VERSION ""

NS_ :

BS_:

BU_: VMCU TECU TACHO RECU_Virt IC3 HPCU EMS EBS DACU CIOM BBM ACM

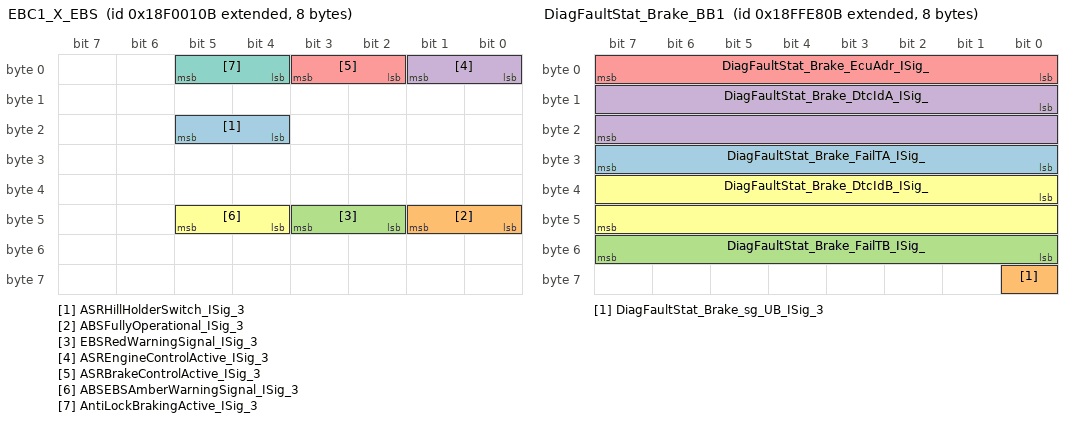
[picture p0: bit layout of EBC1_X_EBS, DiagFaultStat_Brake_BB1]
BO_ 2565865739 EBC1_X_EBS: 8 EBS
 SG_ ASRHillHolderSwitch_ISig_3 : 20|2@1+ (1,0) [0|0] ""  EMS,CIOM,IC3,BBM
 SG_ ABSFullyOperational_ISig_3 : 40|2@1+ (1,0) [0|0] ""  EMS,DACU,BBM,VMCU,TECU,IC3
 SG_ EBSRedWarningSignal_ISig_3 : 42|2@1+ (1,0) [0|0] ""  IC3,BBM
 SG_ ASREngineControlActive_ISig_3 : 0|2@1+ (1,0) [0|0] ""  BBM,EMS,VMCU,TECU
 SG_ ASRBrakeControlActive_ISig_3 : 2|2@1+ (1,0) [0|0] ""  VMCU,EMS,TECU,BBM
 SG_ ABSEBSAmberWarningSignal_ISig_3 : 44|2@1+ (1,0) [0|0] ""  BBM,IC3
 SG_ AntiLockBrakingActive_ISig_3 : 4|2@1+ (1,0) [0|0] ""  DACU,IC3,EMS,BBM,VMCU,CIOM,TECU

BO_ 2671964910 DiagUUDTRespMsg1_F2_EE_BB1: 8 TACHO
 SG_ DiagUUDTRespSig_F2_EE_ISig_3 : 0|64@1+ (1,0) [0|0] ""  VMCU

BO_ 2671964712 DiagUUDTRespMsg1_F2_28_BB1: 8 EBS
 SG_ DiagUUDTRespSig_F2_28_ISig_3 : 0|64@1+ (1,0) [0|0] ""  VMCU

BO_ 2671964689 DiagUUDTRespMsg1_F2_11_BB1: 8 ACM
 SG_ DiagUUDTRespSig_F2_11_ISig_3 : 0|64@1+ (1,0) [0|0] ""  VMCU

BO_ 2671834350 DiagRespMsgIntTGW2_F4_EE_BB1: 8 TACHO
 SG_ InternalTesterDiagSig_F4_EE_ISig : 0|64@1+ (1,0) [0|0] ""  IC3

BO_ 2671834152 DiagRespMsgIntTGW2_F4_28_BB1: 8 EBS
 SG_ InternalTesterDiagSig_F4_28_ISig : 0|64@1+ (1,0) [0|0] ""  IC3

BO_ 2671834129 DiagRespMsgIntTGW2_F4_11_BB1: 8 ACM
 SG_ InternalTesterDiagSig_F4_11_ISig : 0|64@1+ (1,0) [0|0] ""  IC3

BO_ 2671834094 DiagRespMsgIntHMIIOM_F3_EE_BB1: 8 TACHO
 SG_ InternalTesterDiagSig_F3_EE : 0|64@1+ (1,0) [0|0] ""  IC3

BO_ 2671833896 DiagRespMsgIntHMIIOM_F3_28_BB1: 8 EBS
 SG_ InternalTesterDiagSig_F3_28 : 0|64@1+ (1,0) [0|0] ""  IC3

BO_ 2671833873 DiagRespMsgIntHMIIOM_F3_11_BB1: 8 ACM
 SG_ InternalTesterDiagSig_F3_11 : 0|64@1+ (1,0) [0|0] ""  IC3

BO_ 2671832820 DiagReqMsgIntTGW2_EE_F4_BB1: 8 IC3
 SG_ InternalTesterDiagSig_EE_F4_ISig : 0|64@1+ (1,0) [0|0] ""  TACHO

BO_ 2671782132 DiagReqMsgIntTGW2_28_F4_BB1: 8 IC3
 SG_ InternalTesterDiagSig_28_F4_ISig : 0|64@1+ (1,0) [0|0] ""  EBS

BO_ 2671776244 DiagReqMsgIntTGW2_11_F4_BB1: 8 IC3
 SG_ InternalTesterDiagSig_11_F4_ISig : 0|64@1+ (1,0) [0|0] ""  ACM

BO_ 2671832819 DiagReqMsgIntHMIIOM_EE_F3_BB1: 8 IC3
 SG_ InternalTesterDiagSig_EE_F3 : 0|64@1+ (1,0) [0|0] ""  TACHO

BO_ 2671782131 DiagReqMsgIntHMIIOM_28_F3_BB1: 8 IC3
 SG_ InternalTesterDiagSig_28_F3 : 0|64@1+ (1,0) [0|0] ""  EBS

BO_ 2671776243 DiagReqMsgIntHMIIOM_11_F3_BB1: 8 IC3
 SG_ InternalTesterDiagSig_11_F3 : 0|64@1+ (1,0) [0|0] ""  ACM

BO_ 2566907915 DiagFaultStat_Brake_BB1: 8 EBS
 SG_ DiagFaultStat_Brake_FailTA_ISig_ : 24|8@1+ (1,0) [0|255] ""  IC3
 SG_ DiagFaultStat_Brake_sg_UB_ISig_3 : 56|1@1+ (1,0) [0|0] ""  IC3
 SG_ DiagFaultStat_Brake_FailTB_ISig_ : 48|8@1+ (1,0) [0|255] ""  IC3
 SG_ DiagFaultStat_Brake_DtcIdA_ISig_ : 8|16@1+ (1,0) [0|65535] ""  IC3
 SG_ DiagFaultStat_Brake_EcuAdr_ISig_ : 0|8@1+ (1,0) [0|255] ""  IC3
 SG_ DiagFaultStat_Brake_DtcIdB_ISig_ : 32|16@1+ (1,0) [0|65535] ""  IC3

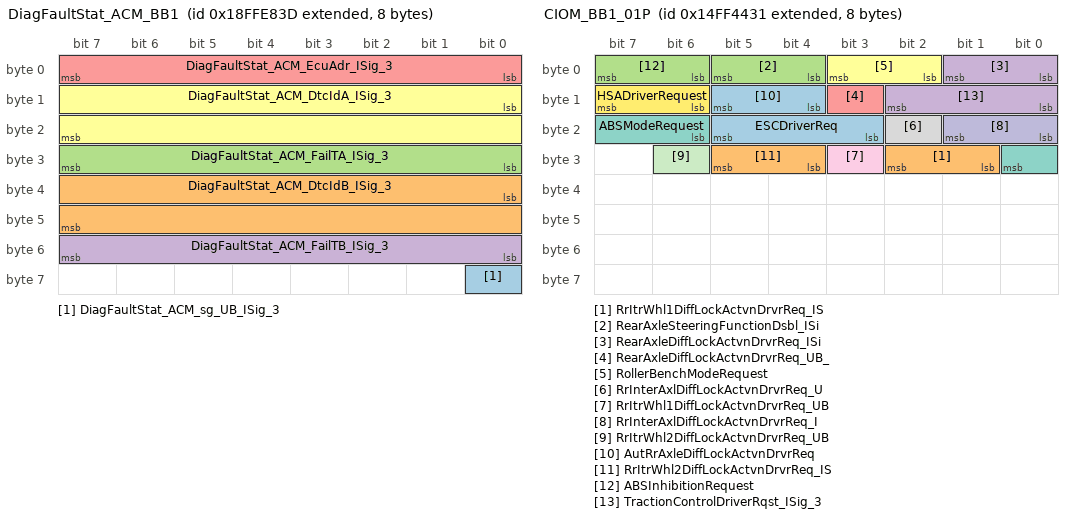
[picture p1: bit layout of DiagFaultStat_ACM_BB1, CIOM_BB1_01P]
BO_ 2566907965 DiagFaultStat_ACM_BB1: 8 ACM
 SG_ DiagFaultStat_ACM_sg_UB_ISig_3 : 56|1@1+ (1,0) [0|0] ""  IC3
 SG_ DiagFaultStat_ACM_DtcIdB_ISig_3 : 32|16@1+ (1,0) [0|65535] ""  IC3
 SG_ DiagFaultStat_ACM_FailTA_ISig_3 : 24|8@1+ (1,0) [0|255] ""  IC3
 SG_ DiagFaultStat_ACM_FailTB_ISig_3 : 48|8@1+ (1,0) [0|255] ""  IC3
 SG_ DiagFaultStat_ACM_EcuAdr_ISig_3 : 0|8@1+ (1,0) [0|255] ""  IC3
 SG_ DiagFaultStat_ACM_DtcIdA_ISig_3 : 8|16@1+ (1,0) [0|65535] ""  IC3

BO_ 2634020590 Debug6_TACHO: 8 TACHO
 SG_ Debug_6_TACHO : 0|64@1+ (1,0) [0|0] "" Vector__XXX

BO_ 2634020363 Debug6_EBS_ABS: 8 EBS
 SG_ Debug_6_EBS_ABS : 0|64@1+ (1,0) [0|0] "" Vector__XXX

BO_ 2634020413 Debug6_ACM: 8 ACM
 SG_ Debug_6_ACM : 0|64@1+ (1,0) [0|0] "" Vector__XXX

BO_ 2634020334 Debug5_TACHO: 8 TACHO
 SG_ Debug_5_TACHO : 0|64@1+ (1,0) [0|0] "" Vector__XXX

BO_ 2634020107 Debug5_EBS_ABS: 8 EBS
 SG_ Debug_5_EBS_ABS : 0|64@1+ (1,0) [0|0] "" Vector__XXX

BO_ 2634020157 Debug5_ACM: 8 ACM
 SG_ Debug_5_ACM : 0|64@1+ (1,0) [0|0] "" Vector__XXX

BO_ 2634020078 Debug4_TACHO: 8 TACHO
 SG_ Debug_4_TACHO : 0|64@1+ (1,0) [0|0] "" Vector__XXX

BO_ 2634019851 Debug4_EBS_ABS: 8 EBS
 SG_ Debug_4_EBS_ABS : 0|64@1+ (1,0) [0|0] "" Vector__XXX

BO_ 2634019901 Debug4_ACM: 8 ACM
 SG_ Debug_4_ACM : 0|64@1+ (1,0) [0|0] "" Vector__XXX

BO_ 2634019822 Debug3_TACHO: 8 TACHO
 SG_ Debug_3_TACHO : 0|64@1+ (1,0) [0|0] "" Vector__XXX

BO_ 2634019595 Debug3_EBS_ABS: 8 EBS
 SG_ Debug_3_EBS_ABS : 0|64@1+ (1,0) [0|0] "" Vector__XXX

BO_ 2634019645 Debug3_ACM: 8 ACM
 SG_ Debug_3_ACM : 0|64@1+ (1,0) [0|0] "" Vector__XXX

BO_ 2634019566 Debug2_TACHO: 8 TACHO
 SG_ Debug_2_TACHO : 0|64@1+ (1,0) [0|0] "" Vector__XXX

BO_ 2634019339 Debug2_EBS_ABS: 8 EBS
 SG_ Debug_2_EBS_ABS : 0|64@1+ (1,0) [0|0] "" Vector__XXX

BO_ 2634019389 Debug2_ACM: 8 ACM
 SG_ Debug_2_ACM : 0|64@1+ (1,0) [0|0] "" Vector__XXX

BO_ 2634019310 Debug1_TACHO: 8 Vector__XXX
 SG_ Debug_1_TACHO : 0|64@1+ (1,0) [0|0] ""  TACHO

BO_ 2634019083 Debug1_EBS_ABS: 8 Vector__XXX
 SG_ Debug_1_EBS_ABS : 0|64@1+ (1,0) [0|0] ""  EBS

BO_ 2634019133 Debug1_ACM: 8 Vector__XXX
 SG_ Debug_1_ACM : 0|64@1+ (1,0) [0|0] ""  ACM

BO_ 2566749184 DPFC1_X_EMS: 8 EMS
 SG_ DPFC1_ActiveRegeneratStatus_ISig : 10|2@1+ (1,0) [0|0] ""  TECU,IC3,VMCU,BBM
 SG_ DPFC1_LampCommand_ISig_3 : 0|3@1+ (1,0) [0|0] ""  TECU,IC3,VMCU,BBM
 SG_ DPFC1_InhibTempSystemLock_ISig_3 : 40|2@1+ (1,0) [0|0] ""  TECU,IC3,BBM,VMCU
 SG_ DPFC1_InhibOutOfNeutral_ISig_3 : 28|2@1+ (1,0) [0|0] ""  IC3,TECU,BBM,VMCU
 SG_ DPFC1_InhibEnginNotWarmUp_ISig_3 : 44|2@1+ (1,0) [0|0] ""  VMCU,IC3,BBM,TECU
 SG_ DPFC1_InhibDueInhibSwitch_ISig_3 : 18|2@1+ (1,0) [0|0] ""  TECU,VMCU,IC3,BBM
 SG_ DPFC1_InhibClutchDisengage_ISig_ : 20|2@1+ (1,0) [0|0] ""  TECU,VMCU,BBM,IC3
 SG_ DPFC1_InhibVehSpdAboveAllwdSpd_I : 30|2@1+ (1,0) [0|0] ""  TECU,IC3,BBM,VMCU
 SG_ DPFC1_ForcedStatus_ISig_3 : 53|3@1+ (1,0) [0|0] ""  IC3,BBM,TECU,VMCU
 SG_ DPFC1_InhibPTOActive_ISig_3 : 24|2@1+ (1,0) [0|0] ""  BBM,TECU,IC3,VMCU
 SG_ DPFC1_InhibVehSpdBelowAllwdSpd_I : 46|2@1+ (1,0) [0|0] ""  VMCU,IC3,TECU,BBM
 SG_ DPFC1_InhibSystemFaultAct_ISig_3 : 36|2@1+ (1,0) [0|0] ""  BBM,TECU,IC3,VMCU
 SG_ DPFC1_PassiveRegenStatus_ISig_3 : 8|2@1+ (1,0) [0|0] ""  BBM,IC3,TECU,VMCU
 SG_ DPFC1_InhibPermSystemLock_ISig_3 : 42|2@1+ (1,0) [0|0] ""  BBM,IC3,VMCU,TECU
 SG_ DPFC1_AutoARInitConfig_ISig_3 : 48|2@1+ (1,0) [0|0] ""  BBM,TECU,VMCU,IC3
 SG_ DPFC1_InhibDueLowExhGasTemp_ISig : 34|2@1+ (1,0) [0|0] ""  TECU,BBM,VMCU,IC3
 SG_ DPFC1_ExhaustSystHighTempLampCmd : 50|3@1+ (1,0) [0|0] ""  BBM,IC3,TECU,VMCU
 SG_ DPFC1_InhibitStatus_ISig_3 : 16|2@1+ (1,0) [0|0] ""  TECU,BBM,IC3,VMCU
 SG_ DPFC1_DPFStatus_ISig_3 : 12|3@1+ (1,0) [0|0] ""  TECU,IC3,VMCU,BBM
 SG_ DPFC1_InhibParkBrakeNotSet_ISig_ : 32|2@1+ (1,0) [0|0] ""  BBM,TECU,IC3,VMCU
 SG_ DPFC1_InhibDueServiceBrake_ISig_ : 22|2@1+ (1,0) [0|0] ""  BBM,VMCU,TECU,IC3
 SG_ DPFC1_InhibDueSystemTimeout_ISig : 38|2@1+ (1,0) [0|0] ""  TECU,BBM,IC3,VMCU
 SG_ DPFC1_InhibAccPedalOffIdle_ISig_ : 26|2@1+ (1,0) [0|0] ""  VMCU,IC3,TECU,BBM

BO_ 2566834691 DM1_X_TECU: 202 TECU
 SG_ DiagnosticsFaultStat_DM1_TECU : 0|1616@1+ (1,0) [0|0] ""  IC3

BO_ 2566834926 DM1_X_TACHO: 202 TACHO
 SG_ DiagnosticsFaultStat_DM1_TACHO : 0|1616@1+ (1,0) [0|0] ""  IC3

BO_ 2566834688 DM1_X_EMS: 202 EMS
 SG_ DiagnosticsFaultStat_DM1_EMS : 0|1616@1+ (1,0) [0|0] ""  IC3

BO_ 2566834749 DM1_X_ACM: 202 ACM
 SG_ DiagnosticsFaultStat_DM1_ACM : 0|1616@1+ (1,0) [0|0] ""  IC3

BO_ 2566810606 DI_X_TACHO: 40 TACHO
 SG_ DriversIdentifications : 0|320@1+ (1,0) [0|0] ""  CIOM

BO_ 2566723046 DC2_X_BBM_BB1: 8 BBM
 SG_ DriverDoorOpen_stat_ISig_3 : 2|2@1+ (1,0) [0|0] ""  DACU
 SG_ PassengerDoorOpen_stat_ISig_3 : 8|2@1+ (1,0) [0|0] ""  DACU

BO_ 2499790765 DACU_BB1_01P: 8 DACU
 SG_ ACC_SGO_Status_ISig_3 : 0|4@1+ (1,0) [0|0] ""  VMCU,EBS,IC3,TECU
 SG_ ACCHSARequest : 4|3@1+ (1,0) [0|0] ""  EBS

BO_ 2566811659 CVW_X_EBS: 8 EBS
 SG_ PoweredVehicleWeight_ISig_3 : 0|16@1+ (10,0) [0|655350] "kg"  DACU,VMCU
 SG_ GrossCombinationVehicleWeight_IS : 16|16@1+ (10,0) [0|655350] "kg"  IC3,EMS,VMCU,CIOM,TECU,DACU

BO_ 2563833623 CL_X_HMIIOM: 8 IC3
 SG_ BacklightLevelHighRes_ISig_3 : 0|8@1+ (0.4,0) [0|102] "Percent"  VMCU,TACHO,BBM

BO_ 2566843139 CI_X_TCU: 8 Vector__XXX

BO_ 2499757105 CIOM_BB1_01P: 8 CIOM
 SG_ ESCDriverReq : 19|3@1+ (1,0) [0|0] ""  EBS,IC3
 SG_ RrItrWhl1DiffLockActvnDrvrReq_IS : 25|2@1+ (1,0) [0|0] ""  EBS,VMCU
 SG_ RearAxleSteeringFunctionDsbl_ISi : 4|2@1+ (1,0) [0|0] ""  EBS,VMCU
 SG_ RearAxleDiffLockActvnDrvrReq_ISi : 0|2@1+ (1,0) [0|0] ""  VMCU,IC3,EBS
 SG_ RearAxleDiffLockActvnDrvrReq_UB_ : 11|1@1+ (1,0) [0|0] ""  IC3,VMCU,EBS
 SG_ RollerBenchModeRequest : 2|2@1+ (1,0) [0|0] ""  EBS
 SG_ ABSModeRequest : 22|3@1+ (1,0) [0|0] ""  EBS
 SG_ RrInterAxlDiffLockActvnDrvrReq_U : 18|1@1+ (1,0) [0|0] ""  VMCU,IC3,EBS
 SG_ RrItrWhl1DiffLockActvnDrvrReq_UB : 27|1@1+ (1,0) [0|0] ""  VMCU,EBS
 SG_ RrInterAxlDiffLockActvnDrvrReq_I : 16|2@1+ (1,0) [0|0] ""  EBS,VMCU,IC3
 SG_ RrItrWhl2DiffLockActvnDrvrReq_UB : 30|1@1+ (1,0) [0|0] ""  EBS,VMCU
 SG_ HSADriverRequest : 14|2@1+ (1,0) [0|0] ""  EBS
 SG_ AutRrAxleDiffLockActvnDrvrReq : 12|2@1+ (1,0) [0|0] ""  EBS,IC3
 SG_ RrItrWhl2DiffLockActvnDrvrReq_IS : 28|2@1+ (1,0) [0|0] ""  VMCU,EBS
 SG_ ABSInhibitionRequest : 6|2@1+ (1,0) [0|0] ""  EBS
 SG_ TractionControlDriverRqst_ISig_3 : 8|3@1+ (1,0) [0|0] ""  EBS,IC3

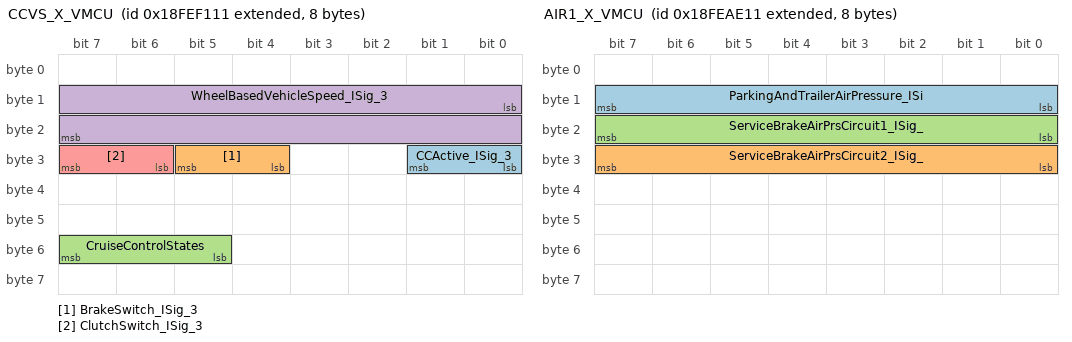
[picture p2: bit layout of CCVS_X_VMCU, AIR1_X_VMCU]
BO_ 2566844689 CCVS_X_VMCU: 8 VMCU
 SG_ CCActive_ISig_3 : 24|2@1+ (1,0) [0|0] ""  IC3,TECU,BBM,CIOM,DACU
 SG_ BrakeSwitch_ISig_3 : 28|2@1+ (1,0) [0|0] ""  EMS,CIOM,BBM,IC3,DACU,TECU
 SG_ CruiseControlStates : 53|3@1+ (1,0) [0|0] ""  TECU
 SG_ WheelBasedVehicleSpeed_ISig_3 : 8|16@1+ (0.00390625,0) [0|255.99609375] "Km_per_h"  EMS,BBM,TECU,IC3,DACU,EBS,ACM,CIOM
 SG_ ClutchSwitch_ISig_3 : 30|2@1+ (1,0) [0|0] ""  EMS,CIOM,BBM,EBS,IC3

BO_ 2499779302 BBM_BB1_01P: 8 BBM
 SG_ BBAirDumpRequest_ISig_3 : 2|2@1+ (1,0) [0|0] ""  VMCU
 SG_ CtaBs_HSABbRequest_ISig_3 : 0|2@1+ (1,0) [0|0] ""  EBS

BO_ 2566748928 AT1S_X_EMS: 8 EMS
 SG_ DPFSootLevel : 0|8@1+ (1,0) [0|255] "Percent"  IC3

BO_ 2565869312 AT1OG1_X_EMS: 8 EMS
 SG_ Aftertreat1NOxConcOutlet : 0|16@1+ (0.05,-200) [-200|3076.75] "ppm"  CIOM

BO_ 2566763008 AT1IMG_X_EMS: 8 EMS
 SG_ DPFPressureDiff : 32|16@1+ (0.1,0) [0|6553.5] "kPa"  CIOM

BO_ 2566763520 AT1IG2_X_EMS: 8 EMS
 SG_ Aftertreatment1ExhaustTemp1 : 0|16@1+ (0.03125,-273) [-273|1774.96875] "DegreeC"  CIOM

BO_ 2565869056 AT1IG1_X_EMS: 8 EMS
 SG_ EngineExhaust1NOx1 : 0|16@1+ (0.05,-200) [-200|3076.75] "ppm"  CIOM

BO_ 2566845713 AMB_X_VMCU: 8 VMCU
 SG_ AmbientAirTemperature_ISig_3 : 24|16@1+ (0.03125,-273) [-273|1774.96875] "DegreeC"  CIOM,IC3,BBM,EBS,TECU,DACU,EMS,ACM

BO_ 2566827537 AIR1_X_VMCU: 8 VMCU
 SG_ ParkingAndTrailerAirPressure_ISi : 8|8@1+ (8,0) [0|2040] "kPa"  EBS,BBM
 SG_ ServiceBrakeAirPrsCircuit2_ISig_ : 24|8@1+ (8,0) [0|2040] "kPa"  ACM,TECU,EMS,IC3,EBS,BBM,CIOM
 SG_ ServiceBrakeAirPrsCircuit1_ISig_ : 16|8@1+ (8,0) [0|2040] "kPa"  IC3,ACM,BBM,TECU,EBS,CIOM,EMS

BO_ 2565799683 AC_X_TCU: 8 Vector__XXX

BO_ 2565799685 AC_X_GSSA: 8 Vector__XXX

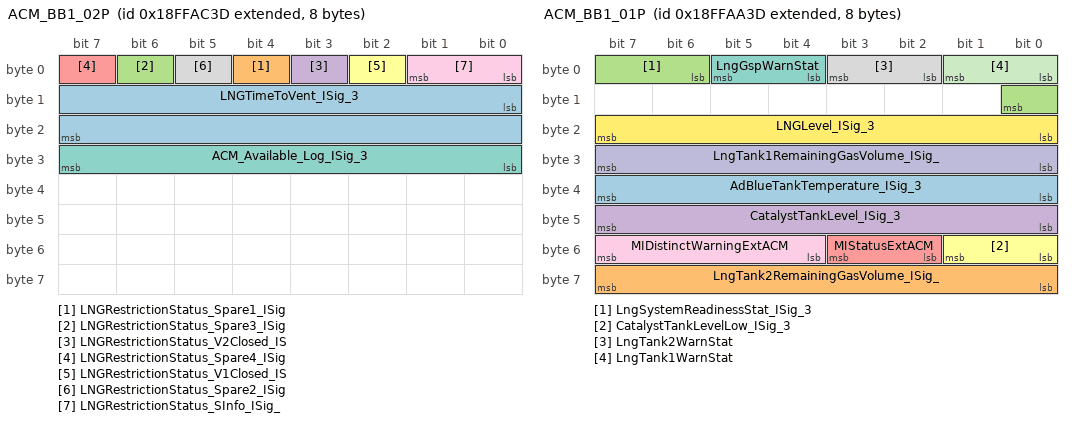
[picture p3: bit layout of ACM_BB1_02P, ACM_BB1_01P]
BO_ 2566892605 ACM_BB1_02P: 8 ACM
 SG_ LNGTimeToVent_ISig_3 : 8|16@1+ (1,0) [0|65535] "min"  IC3
 SG_ LNGRestrictionStatus_Spare1_ISig : 4|1@1+ (1,0) [0|0] ""  IC3
 SG_ LNGRestrictionStatus_Spare3_ISig : 6|1@1+ (1,0) [0|0] ""  IC3
 SG_ LNGRestrictionStatus_V2Closed_IS : 3|1@1+ (1,0) [0|0] ""  IC3
 SG_ LNGRestrictionStatus_Spare4_ISig : 7|1@1+ (1,0) [0|0] ""  IC3
 SG_ LNGRestrictionStatus_V1Closed_IS : 2|1@1+ (1,0) [0|0] ""  IC3
 SG_ ACM_Available_Log_ISig_3 : 24|8@1+ (1,0) [0|0] ""  IC3
 SG_ LNGRestrictionStatus_Spare2_ISig : 5|1@1+ (1,0) [0|0] ""  IC3
 SG_ LNGRestrictionStatus_SInfo_ISig_ : 0|2@1+ (1,0) [0|0] ""  IC3

BO_ 2566892093 ACM_BB1_01P: 8 ACM
 SG_ AdBlueTankTemperature_ISig_3 : 32|8@1+ (1,-50) [-50|205] "DegreeC"  VMCU,IC3,BBM
 SG_ LngTank2RemainingGasVolume_ISig_ : 56|8@1+ (0.4,0) [0|102] "Percent"  IC3,VMCU,CIOM
 SG_ LngSystemReadinessStat_ISig_3 : 6|3@1+ (1,0) [0|0] ""  IC3
 SG_ CatalystTankLevel_ISig_3 : 40|8@1+ (0.4,0) [0|102] "Percent"  BBM,EMS,CIOM,IC3
 SG_ MIStatusExtACM : 50|2@1+ (1,0) [0|0] ""  EMS
 SG_ CatalystTankLevelLow_ISig_3 : 48|2@1+ (1,0) [0|0] ""  VMCU,IC3,EMS
 SG_ LngGspWarnStat : 4|2@1+ (1,0) [0|0] ""  IC3
 SG_ LngTank2WarnStat : 2|2@1+ (1,0) [0|0] ""  IC3
 SG_ MIDistinctWarningExtACM : 52|4@1+ (1,0) [0|0] ""  EMS
 SG_ LngTank1RemainingGasVolume_ISig_ : 24|8@1+ (0.4,0) [0|102] "Percent"  IC3,VMCU,CIOM
 SG_ LngTank1WarnStat : 0|2@1+ (1,0) [0|0] ""  IC3
 SG_ LNGLevel_ISig_3 : 16|8@1+ (0.4,0) [0|102] "Percent"  IC3

BO_ 2565406467 ACK_X_TCU: 8 Vector__XXX

BO_ 2632515566 ACK_X_TACHO_LowPrio: 8 TACHO
 SG_ AckTACHOControlSig_LowPrio : 0|64@1+ (1,0) [0|0] "" Vector__XXX

BO_ 2565406702 ACK_X_TACHO: 8 TACHO
 SG_ AckTACHOControlSig : 0|64@1+ (1,0) [0|0] "" Vector__XXX

BO_ 2499624448 A1SCREGT1_X_EMS: 8 EMS
 SG_ SCRInletTemp : 0|16@1+ (0.03125,-273) [-273|1774.96875] "DegreeC"  CIOM
 SG_ SCROutletTemp : 24|16@1+ (0.03125,-273) [-273|1774.96875] "DegreeC"  CIOM

CM_ BO_ 2565865739 "PGN 61441 Electronic Brake Controller 1";
CM_ BO_ 2566749184 "PGN 64892 Diesel Particulate Filter Control 1";
CM_ BO_ 2566834691 "PGN 65226 Active Diagnostic Trouble Codes";
CM_ BO_ 2566834926 "PGN 65226 Active Diagnostic Trouble Codes";
CM_ BO_ 2566834688 "PGN 65226 Active Diagnostic Trouble Codes";
CM_ BO_ 2566834749 "PGN 65226 Active Diagnostic Trouble Codes";
CM_ BO_ 2566810606 "PGN 65131 Drivers Identification";
CM_ BO_ 2566811659 "PGN 64872 Gross Combination Vehicle Weight";
CM_ SG_ 2566811659 PoweredVehicleWeight_ISig_3 "65024 - 65279 Error ; 65280 - 65535 Not available";
CM_ SG_ 2566811659 GrossCombinationVehicleWeight_IS "65024 - 65279 Error ; 65280 - 65535 Not available";
CM_ BO_ 2563833623 "PGN 53248 Cab Illumination Message";
CM_ SG_ 2563833623 BacklightLevelHighRes_ISig_3 "254 Error ; 255 Not available";
CM_ BO_ 2566843139 "PGN 65259 Component Identification";
CM_ BO_ 2566844689 "PGN 65265 Cruise Control/Vehicle Speed";
CM_ SG_ 2566844689 WheelBasedVehicleSpeed_ISig_3 "65024 - 65279 Error ; 65280 - 65535 Not available";
CM_ BO_ 2566748928 "PGN 64891 Aftertreatment 1 Service";
CM_ SG_ 2566748928 DPFSootLevel "254 Error ; 255 Not available";
CM_ BO_ 2565869312 "PGN 61455 Aftertreatment 1 Outlet Gas 1
Note: SAE recommended rate 50ms, but 500ms set due to current usage only for logging.";
CM_ BO_ 2566763008 "PGN 64946 Aftertreatment 1 Intermediate Gas";
CM_ BO_ 2566763520 "PGN 64948 Aftertreatment 1 Intake Gas 2";
CM_ BO_ 2565869056 "PGN 61454 Aftertreatment 1 Intake Gas 1
Note: SAE recommended rate 50ms, but 500ms set due to current usage only for logging.";
CM_ BO_ 2566845713 "PGN 65269 Ambient Conditions";
CM_ SG_ 2566845713 AmbientAirTemperature_ISig_3 "65024 - 65279 Error ; 65280 - 65535 Not available";
CM_ BO_ 2566827537 "PGN 65198 Air Supply Pressure, Sporadic because cyclic before gateway";
CM_ SG_ 2566827537 ParkingAndTrailerAirPressure_ISi "254 Error ; 255 Not available";
CM_ SG_ 2566827537 ServiceBrakeAirPrsCircuit2_ISig_ "254 Error ; 255 Not available";
CM_ SG_ 2566827537 ServiceBrakeAirPrsCircuit1_ISig_ "254 Error ; 255 Not available";
CM_ BO_ 2565799683 "PGN60928 Address Claimed from  Transmission ECU";
CM_ BO_ 2565799685 "PGN60928 Address Claimed from Gearshift selector";
CM_ SG_ 2566892093 LngTank2RemainingGasVolume_ISig_ "254 Error ; 255 Not available";
CM_ SG_ 2566892093 CatalystTankLevel_ISig_3 "254 Error ; 255 Not available";
CM_ SG_ 2566892093 LngTank1RemainingGasVolume_ISig_ "254 Error ; 255 Not available";
CM_ SG_ 2566892093 LNGLevel_ISig_3 "254 Error ; 255 Not available";
CM_ BO_ 2565406467 "PGN 59392 Acknowledgement from Transmission ECU";
CM_ SG_ 2632515566 AckTACHOControlSig_LowPrio "Signal with content J1939 PGN 59392 Parameter Group Name: Acknowledgment";
CM_ SG_ 2565406702 AckTACHOControlSig "Signal with content J1939 PGN 59392 Parameter Group Name: Acknowledgment";
CM_ BO_ 2499624448 "PGN 64830 Aftertreatment 1 SCR Exhaust Gas Temperature 1";
BA_DEF_ BO_  "GenMsgStartDelayTime" INT 0 0;
BA_DEF_ BO_  "GenMsgDelayTime" INT 0 0;
BA_DEF_ BO_  "GenMsgNrOfRepetition" INT 0 0;
BA_DEF_ BO_  "GenMsgCycleTimeFast" INT 0 0;
BA_DEF_ BO_  "GenMsgCycleTime" INT 0 0;
BA_DEF_ BO_  "GenMsgSendType" ENUM  "Cyclic","NotUsed","NotUsed","NotUsed","NotUsed","NotUsed","NotUsed","IfActive","NoMsgSendType","NotUsed";
BA_DEF_ SG_  "GenSigStartValue" INT 0 0;
BA_DEF_ SG_  "GenSigCycleTimeActive" INT 0 0;
BA_DEF_ SG_  "GenSigCycleTime" INT 0 0;
BA_DEF_ SG_  "GenSigSendType" ENUM  "Cyclic","OnWrite","OnWriteWithRepetition","OnChange","OnChangeWithRepetition","IfActive","IfActiveWithRepetition","NoSigSendType","NotUsed","NotUsed","NotUsed","NotUsed","NotUsed";
BA_DEF_ BO_  "VFrameFormat" ENUM  "StandardCAN","ExtendedCAN","reserved","J1939PG","reserved","reserved","reserved","reserved","reserved","reserved","reserved","reserved","reserved","reserved","StandardCAN_FD","ExtendedCAN_FD";
BA_DEF_ BO_  "TpJ1939VarDlc" ENUM  "No","Yes";
BA_DEF_ SG_  "SigType" ENUM  "Default","Range","RangeSigned","ASCII","Discrete","Control","ReferencePGN","DTC","StringDelimiter","StringLength","StringLengthControl";
BA_DEF_ SG_  "SeToolVersion_SIGNAL" STRING ;
BA_DEF_ SG_  "SeToolUniqueID_SIGNAL" STRING ;
BA_DEF_ SG_  "SeToolOwnerSigGroup_SIGNAL" STRING ;
BA_DEF_ SG_  "SeToolOwnerSigGroupID_SIGNAL" STRING ;
BA_DEF_ SG_  "SeToolName_SIGNAL" STRING ;
BA_DEF_ SG_  "SeToolItemID_SIGNAL" STRING ;
BA_DEF_ SG_  "SeToolAncestorID_SIGNAL" STRING ;
BA_DEF_ SG_  "SPN" INT 0 524287;
BA_DEF_ SG_  "Platform_VMCU1_Sig" ENUM  "No","Yes";
BA_DEF_ SG_  "Platform_FactoryIf_Sig" ENUM  "No","Yes";
BA_DEF_ SG_  "NeedsUpdateBit" ENUM  "No","Yes";
BA_DEF_ SG_  "GenSigMaxLatency" INT 0 65535;
BA_DEF_ SG_  "GenSigILSupport" ENUM  "Yes","No";
BA_DEF_ BO_  "GenMsgILSupport" ENUM  "No","Yes";
BA_DEF_ BO_  "DiagUUDTResponse" ENUM  "No","Yes";
BA_DEF_ BO_  "DiagState" ENUM  "No","Yes";
BA_DEF_ BO_  "DiagResponse" ENUM  "No","Yes";
BA_DEF_ BO_  "DiagRequest" ENUM  "No","Yes";
BA_DEF_ BO_  "DiagConnection" HEX 0 65535;
BA_DEF_ BO_  "CanTpFcFrameId" HEX 0 2147483647;
BA_DEF_ BO_  "CanTpBs" INT 0 255;
BA_DEF_ SG_  "SystemSignalLongSymbol" STRING ;
BA_DEF_REL_ BU_SG_REL_  "GenSigTimeoutTime" INT 0 65535;
BA_DEF_REL_ BU_SG_REL_  "GenSigFirstTimeoutTime" INT 0 65535;
BA_DEF_DEF_  "GenMsgStartDelayTime" 0;
BA_DEF_DEF_  "GenMsgDelayTime" 0;
BA_DEF_DEF_  "GenMsgNrOfRepetition" 0;
BA_DEF_DEF_  "GenMsgCycleTimeFast" 0;
BA_DEF_DEF_  "GenMsgCycleTime" 0;
BA_DEF_DEF_  "GenMsgSendType" "Cyclic";
BA_DEF_DEF_  "GenSigStartValue" 0;
BA_DEF_DEF_  "GenSigCycleTimeActive" 0;
BA_DEF_DEF_  "GenSigCycleTime" 0;
BA_DEF_DEF_  "GenSigSendType" "Cyclic";
BA_DEF_DEF_  "VFrameFormat" "ExtendedCAN";
BA_DEF_DEF_  "TpJ1939VarDlc" "No";
BA_DEF_DEF_  "SigType" "Default";
BA_DEF_DEF_  "SeToolVersion_SIGNAL" "";
BA_DEF_DEF_  "SeToolUniqueID_SIGNAL" "";
BA_DEF_DEF_  "SeToolOwnerSigGroup_SIGNAL" "";
BA_DEF_DEF_  "SeToolOwnerSigGroupID_SIGNAL" "";
BA_DEF_DEF_  "SeToolName_SIGNAL" "";
BA_DEF_DEF_  "SeToolItemID_SIGNAL" "";
BA_DEF_DEF_  "SeToolAncestorID_SIGNAL" "";
BA_DEF_DEF_  "SPN" 0;
BA_DEF_DEF_  "Platform_VMCU1_Sig" "No";
BA_DEF_DEF_  "Platform_FactoryIf_Sig" "No";
BA_DEF_DEF_  "NeedsUpdateBit" "No";
BA_DEF_DEF_  "GenSigMaxLatency" 0;
BA_DEF_DEF_  "GenSigILSupport" "Yes";
BA_DEF_DEF_  "GenMsgILSupport" "Yes";
BA_DEF_DEF_  "DiagUUDTResponse" "No";
BA_DEF_DEF_  "DiagState" "No";
BA_DEF_DEF_  "DiagResponse" "No";
BA_DEF_DEF_  "DiagRequest" "No";
BA_DEF_DEF_  "DiagConnection" 0;
BA_DEF_DEF_  "CanTpFcFrameId" 2147483647;
BA_DEF_DEF_  "CanTpBs" 255;
BA_DEF_DEF_REL_ "GenSigTimeoutTime" 0;
BA_DEF_DEF_REL_ "GenSigFirstTimeoutTime" 0;
BA_DEF_DEF_  "SystemSignalLongSymbol" "";
BA_ "GenMsgCycleTime" BO_ 2565865739 100;
BA_ "GenMsgStartDelayTime" BO_ 2565865739 30;
BA_ "VFrameFormat" BO_ 2565865739 3;
BA_ "DiagConnection" BO_ 2671964910 62190;
BA_ "DiagUUDTResponse" BO_ 2671964910 1;
BA_ "GenMsgILSupport" BO_ 2671964910 0;
BA_ "GenMsgSendType" BO_ 2671964910 8;
BA_ "VFrameFormat" BO_ 2671964910 3;
BA_ "DiagConnection" BO_ 2671964712 61992;
BA_ "DiagUUDTResponse" BO_ 2671964712 1;
BA_ "GenMsgILSupport" BO_ 2671964712 0;
BA_ "GenMsgSendType" BO_ 2671964712 8;
BA_ "VFrameFormat" BO_ 2671964712 3;
BA_ "DiagConnection" BO_ 2671964689 61969;
BA_ "DiagUUDTResponse" BO_ 2671964689 1;
BA_ "GenMsgILSupport" BO_ 2671964689 0;
BA_ "GenMsgSendType" BO_ 2671964689 8;
BA_ "VFrameFormat" BO_ 2671964689 3;
BA_ "DiagConnection" BO_ 2671834350 62702;
BA_ "DiagResponse" BO_ 2671834350 1;
BA_ "GenMsgILSupport" BO_ 2671834350 0;
BA_ "GenMsgSendType" BO_ 2671834350 8;
BA_ "VFrameFormat" BO_ 2671834350 3;
BA_ "DiagConnection" BO_ 2671834152 62504;
BA_ "DiagResponse" BO_ 2671834152 1;
BA_ "GenMsgILSupport" BO_ 2671834152 0;
BA_ "GenMsgSendType" BO_ 2671834152 8;
BA_ "VFrameFormat" BO_ 2671834152 3;
BA_ "DiagConnection" BO_ 2671834129 62481;
BA_ "DiagResponse" BO_ 2671834129 1;
BA_ "GenMsgILSupport" BO_ 2671834129 0;
BA_ "GenMsgSendType" BO_ 2671834129 8;
BA_ "VFrameFormat" BO_ 2671834129 3;
BA_ "DiagConnection" BO_ 2671834094 62446;
BA_ "DiagResponse" BO_ 2671834094 1;
BA_ "GenMsgILSupport" BO_ 2671834094 0;
BA_ "GenMsgSendType" BO_ 2671834094 8;
BA_ "VFrameFormat" BO_ 2671834094 3;
BA_ "DiagConnection" BO_ 2671833896 62248;
BA_ "DiagResponse" BO_ 2671833896 1;
BA_ "GenMsgILSupport" BO_ 2671833896 0;
BA_ "GenMsgSendType" BO_ 2671833896 8;
BA_ "VFrameFormat" BO_ 2671833896 3;
BA_ "DiagConnection" BO_ 2671833873 62225;
BA_ "DiagResponse" BO_ 2671833873 1;
BA_ "GenMsgILSupport" BO_ 2671833873 0;
BA_ "GenMsgSendType" BO_ 2671833873 8;
BA_ "VFrameFormat" BO_ 2671833873 3;
BA_ "DiagConnection" BO_ 2671832820 62702;
BA_ "DiagRequest" BO_ 2671832820 1;
BA_ "GenMsgILSupport" BO_ 2671832820 0;
BA_ "GenMsgSendType" BO_ 2671832820 8;
BA_ "VFrameFormat" BO_ 2671832820 3;
BA_ "DiagConnection" BO_ 2671782132 62504;
BA_ "DiagRequest" BO_ 2671782132 1;
BA_ "GenMsgILSupport" BO_ 2671782132 0;
BA_ "GenMsgSendType" BO_ 2671782132 8;
BA_ "VFrameFormat" BO_ 2671782132 3;
BA_ "DiagConnection" BO_ 2671776244 62481;
BA_ "DiagRequest" BO_ 2671776244 1;
BA_ "GenMsgILSupport" BO_ 2671776244 0;
BA_ "GenMsgSendType" BO_ 2671776244 8;
BA_ "VFrameFormat" BO_ 2671776244 3;
BA_ "DiagConnection" BO_ 2671832819 62446;
BA_ "DiagRequest" BO_ 2671832819 1;
BA_ "GenMsgILSupport" BO_ 2671832819 0;
BA_ "GenMsgSendType" BO_ 2671832819 8;
BA_ "VFrameFormat" BO_ 2671832819 3;
BA_ "DiagConnection" BO_ 2671782131 62248;
BA_ "DiagRequest" BO_ 2671782131 1;
BA_ "GenMsgILSupport" BO_ 2671782131 0;
BA_ "GenMsgSendType" BO_ 2671782131 8;
BA_ "VFrameFormat" BO_ 2671782131 3;
BA_ "DiagConnection" BO_ 2671776243 62225;
BA_ "DiagRequest" BO_ 2671776243 1;
BA_ "GenMsgILSupport" BO_ 2671776243 0;
BA_ "GenMsgSendType" BO_ 2671776243 8;
BA_ "VFrameFormat" BO_ 2671776243 3;
BA_ "GenMsgCycleTime" BO_ 2566907915 1000;
BA_ "GenMsgDelayTime" BO_ 2566907915 85;
BA_ "GenMsgStartDelayTime" BO_ 2566907915 85;
BA_ "VFrameFormat" BO_ 2566907915 3;
BA_ "GenMsgCycleTime" BO_ 2566907965 1000;
BA_ "GenMsgDelayTime" BO_ 2566907965 85;
BA_ "GenMsgStartDelayTime" BO_ 2566907965 5;
BA_ "VFrameFormat" BO_ 2566907965 3;
BA_ "GenMsgSendType" BO_ 2634020590 8;
BA_ "GenMsgDelayTime" BO_ 2634020590 100;
BA_ "GenMsgStartDelayTime" BO_ 2634020590 50;
BA_ "VFrameFormat" BO_ 2634020590 3;
BA_ "GenMsgSendType" BO_ 2634020363 8;
BA_ "GenMsgDelayTime" BO_ 2634020363 40;
BA_ "GenMsgStartDelayTime" BO_ 2634020363 50;
BA_ "VFrameFormat" BO_ 2634020363 3;
BA_ "GenMsgSendType" BO_ 2634020413 8;
BA_ "GenMsgDelayTime" BO_ 2634020413 50;
BA_ "GenMsgStartDelayTime" BO_ 2634020413 50;
BA_ "VFrameFormat" BO_ 2634020413 3;
BA_ "GenMsgSendType" BO_ 2634020334 8;
BA_ "GenMsgDelayTime" BO_ 2634020334 100;
BA_ "GenMsgStartDelayTime" BO_ 2634020334 50;
BA_ "VFrameFormat" BO_ 2634020334 3;
BA_ "GenMsgSendType" BO_ 2634020107 8;
BA_ "GenMsgDelayTime" BO_ 2634020107 40;
BA_ "GenMsgStartDelayTime" BO_ 2634020107 50;
BA_ "VFrameFormat" BO_ 2634020107 3;
BA_ "GenMsgSendType" BO_ 2634020157 8;
BA_ "GenMsgDelayTime" BO_ 2634020157 50;
BA_ "GenMsgStartDelayTime" BO_ 2634020157 50;
BA_ "VFrameFormat" BO_ 2634020157 3;
BA_ "GenMsgSendType" BO_ 2634020078 8;
BA_ "GenMsgDelayTime" BO_ 2634020078 100;
BA_ "GenMsgStartDelayTime" BO_ 2634020078 50;
BA_ "VFrameFormat" BO_ 2634020078 3;
BA_ "GenMsgSendType" BO_ 2634019851 8;
BA_ "GenMsgDelayTime" BO_ 2634019851 40;
BA_ "GenMsgStartDelayTime" BO_ 2634019851 50;
BA_ "VFrameFormat" BO_ 2634019851 3;
BA_ "GenMsgSendType" BO_ 2634019901 8;
BA_ "GenMsgDelayTime" BO_ 2634019901 50;
BA_ "GenMsgStartDelayTime" BO_ 2634019901 50;
BA_ "VFrameFormat" BO_ 2634019901 3;
BA_ "GenMsgSendType" BO_ 2634019822 8;
BA_ "GenMsgDelayTime" BO_ 2634019822 100;
BA_ "GenMsgStartDelayTime" BO_ 2634019822 50;
BA_ "VFrameFormat" BO_ 2634019822 3;
BA_ "GenMsgSendType" BO_ 2634019595 8;
BA_ "GenMsgDelayTime" BO_ 2634019595 40;
BA_ "GenMsgStartDelayTime" BO_ 2634019595 50;
BA_ "VFrameFormat" BO_ 2634019595 3;
BA_ "GenMsgSendType" BO_ 2634019645 8;
BA_ "GenMsgDelayTime" BO_ 2634019645 50;
BA_ "GenMsgStartDelayTime" BO_ 2634019645 50;
BA_ "VFrameFormat" BO_ 2634019645 3;
BA_ "GenMsgSendType" BO_ 2634019566 8;
BA_ "GenMsgDelayTime" BO_ 2634019566 100;
BA_ "GenMsgStartDelayTime" BO_ 2634019566 50;
BA_ "VFrameFormat" BO_ 2634019566 3;
BA_ "GenMsgSendType" BO_ 2634019339 8;
BA_ "GenMsgDelayTime" BO_ 2634019339 40;
BA_ "GenMsgStartDelayTime" BO_ 2634019339 50;
BA_ "VFrameFormat" BO_ 2634019339 3;
BA_ "GenMsgSendType" BO_ 2634019389 8;
BA_ "GenMsgDelayTime" BO_ 2634019389 50;
BA_ "GenMsgStartDelayTime" BO_ 2634019389 50;
BA_ "VFrameFormat" BO_ 2634019389 3;
BA_ "VFrameFormat" BO_ 2634019310 3;
BA_ "VFrameFormat" BO_ 2634019083 3;
BA_ "VFrameFormat" BO_ 2634019133 3;
BA_ "GenMsgCycleTime" BO_ 2566749184 1000;
BA_ "GenMsgDelayTime" BO_ 2566749184 100;
BA_ "GenMsgStartDelayTime" BO_ 2566749184 335;
BA_ "VFrameFormat" BO_ 2566749184 3;
BA_ "TpJ1939VarDlc" BO_ 2566834691 1;
BA_ "GenMsgCycleTime" BO_ 2566834691 1000;
BA_ "GenMsgStartDelayTime" BO_ 2566834691 30;
BA_ "VFrameFormat" BO_ 2566834691 3;
BA_ "TpJ1939VarDlc" BO_ 2566834926 1;
BA_ "GenMsgCycleTime" BO_ 2566834926 1000;
BA_ "VFrameFormat" BO_ 2566834926 3;
BA_ "TpJ1939VarDlc" BO_ 2566834688 1;
BA_ "GenMsgCycleTime" BO_ 2566834688 1000;
BA_ "GenMsgStartDelayTime" BO_ 2566834688 240;
BA_ "VFrameFormat" BO_ 2566834688 3;
BA_ "TpJ1939VarDlc" BO_ 2566834749 1;
BA_ "GenMsgCycleTime" BO_ 2566834749 1000;
BA_ "GenMsgStartDelayTime" BO_ 2566834749 105;
BA_ "VFrameFormat" BO_ 2566834749 3;
BA_ "TpJ1939VarDlc" BO_ 2566810606 1;
BA_ "GenMsgSendType" BO_ 2566810606 8;
BA_ "VFrameFormat" BO_ 2566810606 3;
BA_ "GenMsgCycleTime" BO_ 2566723046 100;
BA_ "GenMsgStartDelayTime" BO_ 2566723046 5;
BA_ "VFrameFormat" BO_ 2566723046 3;
BA_ "GenMsgCycleTime" BO_ 2499790765 100;
BA_ "GenMsgStartDelayTime" BO_ 2499790765 5;
BA_ "VFrameFormat" BO_ 2499790765 3;
BA_ "GenMsgCycleTime" BO_ 2566811659 2000;
BA_ "GenMsgStartDelayTime" BO_ 2566811659 475;
BA_ "VFrameFormat" BO_ 2566811659 3;
BA_ "GenMsgCycleTime" BO_ 2563833623 1000;
BA_ "GenMsgDelayTime" BO_ 2563833623 195;
BA_ "GenMsgStartDelayTime" BO_ 2563833623 25;
BA_ "VFrameFormat" BO_ 2563833623 3;
BA_ "TpJ1939VarDlc" BO_ 2566843139 1;
BA_ "VFrameFormat" BO_ 2566843139 3;
BA_ "GenMsgCycleTime" BO_ 2499757105 50;
BA_ "VFrameFormat" BO_ 2499757105 3;
BA_ "GenMsgCycleTime" BO_ 2566844689 100;
BA_ "GenMsgStartDelayTime" BO_ 2566844689 5;
BA_ "VFrameFormat" BO_ 2566844689 3;
BA_ "GenMsgCycleTime" BO_ 2499779302 100;
BA_ "GenMsgStartDelayTime" BO_ 2499779302 50;
BA_ "VFrameFormat" BO_ 2499779302 3;
BA_ "GenMsgCycleTime" BO_ 2566748928 1000;
BA_ "GenMsgStartDelayTime" BO_ 2566748928 145;
BA_ "VFrameFormat" BO_ 2566748928 3;
BA_ "GenMsgCycleTime" BO_ 2565869312 500;
BA_ "GenMsgStartDelayTime" BO_ 2565869312 70;
BA_ "VFrameFormat" BO_ 2565869312 3;
BA_ "GenMsgCycleTime" BO_ 2566763008 500;
BA_ "GenMsgStartDelayTime" BO_ 2566763008 430;
BA_ "VFrameFormat" BO_ 2566763008 3;
BA_ "GenMsgCycleTime" BO_ 2566763520 500;
BA_ "GenMsgStartDelayTime" BO_ 2566763520 315;
BA_ "VFrameFormat" BO_ 2566763520 3;
BA_ "GenMsgCycleTime" BO_ 2565869056 500;
BA_ "GenMsgStartDelayTime" BO_ 2565869056 220;
BA_ "VFrameFormat" BO_ 2565869056 3;
BA_ "GenMsgCycleTime" BO_ 2566845713 1000;
BA_ "GenMsgStartDelayTime" BO_ 2566845713 145;
BA_ "VFrameFormat" BO_ 2566845713 3;
BA_ "GenMsgSendType" BO_ 2566827537 8;
BA_ "GenMsgDelayTime" BO_ 2566827537 900;
BA_ "VFrameFormat" BO_ 2566827537 3;
BA_ "VFrameFormat" BO_ 2565799683 3;
BA_ "VFrameFormat" BO_ 2565799685 3;
BA_ "GenMsgCycleTime" BO_ 2566892605 1000;
BA_ "GenMsgStartDelayTime" BO_ 2566892605 50;
BA_ "VFrameFormat" BO_ 2566892605 3;
BA_ "GenMsgCycleTime" BO_ 2566892093 1000;
BA_ "VFrameFormat" BO_ 2566892093 3;
BA_ "VFrameFormat" BO_ 2565406467 3;
BA_ "GenMsgSendType" BO_ 2632515566 8;
BA_ "VFrameFormat" BO_ 2632515566 3;
BA_ "GenMsgSendType" BO_ 2565406702 8;
BA_ "VFrameFormat" BO_ 2565406702 3;
BA_ "GenMsgCycleTime" BO_ 2499624448 500;
BA_ "GenMsgStartDelayTime" BO_ 2499624448 105;
BA_ "VFrameFormat" BO_ 2499624448 3;
BA_ "GenSigCycleTime" SG_ 2565865739 ASRHillHolderSwitch_ISig_3 100;
BA_ "GenSigCycleTimeActive" SG_ 2565865739 ASRHillHolderSwitch_ISig_3 100;
BA_ "GenSigStartValue" SG_ 2565865739 ASRHillHolderSwitch_ISig_3 3;
BA_ "Platform_VMCU1_Sig" SG_ 2565865739 ASRHillHolderSwitch_ISig_3 1;
BA_ "SPN" SG_ 2565865739 ASRHillHolderSwitch_ISig_3 577;
BA_ "SeToolAncestorID_SIGNAL" SG_ 2565865739 ASRHillHolderSwitch_ISig_3 "x0000001D0410DBE2";
BA_ "SeToolItemID_SIGNAL" SG_ 2565865739 ASRHillHolderSwitch_ISig_3 "x0000001D043C87C6";
BA_ "SeToolName_SIGNAL" SG_ 2565865739 ASRHillHolderSwitch_ISig_3 "ASRHillHolderSwitch";
BA_ "SeToolVersion_SIGNAL" SG_ 2565865739 ASRHillHolderSwitch_ISig_3 "2";
BA_ "GenSigCycleTime" SG_ 2565865739 ABSFullyOperational_ISig_3 100;
BA_ "GenSigCycleTimeActive" SG_ 2565865739 ABSFullyOperational_ISig_3 100;
BA_ "GenSigStartValue" SG_ 2565865739 ABSFullyOperational_ISig_3 3;
BA_ "Platform_VMCU1_Sig" SG_ 2565865739 ABSFullyOperational_ISig_3 1;
BA_ "SPN" SG_ 2565865739 ABSFullyOperational_ISig_3 1243;
BA_ "SeToolAncestorID_SIGNAL" SG_ 2565865739 ABSFullyOperational_ISig_3 "x0000001D0410DB72";
BA_ "SeToolItemID_SIGNAL" SG_ 2565865739 ABSFullyOperational_ISig_3 "x0000001D0410DB72";
BA_ "SeToolName_SIGNAL" SG_ 2565865739 ABSFullyOperational_ISig_3 "ABSFullyOperational";
BA_ "SeToolVersion_SIGNAL" SG_ 2565865739 ABSFullyOperational_ISig_3 "1";
BA_ "GenSigCycleTime" SG_ 2565865739 EBSRedWarningSignal_ISig_3 100;
BA_ "GenSigCycleTimeActive" SG_ 2565865739 EBSRedWarningSignal_ISig_3 100;
BA_ "GenSigStartValue" SG_ 2565865739 EBSRedWarningSignal_ISig_3 3;
BA_ "Platform_VMCU1_Sig" SG_ 2565865739 EBSRedWarningSignal_ISig_3 1;
BA_ "SPN" SG_ 2565865739 EBSRedWarningSignal_ISig_3 1439;
BA_ "GenSigCycleTime" SG_ 2565865739 ASREngineControlActive_ISig_3 100;
BA_ "GenSigCycleTimeActive" SG_ 2565865739 ASREngineControlActive_ISig_3 100;
BA_ "GenSigStartValue" SG_ 2565865739 ASREngineControlActive_ISig_3 3;
BA_ "Platform_VMCU1_Sig" SG_ 2565865739 ASREngineControlActive_ISig_3 1;
BA_ "SPN" SG_ 2565865739 ASREngineControlActive_ISig_3 561;
BA_ "SeToolAncestorID_SIGNAL" SG_ 2565865739 ASREngineControlActive_ISig_3 "x0000001D04125C4F";
BA_ "SeToolItemID_SIGNAL" SG_ 2565865739 ASREngineControlActive_ISig_3 "x0000001D04125C4F";
BA_ "SeToolName_SIGNAL" SG_ 2565865739 ASREngineControlActive_ISig_3 "ASREngineControlActive";
BA_ "SeToolVersion_SIGNAL" SG_ 2565865739 ASREngineControlActive_ISig_3 "1";
BA_ "GenSigCycleTime" SG_ 2565865739 ASRBrakeControlActive_ISig_3 100;
BA_ "GenSigCycleTimeActive" SG_ 2565865739 ASRBrakeControlActive_ISig_3 100;
BA_ "GenSigStartValue" SG_ 2565865739 ASRBrakeControlActive_ISig_3 3;
BA_ "Platform_VMCU1_Sig" SG_ 2565865739 ASRBrakeControlActive_ISig_3 1;
BA_ "SPN" SG_ 2565865739 ASRBrakeControlActive_ISig_3 562;
BA_ "SeToolAncestorID_SIGNAL" SG_ 2565865739 ASRBrakeControlActive_ISig_3 "x0000001D04125C74";
BA_ "SeToolItemID_SIGNAL" SG_ 2565865739 ASRBrakeControlActive_ISig_3 "x0000001D04125C74";
BA_ "SeToolName_SIGNAL" SG_ 2565865739 ASRBrakeControlActive_ISig_3 "ASRBrakeControlActive";
BA_ "SeToolVersion_SIGNAL" SG_ 2565865739 ASRBrakeControlActive_ISig_3 "1";
BA_ "GenSigCycleTime" SG_ 2565865739 ABSEBSAmberWarningSignal_ISig_3 100;
BA_ "GenSigCycleTimeActive" SG_ 2565865739 ABSEBSAmberWarningSignal_ISig_3 100;
BA_ "GenSigStartValue" SG_ 2565865739 ABSEBSAmberWarningSignal_ISig_3 3;
BA_ "Platform_VMCU1_Sig" SG_ 2565865739 ABSEBSAmberWarningSignal_ISig_3 1;
BA_ "SPN" SG_ 2565865739 ABSEBSAmberWarningSignal_ISig_3 1438;
BA_ "GenSigCycleTime" SG_ 2565865739 AntiLockBrakingActive_ISig_3 100;
BA_ "GenSigCycleTimeActive" SG_ 2565865739 AntiLockBrakingActive_ISig_3 100;
BA_ "GenSigStartValue" SG_ 2565865739 AntiLockBrakingActive_ISig_3 3;
BA_ "Platform_VMCU1_Sig" SG_ 2565865739 AntiLockBrakingActive_ISig_3 1;
BA_ "SPN" SG_ 2565865739 AntiLockBrakingActive_ISig_3 563;
BA_ "SeToolAncestorID_SIGNAL" SG_ 2565865739 AntiLockBrakingActive_ISig_3 "x0000001D0410DB7B";
BA_ "SeToolItemID_SIGNAL" SG_ 2565865739 AntiLockBrakingActive_ISig_3 "x0000001D0410DB7B";
BA_ "SeToolName_SIGNAL" SG_ 2565865739 AntiLockBrakingActive_ISig_3 "Anti-LockBraking(ABS)Active";
BA_ "SeToolVersion_SIGNAL" SG_ 2565865739 AntiLockBrakingActive_ISig_3 "1";
BA_ "GenSigSendType" SG_ 2671964910 DiagUUDTRespSig_F2_EE_ISig_3 7;
BA_ "Platform_VMCU1_Sig" SG_ 2671964910 DiagUUDTRespSig_F2_EE_ISig_3 1;
BA_ "GenSigSendType" SG_ 2671964712 DiagUUDTRespSig_F2_28_ISig_3 7;
BA_ "Platform_VMCU1_Sig" SG_ 2671964712 DiagUUDTRespSig_F2_28_ISig_3 1;
BA_ "GenSigSendType" SG_ 2671964689 DiagUUDTRespSig_F2_11_ISig_3 7;
BA_ "Platform_VMCU1_Sig" SG_ 2671964689 DiagUUDTRespSig_F2_11_ISig_3 1;
BA_ "GenSigSendType" SG_ 2671834350 InternalTesterDiagSig_F4_EE_ISig 7;
BA_ "Platform_VMCU1_Sig" SG_ 2671834350 InternalTesterDiagSig_F4_EE_ISig 1;
BA_ "SystemSignalLongSymbol" SG_ 2671834350 InternalTesterDiagSig_F4_EE_ISig "InternalTesterDiagSig_F4_EE_ISig_3";
BA_ "GenSigSendType" SG_ 2671834152 InternalTesterDiagSig_F4_28_ISig 7;
BA_ "Platform_VMCU1_Sig" SG_ 2671834152 InternalTesterDiagSig_F4_28_ISig 1;
BA_ "SystemSignalLongSymbol" SG_ 2671834152 InternalTesterDiagSig_F4_28_ISig "InternalTesterDiagSig_F4_28_ISig_3";
BA_ "GenSigSendType" SG_ 2671834129 InternalTesterDiagSig_F4_11_ISig 7;
BA_ "Platform_VMCU1_Sig" SG_ 2671834129 InternalTesterDiagSig_F4_11_ISig 1;
BA_ "SystemSignalLongSymbol" SG_ 2671834129 InternalTesterDiagSig_F4_11_ISig "InternalTesterDiagSig_F4_11_ISig_3";
BA_ "GenSigSendType" SG_ 2671834094 InternalTesterDiagSig_F3_EE 7;
BA_ "Platform_VMCU1_Sig" SG_ 2671834094 InternalTesterDiagSig_F3_EE 1;
BA_ "GenSigSendType" SG_ 2671833896 InternalTesterDiagSig_F3_28 7;
BA_ "Platform_VMCU1_Sig" SG_ 2671833896 InternalTesterDiagSig_F3_28 1;
BA_ "GenSigSendType" SG_ 2671833873 InternalTesterDiagSig_F3_11 7;
BA_ "Platform_VMCU1_Sig" SG_ 2671833873 InternalTesterDiagSig_F3_11 1;
BA_ "GenSigSendType" SG_ 2671832820 InternalTesterDiagSig_EE_F4_ISig 7;
BA_ "Platform_VMCU1_Sig" SG_ 2671832820 InternalTesterDiagSig_EE_F4_ISig 1;
BA_ "SystemSignalLongSymbol" SG_ 2671832820 InternalTesterDiagSig_EE_F4_ISig "InternalTesterDiagSig_EE_F4_ISig_3";
BA_ "GenSigSendType" SG_ 2671782132 InternalTesterDiagSig_28_F4_ISig 7;
BA_ "Platform_VMCU1_Sig" SG_ 2671782132 InternalTesterDiagSig_28_F4_ISig 1;
BA_ "SystemSignalLongSymbol" SG_ 2671782132 InternalTesterDiagSig_28_F4_ISig "InternalTesterDiagSig_28_F4_ISig_3";
BA_ "GenSigSendType" SG_ 2671776244 InternalTesterDiagSig_11_F4_ISig 7;
BA_ "Platform_VMCU1_Sig" SG_ 2671776244 InternalTesterDiagSig_11_F4_ISig 1;
BA_ "SystemSignalLongSymbol" SG_ 2671776244 InternalTesterDiagSig_11_F4_ISig "InternalTesterDiagSig_11_F4_ISig_3";
BA_ "GenSigSendType" SG_ 2671832819 InternalTesterDiagSig_EE_F3 7;
BA_ "Platform_VMCU1_Sig" SG_ 2671832819 InternalTesterDiagSig_EE_F3 1;
BA_ "GenSigSendType" SG_ 2671782131 InternalTesterDiagSig_28_F3 7;
BA_ "Platform_VMCU1_Sig" SG_ 2671782131 InternalTesterDiagSig_28_F3 1;
BA_ "GenSigSendType" SG_ 2671776243 InternalTesterDiagSig_11_F3 7;
BA_ "Platform_VMCU1_Sig" SG_ 2671776243 InternalTesterDiagSig_11_F3 1;
BA_ "GenSigSendType" SG_ 2566907915 DiagFaultStat_Brake_FailTA_ISig_ 3;
BA_ "NeedsUpdateBit" SG_ 2566907915 DiagFaultStat_Brake_FailTA_ISig_ 1;
BA_ "Platform_VMCU1_Sig" SG_ 2566907915 DiagFaultStat_Brake_FailTA_ISig_ 1;
BA_ "SystemSignalLongSymbol" SG_ 2566907915 DiagFaultStat_Brake_FailTA_ISig_ "DiagFaultStat_Brake_FailTA_ISig_3";
BA_ "GenSigSendType" SG_ 2566907915 DiagFaultStat_Brake_sg_UB_ISig_3 7;
BA_ "Platform_VMCU1_Sig" SG_ 2566907915 DiagFaultStat_Brake_sg_UB_ISig_3 1;
BA_ "GenSigSendType" SG_ 2566907915 DiagFaultStat_Brake_FailTB_ISig_ 3;
BA_ "NeedsUpdateBit" SG_ 2566907915 DiagFaultStat_Brake_FailTB_ISig_ 1;
BA_ "Platform_VMCU1_Sig" SG_ 2566907915 DiagFaultStat_Brake_FailTB_ISig_ 1;
BA_ "SystemSignalLongSymbol" SG_ 2566907915 DiagFaultStat_Brake_FailTB_ISig_ "DiagFaultStat_Brake_FailTB_ISig_3";
BA_ "GenSigSendType" SG_ 2566907915 DiagFaultStat_Brake_DtcIdA_ISig_ 3;
BA_ "NeedsUpdateBit" SG_ 2566907915 DiagFaultStat_Brake_DtcIdA_ISig_ 1;
BA_ "Platform_VMCU1_Sig" SG_ 2566907915 DiagFaultStat_Brake_DtcIdA_ISig_ 1;
BA_ "SystemSignalLongSymbol" SG_ 2566907915 DiagFaultStat_Brake_DtcIdA_ISig_ "DiagFaultStat_Brake_DtcIdA_ISig_3";
BA_ "GenSigSendType" SG_ 2566907915 DiagFaultStat_Brake_EcuAdr_ISig_ 3;
BA_ "GenSigStartValue" SG_ 2566907915 DiagFaultStat_Brake_EcuAdr_ISig_ 255;
BA_ "NeedsUpdateBit" SG_ 2566907915 DiagFaultStat_Brake_EcuAdr_ISig_ 1;
BA_ "Platform_VMCU1_Sig" SG_ 2566907915 DiagFaultStat_Brake_EcuAdr_ISig_ 1;
BA_ "SystemSignalLongSymbol" SG_ 2566907915 DiagFaultStat_Brake_EcuAdr_ISig_ "DiagFaultStat_Brake_EcuAdr_ISig_3";
BA_ "GenSigSendType" SG_ 2566907915 DiagFaultStat_Brake_DtcIdB_ISig_ 3;
BA_ "NeedsUpdateBit" SG_ 2566907915 DiagFaultStat_Brake_DtcIdB_ISig_ 1;
BA_ "Platform_VMCU1_Sig" SG_ 2566907915 DiagFaultStat_Brake_DtcIdB_ISig_ 1;
BA_ "SystemSignalLongSymbol" SG_ 2566907915 DiagFaultStat_Brake_DtcIdB_ISig_ "DiagFaultStat_Brake_DtcIdB_ISig_3";
BA_ "GenSigSendType" SG_ 2566907965 DiagFaultStat_ACM_sg_UB_ISig_3 7;
BA_ "Platform_VMCU1_Sig" SG_ 2566907965 DiagFaultStat_ACM_sg_UB_ISig_3 1;
BA_ "GenSigSendType" SG_ 2566907965 DiagFaultStat_ACM_DtcIdB_ISig_3 3;
BA_ "GenSigMaxLatency" SG_ 2566907965 DiagFaultStat_ACM_DtcIdB_ISig_3 100;
BA_ "NeedsUpdateBit" SG_ 2566907965 DiagFaultStat_ACM_DtcIdB_ISig_3 1;
BA_ "Platform_VMCU1_Sig" SG_ 2566907965 DiagFaultStat_ACM_DtcIdB_ISig_3 1;
BA_ "GenSigSendType" SG_ 2566907965 DiagFaultStat_ACM_FailTA_ISig_3 3;
BA_ "GenSigMaxLatency" SG_ 2566907965 DiagFaultStat_ACM_FailTA_ISig_3 100;
BA_ "NeedsUpdateBit" SG_ 2566907965 DiagFaultStat_ACM_FailTA_ISig_3 1;
BA_ "Platform_VMCU1_Sig" SG_ 2566907965 DiagFaultStat_ACM_FailTA_ISig_3 1;
BA_ "GenSigSendType" SG_ 2566907965 DiagFaultStat_ACM_FailTB_ISig_3 3;
BA_ "GenSigMaxLatency" SG_ 2566907965 DiagFaultStat_ACM_FailTB_ISig_3 100;
BA_ "NeedsUpdateBit" SG_ 2566907965 DiagFaultStat_ACM_FailTB_ISig_3 1;
BA_ "Platform_VMCU1_Sig" SG_ 2566907965 DiagFaultStat_ACM_FailTB_ISig_3 1;
BA_ "GenSigSendType" SG_ 2566907965 DiagFaultStat_ACM_EcuAdr_ISig_3 3;
BA_ "GenSigStartValue" SG_ 2566907965 DiagFaultStat_ACM_EcuAdr_ISig_3 255;
BA_ "GenSigMaxLatency" SG_ 2566907965 DiagFaultStat_ACM_EcuAdr_ISig_3 100;
BA_ "NeedsUpdateBit" SG_ 2566907965 DiagFaultStat_ACM_EcuAdr_ISig_3 1;
BA_ "Platform_VMCU1_Sig" SG_ 2566907965 DiagFaultStat_ACM_EcuAdr_ISig_3 1;
BA_ "GenSigSendType" SG_ 2566907965 DiagFaultStat_ACM_DtcIdA_ISig_3 3;
BA_ "GenSigMaxLatency" SG_ 2566907965 DiagFaultStat_ACM_DtcIdA_ISig_3 100;
BA_ "NeedsUpdateBit" SG_ 2566907965 DiagFaultStat_ACM_DtcIdA_ISig_3 1;
BA_ "Platform_VMCU1_Sig" SG_ 2566907965 DiagFaultStat_ACM_DtcIdA_ISig_3 1;
BA_ "GenSigSendType" SG_ 2634020590 Debug_6_TACHO 1;
BA_ "Platform_VMCU1_Sig" SG_ 2634020590 Debug_6_TACHO 1;
BA_ "GenSigSendType" SG_ 2634020363 Debug_6_EBS_ABS 1;
BA_ "GenSigMaxLatency" SG_ 2634020363 Debug_6_EBS_ABS 55;
BA_ "Platform_VMCU1_Sig" SG_ 2634020363 Debug_6_EBS_ABS 1;
BA_ "GenSigSendType" SG_ 2634020413 Debug_6_ACM 1;
BA_ "GenSigMaxLatency" SG_ 2634020413 Debug_6_ACM 55;
BA_ "Platform_VMCU1_Sig" SG_ 2634020413 Debug_6_ACM 1;
BA_ "GenSigSendType" SG_ 2634020334 Debug_5_TACHO 1;
BA_ "Platform_VMCU1_Sig" SG_ 2634020334 Debug_5_TACHO 1;
BA_ "GenSigSendType" SG_ 2634020107 Debug_5_EBS_ABS 1;
BA_ "GenSigMaxLatency" SG_ 2634020107 Debug_5_EBS_ABS 55;
BA_ "Platform_VMCU1_Sig" SG_ 2634020107 Debug_5_EBS_ABS 1;
BA_ "GenSigSendType" SG_ 2634020157 Debug_5_ACM 1;
BA_ "GenSigMaxLatency" SG_ 2634020157 Debug_5_ACM 55;
BA_ "Platform_VMCU1_Sig" SG_ 2634020157 Debug_5_ACM 1;
BA_ "GenSigSendType" SG_ 2634020078 Debug_4_TACHO 1;
BA_ "Platform_VMCU1_Sig" SG_ 2634020078 Debug_4_TACHO 1;
BA_ "GenSigSendType" SG_ 2634019851 Debug_4_EBS_ABS 1;
BA_ "GenSigMaxLatency" SG_ 2634019851 Debug_4_EBS_ABS 55;
BA_ "Platform_VMCU1_Sig" SG_ 2634019851 Debug_4_EBS_ABS 1;
BA_ "GenSigSendType" SG_ 2634019901 Debug_4_ACM 1;
BA_ "GenSigMaxLatency" SG_ 2634019901 Debug_4_ACM 55;
BA_ "Platform_VMCU1_Sig" SG_ 2634019901 Debug_4_ACM 1;
BA_ "GenSigSendType" SG_ 2634019822 Debug_3_TACHO 1;
BA_ "Platform_VMCU1_Sig" SG_ 2634019822 Debug_3_TACHO 1;
BA_ "GenSigSendType" SG_ 2634019595 Debug_3_EBS_ABS 1;
BA_ "GenSigMaxLatency" SG_ 2634019595 Debug_3_EBS_ABS 55;
BA_ "Platform_VMCU1_Sig" SG_ 2634019595 Debug_3_EBS_ABS 1;
BA_ "GenSigSendType" SG_ 2634019645 Debug_3_ACM 1;
BA_ "GenSigMaxLatency" SG_ 2634019645 Debug_3_ACM 55;
BA_ "Platform_VMCU1_Sig" SG_ 2634019645 Debug_3_ACM 1;
BA_ "GenSigSendType" SG_ 2634019566 Debug_2_TACHO 1;
BA_ "Platform_VMCU1_Sig" SG_ 2634019566 Debug_2_TACHO 1;
BA_ "GenSigSendType" SG_ 2634019339 Debug_2_EBS_ABS 1;
BA_ "GenSigMaxLatency" SG_ 2634019339 Debug_2_EBS_ABS 55;
BA_ "Platform_VMCU1_Sig" SG_ 2634019339 Debug_2_EBS_ABS 1;
BA_ "GenSigSendType" SG_ 2634019389 Debug_2_ACM 1;
BA_ "GenSigMaxLatency" SG_ 2634019389 Debug_2_ACM 55;
BA_ "Platform_VMCU1_Sig" SG_ 2634019389 Debug_2_ACM 1;
BA_ "GenSigSendType" SG_ 2634019310 Debug_1_TACHO 1;
BA_ "Platform_VMCU1_Sig" SG_ 2634019310 Debug_1_TACHO 1;
BA_ "GenSigSendType" SG_ 2634019083 Debug_1_EBS_ABS 1;
BA_ "Platform_VMCU1_Sig" SG_ 2634019083 Debug_1_EBS_ABS 1;
BA_ "GenSigSendType" SG_ 2634019133 Debug_1_ACM 1;
BA_ "Platform_VMCU1_Sig" SG_ 2634019133 Debug_1_ACM 1;
BA_ "GenSigSendType" SG_ 2566749184 DPFC1_ActiveRegeneratStatus_ISig 3;
BA_ "GenSigCycleTime" SG_ 2566749184 DPFC1_ActiveRegeneratStatus_ISig 100;
BA_ "GenSigCycleTimeActive" SG_ 2566749184 DPFC1_ActiveRegeneratStatus_ISig 100;
BA_ "GenSigStartValue" SG_ 2566749184 DPFC1_ActiveRegeneratStatus_ISig 3;
BA_ "Platform_VMCU1_Sig" SG_ 2566749184 DPFC1_ActiveRegeneratStatus_ISig 1;
BA_ "SPN" SG_ 2566749184 DPFC1_ActiveRegeneratStatus_ISig 3700;
BA_ "SystemSignalLongSymbol" SG_ 2566749184 DPFC1_ActiveRegeneratStatus_ISig "DPFC1_ActiveRegeneratStatus_ISig_3";
BA_ "GenSigCycleTime" SG_ 2566749184 DPFC1_LampCommand_ISig_3 100;
BA_ "GenSigCycleTimeActive" SG_ 2566749184 DPFC1_LampCommand_ISig_3 100;
BA_ "GenSigStartValue" SG_ 2566749184 DPFC1_LampCommand_ISig_3 7;
BA_ "Platform_VMCU1_Sig" SG_ 2566749184 DPFC1_LampCommand_ISig_3 1;
BA_ "SPN" SG_ 2566749184 DPFC1_LampCommand_ISig_3 3697;
BA_ "GenSigCycleTime" SG_ 2566749184 DPFC1_InhibTempSystemLock_ISig_3 100;
BA_ "GenSigCycleTimeActive" SG_ 2566749184 DPFC1_InhibTempSystemLock_ISig_3 100;
BA_ "GenSigStartValue" SG_ 2566749184 DPFC1_InhibTempSystemLock_ISig_3 3;
BA_ "Platform_VMCU1_Sig" SG_ 2566749184 DPFC1_InhibTempSystemLock_ISig_3 1;
BA_ "SPN" SG_ 2566749184 DPFC1_InhibTempSystemLock_ISig_3 3714;
BA_ "GenSigCycleTime" SG_ 2566749184 DPFC1_InhibOutOfNeutral_ISig_3 100;
BA_ "GenSigCycleTimeActive" SG_ 2566749184 DPFC1_InhibOutOfNeutral_ISig_3 100;
BA_ "GenSigStartValue" SG_ 2566749184 DPFC1_InhibOutOfNeutral_ISig_3 3;
BA_ "Platform_VMCU1_Sig" SG_ 2566749184 DPFC1_InhibOutOfNeutral_ISig_3 1;
BA_ "SPN" SG_ 2566749184 DPFC1_InhibOutOfNeutral_ISig_3 3708;
BA_ "GenSigCycleTime" SG_ 2566749184 DPFC1_InhibEnginNotWarmUp_ISig_3 100;
BA_ "GenSigCycleTimeActive" SG_ 2566749184 DPFC1_InhibEnginNotWarmUp_ISig_3 100;
BA_ "GenSigStartValue" SG_ 2566749184 DPFC1_InhibEnginNotWarmUp_ISig_3 3;
BA_ "Platform_VMCU1_Sig" SG_ 2566749184 DPFC1_InhibEnginNotWarmUp_ISig_3 1;
BA_ "SPN" SG_ 2566749184 DPFC1_InhibEnginNotWarmUp_ISig_3 3716;
BA_ "GenSigCycleTime" SG_ 2566749184 DPFC1_InhibDueInhibSwitch_ISig_3 100;
BA_ "GenSigCycleTimeActive" SG_ 2566749184 DPFC1_InhibDueInhibSwitch_ISig_3 100;
BA_ "GenSigStartValue" SG_ 2566749184 DPFC1_InhibDueInhibSwitch_ISig_3 3;
BA_ "Platform_VMCU1_Sig" SG_ 2566749184 DPFC1_InhibDueInhibSwitch_ISig_3 1;
BA_ "SPN" SG_ 2566749184 DPFC1_InhibDueInhibSwitch_ISig_3 3703;
BA_ "GenSigCycleTime" SG_ 2566749184 DPFC1_InhibClutchDisengage_ISig_ 100;
BA_ "GenSigCycleTimeActive" SG_ 2566749184 DPFC1_InhibClutchDisengage_ISig_ 100;
BA_ "GenSigStartValue" SG_ 2566749184 DPFC1_InhibClutchDisengage_ISig_ 3;
BA_ "Platform_VMCU1_Sig" SG_ 2566749184 DPFC1_InhibClutchDisengage_ISig_ 1;
BA_ "SPN" SG_ 2566749184 DPFC1_InhibClutchDisengage_ISig_ 3704;
BA_ "SystemSignalLongSymbol" SG_ 2566749184 DPFC1_InhibClutchDisengage_ISig_ "DPFC1_InhibClutchDisengage_ISig_3";
BA_ "GenSigCycleTime" SG_ 2566749184 DPFC1_InhibVehSpdAboveAllwdSpd_I 100;
BA_ "GenSigCycleTimeActive" SG_ 2566749184 DPFC1_InhibVehSpdAboveAllwdSpd_I 100;
BA_ "GenSigStartValue" SG_ 2566749184 DPFC1_InhibVehSpdAboveAllwdSpd_I 3;
BA_ "Platform_VMCU1_Sig" SG_ 2566749184 DPFC1_InhibVehSpdAboveAllwdSpd_I 1;
BA_ "SPN" SG_ 2566749184 DPFC1_InhibVehSpdAboveAllwdSpd_I 3709;
BA_ "SystemSignalLongSymbol" SG_ 2566749184 DPFC1_InhibVehSpdAboveAllwdSpd_I "DPFC1_InhibVehSpdAboveAllwdSpd_ISig_3";
BA_ "GenSigCycleTime" SG_ 2566749184 DPFC1_ForcedStatus_ISig_3 100;
BA_ "GenSigCycleTimeActive" SG_ 2566749184 DPFC1_ForcedStatus_ISig_3 100;
BA_ "GenSigStartValue" SG_ 2566749184 DPFC1_ForcedStatus_ISig_3 7;
BA_ "Platform_VMCU1_Sig" SG_ 2566749184 DPFC1_ForcedStatus_ISig_3 1;
BA_ "SPN" SG_ 2566749184 DPFC1_ForcedStatus_ISig_3 4175;
BA_ "GenSigCycleTime" SG_ 2566749184 DPFC1_InhibPTOActive_ISig_3 100;
BA_ "GenSigCycleTimeActive" SG_ 2566749184 DPFC1_InhibPTOActive_ISig_3 100;
BA_ "GenSigStartValue" SG_ 2566749184 DPFC1_InhibPTOActive_ISig_3 3;
BA_ "Platform_VMCU1_Sig" SG_ 2566749184 DPFC1_InhibPTOActive_ISig_3 1;
BA_ "SPN" SG_ 2566749184 DPFC1_InhibPTOActive_ISig_3 3706;
BA_ "GenSigCycleTime" SG_ 2566749184 DPFC1_InhibVehSpdBelowAllwdSpd_I 100;
BA_ "GenSigCycleTimeActive" SG_ 2566749184 DPFC1_InhibVehSpdBelowAllwdSpd_I 100;
BA_ "GenSigStartValue" SG_ 2566749184 DPFC1_InhibVehSpdBelowAllwdSpd_I 3;
BA_ "Platform_VMCU1_Sig" SG_ 2566749184 DPFC1_InhibVehSpdBelowAllwdSpd_I 1;
BA_ "SPN" SG_ 2566749184 DPFC1_InhibVehSpdBelowAllwdSpd_I 3717;
BA_ "SystemSignalLongSymbol" SG_ 2566749184 DPFC1_InhibVehSpdBelowAllwdSpd_I "DPFC1_InhibVehSpdBelowAllwdSpd_ISig_3";
BA_ "GenSigCycleTime" SG_ 2566749184 DPFC1_InhibSystemFaultAct_ISig_3 100;
BA_ "GenSigCycleTimeActive" SG_ 2566749184 DPFC1_InhibSystemFaultAct_ISig_3 100;
BA_ "GenSigStartValue" SG_ 2566749184 DPFC1_InhibSystemFaultAct_ISig_3 3;
BA_ "Platform_VMCU1_Sig" SG_ 2566749184 DPFC1_InhibSystemFaultAct_ISig_3 1;
BA_ "SPN" SG_ 2566749184 DPFC1_InhibSystemFaultAct_ISig_3 3712;
BA_ "GenSigCycleTime" SG_ 2566749184 DPFC1_PassiveRegenStatus_ISig_3 100;
BA_ "GenSigCycleTimeActive" SG_ 2566749184 DPFC1_PassiveRegenStatus_ISig_3 100;
BA_ "GenSigStartValue" SG_ 2566749184 DPFC1_PassiveRegenStatus_ISig_3 3;
BA_ "Platform_VMCU1_Sig" SG_ 2566749184 DPFC1_PassiveRegenStatus_ISig_3 1;
BA_ "SPN" SG_ 2566749184 DPFC1_PassiveRegenStatus_ISig_3 3699;
BA_ "GenSigCycleTime" SG_ 2566749184 DPFC1_InhibPermSystemLock_ISig_3 100;
BA_ "GenSigCycleTimeActive" SG_ 2566749184 DPFC1_InhibPermSystemLock_ISig_3 100;
BA_ "GenSigStartValue" SG_ 2566749184 DPFC1_InhibPermSystemLock_ISig_3 3;
BA_ "Platform_VMCU1_Sig" SG_ 2566749184 DPFC1_InhibPermSystemLock_ISig_3 1;
BA_ "SPN" SG_ 2566749184 DPFC1_InhibPermSystemLock_ISig_3 3715;
BA_ "GenSigCycleTime" SG_ 2566749184 DPFC1_AutoARInitConfig_ISig_3 100;
BA_ "GenSigCycleTimeActive" SG_ 2566749184 DPFC1_AutoARInitConfig_ISig_3 100;
BA_ "GenSigStartValue" SG_ 2566749184 DPFC1_AutoARInitConfig_ISig_3 3;
BA_ "Platform_VMCU1_Sig" SG_ 2566749184 DPFC1_AutoARInitConfig_ISig_3 1;
BA_ "SPN" SG_ 2566749184 DPFC1_AutoARInitConfig_ISig_3 3718;
BA_ "GenSigCycleTime" SG_ 2566749184 DPFC1_InhibDueLowExhGasTemp_ISig 100;
BA_ "GenSigCycleTimeActive" SG_ 2566749184 DPFC1_InhibDueLowExhGasTemp_ISig 100;
BA_ "GenSigStartValue" SG_ 2566749184 DPFC1_InhibDueLowExhGasTemp_ISig 3;
BA_ "Platform_VMCU1_Sig" SG_ 2566749184 DPFC1_InhibDueLowExhGasTemp_ISig 1;
BA_ "SPN" SG_ 2566749184 DPFC1_InhibDueLowExhGasTemp_ISig 3711;
BA_ "SystemSignalLongSymbol" SG_ 2566749184 DPFC1_InhibDueLowExhGasTemp_ISig "DPFC1_InhibDueLowExhGasTemp_ISig_3";
BA_ "GenSigCycleTime" SG_ 2566749184 DPFC1_ExhaustSystHighTempLampCmd 100;
BA_ "GenSigCycleTimeActive" SG_ 2566749184 DPFC1_ExhaustSystHighTempLampCmd 100;
BA_ "GenSigStartValue" SG_ 2566749184 DPFC1_ExhaustSystHighTempLampCmd 7;
BA_ "Platform_VMCU1_Sig" SG_ 2566749184 DPFC1_ExhaustSystHighTempLampCmd 1;
BA_ "SPN" SG_ 2566749184 DPFC1_ExhaustSystHighTempLampCmd 3698;
BA_ "SystemSignalLongSymbol" SG_ 2566749184 DPFC1_ExhaustSystHighTempLampCmd "DPFC1_ExhaustSystHighTempLampCmd_ISig_3";
BA_ "GenSigSendType" SG_ 2566749184 DPFC1_InhibitStatus_ISig_3 3;
BA_ "GenSigCycleTime" SG_ 2566749184 DPFC1_InhibitStatus_ISig_3 100;
BA_ "GenSigCycleTimeActive" SG_ 2566749184 DPFC1_InhibitStatus_ISig_3 100;
BA_ "GenSigStartValue" SG_ 2566749184 DPFC1_InhibitStatus_ISig_3 3;
BA_ "Platform_VMCU1_Sig" SG_ 2566749184 DPFC1_InhibitStatus_ISig_3 1;
BA_ "SPN" SG_ 2566749184 DPFC1_InhibitStatus_ISig_3 3702;
BA_ "GenSigCycleTime" SG_ 2566749184 DPFC1_DPFStatus_ISig_3 100;
BA_ "GenSigCycleTimeActive" SG_ 2566749184 DPFC1_DPFStatus_ISig_3 100;
BA_ "GenSigStartValue" SG_ 2566749184 DPFC1_DPFStatus_ISig_3 7;
BA_ "Platform_VMCU1_Sig" SG_ 2566749184 DPFC1_DPFStatus_ISig_3 1;
BA_ "SPN" SG_ 2566749184 DPFC1_DPFStatus_ISig_3 3701;
BA_ "GenSigCycleTime" SG_ 2566749184 DPFC1_InhibParkBrakeNotSet_ISig_ 100;
BA_ "GenSigCycleTimeActive" SG_ 2566749184 DPFC1_InhibParkBrakeNotSet_ISig_ 100;
BA_ "GenSigStartValue" SG_ 2566749184 DPFC1_InhibParkBrakeNotSet_ISig_ 3;
BA_ "Platform_VMCU1_Sig" SG_ 2566749184 DPFC1_InhibParkBrakeNotSet_ISig_ 1;
BA_ "SPN" SG_ 2566749184 DPFC1_InhibParkBrakeNotSet_ISig_ 3710;
BA_ "SystemSignalLongSymbol" SG_ 2566749184 DPFC1_InhibParkBrakeNotSet_ISig_ "DPFC1_InhibParkBrakeNotSet_ISig_3";
BA_ "GenSigCycleTime" SG_ 2566749184 DPFC1_InhibDueServiceBrake_ISig_ 100;
BA_ "GenSigCycleTimeActive" SG_ 2566749184 DPFC1_InhibDueServiceBrake_ISig_ 100;
BA_ "GenSigStartValue" SG_ 2566749184 DPFC1_InhibDueServiceBrake_ISig_ 3;
BA_ "Platform_VMCU1_Sig" SG_ 2566749184 DPFC1_InhibDueServiceBrake_ISig_ 1;
BA_ "SPN" SG_ 2566749184 DPFC1_InhibDueServiceBrake_ISig_ 3705;
BA_ "SystemSignalLongSymbol" SG_ 2566749184 DPFC1_InhibDueServiceBrake_ISig_ "DPFC1_InhibDueServiceBrake_ISig_3";
BA_ "GenSigCycleTime" SG_ 2566749184 DPFC1_InhibDueSystemTimeout_ISig 100;
BA_ "GenSigCycleTimeActive" SG_ 2566749184 DPFC1_InhibDueSystemTimeout_ISig 100;
BA_ "GenSigStartValue" SG_ 2566749184 DPFC1_InhibDueSystemTimeout_ISig 3;
BA_ "Platform_VMCU1_Sig" SG_ 2566749184 DPFC1_InhibDueSystemTimeout_ISig 1;
BA_ "SPN" SG_ 2566749184 DPFC1_InhibDueSystemTimeout_ISig 3713;
BA_ "SystemSignalLongSymbol" SG_ 2566749184 DPFC1_InhibDueSystemTimeout_ISig "DPFC1_InhibDueSystemTimeout_ISig_3";
BA_ "GenSigCycleTime" SG_ 2566749184 DPFC1_InhibAccPedalOffIdle_ISig_ 100;
BA_ "GenSigCycleTimeActive" SG_ 2566749184 DPFC1_InhibAccPedalOffIdle_ISig_ 100;
BA_ "GenSigStartValue" SG_ 2566749184 DPFC1_InhibAccPedalOffIdle_ISig_ 3;
BA_ "Platform_VMCU1_Sig" SG_ 2566749184 DPFC1_InhibAccPedalOffIdle_ISig_ 1;
BA_ "SPN" SG_ 2566749184 DPFC1_InhibAccPedalOffIdle_ISig_ 3707;
BA_ "SystemSignalLongSymbol" SG_ 2566749184 DPFC1_InhibAccPedalOffIdle_ISig_ "DPFC1_InhibAccPedalOffIdle_ISig_3";
BA_ "GenSigCycleTime" SG_ 2566834691 DiagnosticsFaultStat_DM1_TECU 100;
BA_ "GenSigCycleTimeActive" SG_ 2566834691 DiagnosticsFaultStat_DM1_TECU 100;
BA_ "Platform_VMCU1_Sig" SG_ 2566834691 DiagnosticsFaultStat_DM1_TECU 1;
BA_ "SeToolAncestorID_SIGNAL" SG_ 2566834691 DiagnosticsFaultStat_DM1_TECU "x0000001D042948CC";
BA_ "SeToolItemID_SIGNAL" SG_ 2566834691 DiagnosticsFaultStat_DM1_TECU "x0000001D042948CC";
BA_ "SeToolName_SIGNAL" SG_ 2566834691 DiagnosticsFaultStat_DM1_TECU "DiagnosticsFaultStatus_DM1_TECU";
BA_ "SeToolVersion_SIGNAL" SG_ 2566834691 DiagnosticsFaultStat_DM1_TECU "1";
BA_ "GenSigCycleTime" SG_ 2566834926 DiagnosticsFaultStat_DM1_TACHO 100;
BA_ "GenSigCycleTimeActive" SG_ 2566834926 DiagnosticsFaultStat_DM1_TACHO 100;
BA_ "Platform_VMCU1_Sig" SG_ 2566834926 DiagnosticsFaultStat_DM1_TACHO 1;
BA_ "SeToolAncestorID_SIGNAL" SG_ 2566834926 DiagnosticsFaultStat_DM1_TACHO "x0000001D042948CC";
BA_ "SeToolItemID_SIGNAL" SG_ 2566834926 DiagnosticsFaultStat_DM1_TACHO "x0000001D042948CC";
BA_ "SeToolName_SIGNAL" SG_ 2566834926 DiagnosticsFaultStat_DM1_TACHO "DiagnosticsFaultStatus_DM1_TACHO";
BA_ "SeToolVersion_SIGNAL" SG_ 2566834926 DiagnosticsFaultStat_DM1_TACHO "1";
BA_ "GenSigCycleTime" SG_ 2566834688 DiagnosticsFaultStat_DM1_EMS 100;
BA_ "GenSigCycleTimeActive" SG_ 2566834688 DiagnosticsFaultStat_DM1_EMS 100;
BA_ "Platform_VMCU1_Sig" SG_ 2566834688 DiagnosticsFaultStat_DM1_EMS 1;
BA_ "SeToolAncestorID_SIGNAL" SG_ 2566834688 DiagnosticsFaultStat_DM1_EMS "x0000001D042948CC";
BA_ "SeToolItemID_SIGNAL" SG_ 2566834688 DiagnosticsFaultStat_DM1_EMS "x0000001D042948CC";
BA_ "SeToolName_SIGNAL" SG_ 2566834688 DiagnosticsFaultStat_DM1_EMS "DiagnosticsFaultStatus_DM1_EMS";
BA_ "SeToolVersion_SIGNAL" SG_ 2566834688 DiagnosticsFaultStat_DM1_EMS "1";
BA_ "GenSigCycleTime" SG_ 2566834749 DiagnosticsFaultStat_DM1_ACM 100;
BA_ "GenSigCycleTimeActive" SG_ 2566834749 DiagnosticsFaultStat_DM1_ACM 100;
BA_ "Platform_VMCU1_Sig" SG_ 2566834749 DiagnosticsFaultStat_DM1_ACM 1;
BA_ "GenSigSendType" SG_ 2566810606 DriversIdentifications 1;
BA_ "Platform_VMCU1_Sig" SG_ 2566810606 DriversIdentifications 1;
BA_ "GenSigCycleTime" SG_ 2566723046 DriverDoorOpen_stat_ISig_3 100;
BA_ "GenSigCycleTimeActive" SG_ 2566723046 DriverDoorOpen_stat_ISig_3 100;
BA_ "GenSigStartValue" SG_ 2566723046 DriverDoorOpen_stat_ISig_3 3;
BA_ "GenSigCycleTime" SG_ 2566723046 PassengerDoorOpen_stat_ISig_3 100;
BA_ "GenSigCycleTimeActive" SG_ 2566723046 PassengerDoorOpen_stat_ISig_3 100;
BA_ "GenSigStartValue" SG_ 2566723046 PassengerDoorOpen_stat_ISig_3 3;
BA_ "GenSigCycleTime" SG_ 2499790765 ACC_SGO_Status_ISig_3 100;
BA_ "GenSigCycleTimeActive" SG_ 2499790765 ACC_SGO_Status_ISig_3 100;
BA_ "GenSigStartValue" SG_ 2499790765 ACC_SGO_Status_ISig_3 15;
BA_ "Platform_VMCU1_Sig" SG_ 2499790765 ACC_SGO_Status_ISig_3 1;
BA_ "GenSigCycleTime" SG_ 2499790765 ACCHSARequest 100;
BA_ "GenSigCycleTimeActive" SG_ 2499790765 ACCHSARequest 100;
BA_ "GenSigStartValue" SG_ 2499790765 ACCHSARequest 7;
BA_ "Platform_VMCU1_Sig" SG_ 2499790765 ACCHSARequest 1;
BA_ "GenSigCycleTime" SG_ 2566811659 PoweredVehicleWeight_ISig_3 100;
BA_ "GenSigCycleTimeActive" SG_ 2566811659 PoweredVehicleWeight_ISig_3 100;
BA_ "GenSigStartValue" SG_ 2566811659 PoweredVehicleWeight_ISig_3 65535;
BA_ "Platform_VMCU1_Sig" SG_ 2566811659 PoweredVehicleWeight_ISig_3 1;
BA_ "SPN" SG_ 2566811659 PoweredVehicleWeight_ISig_3 1585;
BA_ "SeToolAncestorID_SIGNAL" SG_ 2566811659 PoweredVehicleWeight_ISig_3 "x0000001D0412FC34";
BA_ "SeToolItemID_SIGNAL" SG_ 2566811659 PoweredVehicleWeight_ISig_3 "x0000001D0412FC34";
BA_ "SeToolName_SIGNAL" SG_ 2566811659 PoweredVehicleWeight_ISig_3 "PoweredVehicleWeight";
BA_ "SeToolVersion_SIGNAL" SG_ 2566811659 PoweredVehicleWeight_ISig_3 "1";
BA_ "GenSigCycleTime" SG_ 2566811659 GrossCombinationVehicleWeight_IS 100;
BA_ "GenSigCycleTimeActive" SG_ 2566811659 GrossCombinationVehicleWeight_IS 100;
BA_ "GenSigStartValue" SG_ 2566811659 GrossCombinationVehicleWeight_IS 65535;
BA_ "Platform_VMCU1_Sig" SG_ 2566811659 GrossCombinationVehicleWeight_IS 1;
BA_ "SPN" SG_ 2566811659 GrossCombinationVehicleWeight_IS 1760;
BA_ "SeToolAncestorID_SIGNAL" SG_ 2566811659 GrossCombinationVehicleWeight_IS "x0000001D0412FC36";
BA_ "SeToolItemID_SIGNAL" SG_ 2566811659 GrossCombinationVehicleWeight_IS "x0000001D0412FC36";
BA_ "SeToolName_SIGNAL" SG_ 2566811659 GrossCombinationVehicleWeight_IS "GrossCombinationVehicleWeight";
BA_ "SeToolVersion_SIGNAL" SG_ 2566811659 GrossCombinationVehicleWeight_IS "1";
BA_ "SystemSignalLongSymbol" SG_ 2566811659 GrossCombinationVehicleWeight_IS "GrossCombinationVehicleWeight_ISig_3";
BA_ "GenSigSendType" SG_ 2563833623 BacklightLevelHighRes_ISig_3 3;
BA_ "GenSigStartValue" SG_ 2563833623 BacklightLevelHighRes_ISig_3 255;
BA_ "Platform_VMCU1_Sig" SG_ 2563833623 BacklightLevelHighRes_ISig_3 1;
BA_ "SPN" SG_ 2563833623 BacklightLevelHighRes_ISig_3 1487;
BA_ "GenSigCycleTime" SG_ 2499757105 ESCDriverReq 100;
BA_ "GenSigCycleTimeActive" SG_ 2499757105 ESCDriverReq 100;
BA_ "GenSigStartValue" SG_ 2499757105 ESCDriverReq 7;
BA_ "Platform_VMCU1_Sig" SG_ 2499757105 ESCDriverReq 1;
BA_ "GenSigCycleTime" SG_ 2499757105 RrItrWhl1DiffLockActvnDrvrReq_IS 100;
BA_ "GenSigCycleTimeActive" SG_ 2499757105 RrItrWhl1DiffLockActvnDrvrReq_IS 100;
BA_ "GenSigStartValue" SG_ 2499757105 RrItrWhl1DiffLockActvnDrvrReq_IS 3;
BA_ "NeedsUpdateBit" SG_ 2499757105 RrItrWhl1DiffLockActvnDrvrReq_IS 1;
BA_ "SystemSignalLongSymbol" SG_ 2499757105 RrItrWhl1DiffLockActvnDrvrReq_IS "RrItrWhl1DiffLockActvnDrvrReq_ISig_3";
BA_ "GenSigCycleTime" SG_ 2499757105 RearAxleSteeringFunctionDsbl_ISi 100;
BA_ "GenSigCycleTimeActive" SG_ 2499757105 RearAxleSteeringFunctionDsbl_ISi 100;
BA_ "GenSigStartValue" SG_ 2499757105 RearAxleSteeringFunctionDsbl_ISi 3;
BA_ "Platform_VMCU1_Sig" SG_ 2499757105 RearAxleSteeringFunctionDsbl_ISi 1;
BA_ "SystemSignalLongSymbol" SG_ 2499757105 RearAxleSteeringFunctionDsbl_ISi "RearAxleSteeringFunctionDsbl_ISig_3";
BA_ "GenSigCycleTime" SG_ 2499757105 RearAxleDiffLockActvnDrvrReq_ISi 100;
BA_ "GenSigCycleTimeActive" SG_ 2499757105 RearAxleDiffLockActvnDrvrReq_ISi 100;
BA_ "GenSigStartValue" SG_ 2499757105 RearAxleDiffLockActvnDrvrReq_ISi 3;
BA_ "GenSigMaxLatency" SG_ 2499757105 RearAxleDiffLockActvnDrvrReq_ISi 65;
BA_ "NeedsUpdateBit" SG_ 2499757105 RearAxleDiffLockActvnDrvrReq_ISi 1;
BA_ "Platform_VMCU1_Sig" SG_ 2499757105 RearAxleDiffLockActvnDrvrReq_ISi 1;
BA_ "SeToolAncestorID_SIGNAL" SG_ 2499757105 RearAxleDiffLockActvnDrvrReq_ISi "x0000001D041287CE";
BA_ "SeToolItemID_SIGNAL" SG_ 2499757105 RearAxleDiffLockActvnDrvrReq_ISi "x0000001D041287CE";
BA_ "SeToolName_SIGNAL" SG_ 2499757105 RearAxleDiffLockActvnDrvrReq_ISi "RearAxleDiffLockActivationDriverRequest";
BA_ "SeToolVersion_SIGNAL" SG_ 2499757105 RearAxleDiffLockActvnDrvrReq_ISi "1";
BA_ "SystemSignalLongSymbol" SG_ 2499757105 RearAxleDiffLockActvnDrvrReq_ISi "RearAxleDiffLockActvnDrvrReq_ISig_3";
BA_ "GenSigSendType" SG_ 2499757105 RearAxleDiffLockActvnDrvrReq_UB_ 7;
BA_ "Platform_VMCU1_Sig" SG_ 2499757105 RearAxleDiffLockActvnDrvrReq_UB_ 1;
BA_ "SystemSignalLongSymbol" SG_ 2499757105 RearAxleDiffLockActvnDrvrReq_UB_ "RearAxleDiffLockActvnDrvrReq_UB_ISig_3";
BA_ "GenSigCycleTime" SG_ 2499757105 RollerBenchModeRequest 100;
BA_ "GenSigCycleTimeActive" SG_ 2499757105 RollerBenchModeRequest 100;
BA_ "GenSigStartValue" SG_ 2499757105 RollerBenchModeRequest 3;
BA_ "Platform_VMCU1_Sig" SG_ 2499757105 RollerBenchModeRequest 1;
BA_ "GenSigCycleTime" SG_ 2499757105 ABSModeRequest 100;
BA_ "GenSigCycleTimeActive" SG_ 2499757105 ABSModeRequest 100;
BA_ "GenSigStartValue" SG_ 2499757105 ABSModeRequest 7;
BA_ "GenSigSendType" SG_ 2499757105 RrInterAxlDiffLockActvnDrvrReq_U 7;
BA_ "Platform_VMCU1_Sig" SG_ 2499757105 RrInterAxlDiffLockActvnDrvrReq_U 1;
BA_ "SystemSignalLongSymbol" SG_ 2499757105 RrInterAxlDiffLockActvnDrvrReq_U "RrInterAxlDiffLockActvnDrvrReq_UB_ISig_3";
BA_ "GenSigSendType" SG_ 2499757105 RrItrWhl1DiffLockActvnDrvrReq_UB 7;
BA_ "SystemSignalLongSymbol" SG_ 2499757105 RrItrWhl1DiffLockActvnDrvrReq_UB "RrItrWhl1DiffLockActvnDrvrReq_UB_ISig_3";
BA_ "GenSigCycleTime" SG_ 2499757105 RrInterAxlDiffLockActvnDrvrReq_I 100;
BA_ "GenSigCycleTimeActive" SG_ 2499757105 RrInterAxlDiffLockActvnDrvrReq_I 100;
BA_ "GenSigStartValue" SG_ 2499757105 RrInterAxlDiffLockActvnDrvrReq_I 3;
BA_ "GenSigMaxLatency" SG_ 2499757105 RrInterAxlDiffLockActvnDrvrReq_I 65;
BA_ "NeedsUpdateBit" SG_ 2499757105 RrInterAxlDiffLockActvnDrvrReq_I 1;
BA_ "Platform_VMCU1_Sig" SG_ 2499757105 RrInterAxlDiffLockActvnDrvrReq_I 1;
BA_ "SeToolAncestorID_SIGNAL" SG_ 2499757105 RrInterAxlDiffLockActvnDrvrReq_I "x0000001D041287CC";
BA_ "SeToolItemID_SIGNAL" SG_ 2499757105 RrInterAxlDiffLockActvnDrvrReq_I "x0000001D041287CC";
BA_ "SeToolName_SIGNAL" SG_ 2499757105 RrInterAxlDiffLockActvnDrvrReq_I "RearInteraxleDiffLockActivationDriverRequest";
BA_ "SeToolVersion_SIGNAL" SG_ 2499757105 RrInterAxlDiffLockActvnDrvrReq_I "1";
BA_ "SystemSignalLongSymbol" SG_ 2499757105 RrInterAxlDiffLockActvnDrvrReq_I "RrInterAxlDiffLockActvnDrvrReq_ISig_3";
BA_ "GenSigSendType" SG_ 2499757105 RrItrWhl2DiffLockActvnDrvrReq_UB 7;
BA_ "SystemSignalLongSymbol" SG_ 2499757105 RrItrWhl2DiffLockActvnDrvrReq_UB "RrItrWhl2DiffLockActvnDrvrReq_UB_ISig_3";
BA_ "GenSigCycleTime" SG_ 2499757105 HSADriverRequest 100;
BA_ "GenSigCycleTimeActive" SG_ 2499757105 HSADriverRequest 100;
BA_ "GenSigStartValue" SG_ 2499757105 HSADriverRequest 3;
BA_ "GenSigMaxLatency" SG_ 2499757105 HSADriverRequest 65;
BA_ "Platform_VMCU1_Sig" SG_ 2499757105 HSADriverRequest 1;
BA_ "SeToolAncestorID_SIGNAL" SG_ 2499757105 HSADriverRequest "x0000001D0410BAC9";
BA_ "SeToolItemID_SIGNAL" SG_ 2499757105 HSADriverRequest "x0000001D0410BAC9";
BA_ "SeToolName_SIGNAL" SG_ 2499757105 HSADriverRequest "HSADriverRequest";
BA_ "SeToolVersion_SIGNAL" SG_ 2499757105 HSADriverRequest "1";
BA_ "GenSigCycleTime" SG_ 2499757105 AutRrAxleDiffLockActvnDrvrReq 100;
BA_ "GenSigCycleTimeActive" SG_ 2499757105 AutRrAxleDiffLockActvnDrvrReq 100;
BA_ "GenSigStartValue" SG_ 2499757105 AutRrAxleDiffLockActvnDrvrReq 3;
BA_ "GenSigMaxLatency" SG_ 2499757105 AutRrAxleDiffLockActvnDrvrReq 65;
BA_ "Platform_VMCU1_Sig" SG_ 2499757105 AutRrAxleDiffLockActvnDrvrReq 1;
BA_ "SeToolAncestorID_SIGNAL" SG_ 2499757105 AutRrAxleDiffLockActvnDrvrReq "x0000001D041287CA";
BA_ "SeToolItemID_SIGNAL" SG_ 2499757105 AutRrAxleDiffLockActvnDrvrReq "x0000001D041287CA";
BA_ "SeToolName_SIGNAL" SG_ 2499757105 AutRrAxleDiffLockActvnDrvrReq "AutomaticRearAxleDiffLockActivationDriverRequest";
BA_ "SeToolVersion_SIGNAL" SG_ 2499757105 AutRrAxleDiffLockActvnDrvrReq "1";
BA_ "GenSigCycleTime" SG_ 2499757105 RrItrWhl2DiffLockActvnDrvrReq_IS 100;
BA_ "GenSigCycleTimeActive" SG_ 2499757105 RrItrWhl2DiffLockActvnDrvrReq_IS 100;
BA_ "GenSigStartValue" SG_ 2499757105 RrItrWhl2DiffLockActvnDrvrReq_IS 3;
BA_ "NeedsUpdateBit" SG_ 2499757105 RrItrWhl2DiffLockActvnDrvrReq_IS 1;
BA_ "SystemSignalLongSymbol" SG_ 2499757105 RrItrWhl2DiffLockActvnDrvrReq_IS "RrItrWhl2DiffLockActvnDrvrReq_ISig_3";
BA_ "GenSigCycleTime" SG_ 2499757105 ABSInhibitionRequest 100;
BA_ "GenSigCycleTimeActive" SG_ 2499757105 ABSInhibitionRequest 100;
BA_ "GenSigStartValue" SG_ 2499757105 ABSInhibitionRequest 3;
BA_ "Platform_VMCU1_Sig" SG_ 2499757105 ABSInhibitionRequest 1;
BA_ "GenSigCycleTime" SG_ 2499757105 TractionControlDriverRqst_ISig_3 100;
BA_ "GenSigCycleTimeActive" SG_ 2499757105 TractionControlDriverRqst_ISig_3 100;
BA_ "GenSigStartValue" SG_ 2499757105 TractionControlDriverRqst_ISig_3 7;
BA_ "GenSigCycleTime" SG_ 2566844689 CCActive_ISig_3 100;
BA_ "GenSigCycleTimeActive" SG_ 2566844689 CCActive_ISig_3 100;
BA_ "GenSigStartValue" SG_ 2566844689 CCActive_ISig_3 3;
BA_ "Platform_VMCU1_Sig" SG_ 2566844689 CCActive_ISig_3 1;
BA_ "SPN" SG_ 2566844689 CCActive_ISig_3 595;
BA_ "SeToolAncestorID_SIGNAL" SG_ 2566844689 CCActive_ISig_3 "x0000001D04134A65";
BA_ "SeToolItemID_SIGNAL" SG_ 2566844689 CCActive_ISig_3 "x0000001D04134A65";
BA_ "SeToolName_SIGNAL" SG_ 2566844689 CCActive_ISig_3 "CCActive";
BA_ "SeToolVersion_SIGNAL" SG_ 2566844689 CCActive_ISig_3 "1";
BA_ "GenSigCycleTime" SG_ 2566844689 BrakeSwitch_ISig_3 100;
BA_ "GenSigCycleTimeActive" SG_ 2566844689 BrakeSwitch_ISig_3 100;
BA_ "GenSigStartValue" SG_ 2566844689 BrakeSwitch_ISig_3 3;
BA_ "Platform_VMCU1_Sig" SG_ 2566844689 BrakeSwitch_ISig_3 1;
BA_ "SPN" SG_ 2566844689 BrakeSwitch_ISig_3 597;
BA_ "SeToolAncestorID_SIGNAL" SG_ 2566844689 BrakeSwitch_ISig_3 "x0000001D0410DBED";
BA_ "SeToolItemID_SIGNAL" SG_ 2566844689 BrakeSwitch_ISig_3 "x0000001D0410DBED";
BA_ "SeToolName_SIGNAL" SG_ 2566844689 BrakeSwitch_ISig_3 "BrakeSwitch";
BA_ "SeToolVersion_SIGNAL" SG_ 2566844689 BrakeSwitch_ISig_3 "1";
BA_ "GenSigCycleTime" SG_ 2566844689 CruiseControlStates 100;
BA_ "GenSigCycleTimeActive" SG_ 2566844689 CruiseControlStates 100;
BA_ "GenSigStartValue" SG_ 2566844689 CruiseControlStates 7;
BA_ "Platform_VMCU1_Sig" SG_ 2566844689 CruiseControlStates 1;
BA_ "SPN" SG_ 2566844689 CruiseControlStates 527;
BA_ "GenSigCycleTime" SG_ 2566844689 WheelBasedVehicleSpeed_ISig_3 100;
BA_ "GenSigCycleTimeActive" SG_ 2566844689 WheelBasedVehicleSpeed_ISig_3 100;
BA_ "GenSigStartValue" SG_ 2566844689 WheelBasedVehicleSpeed_ISig_3 65535;
BA_ "Platform_FactoryIf_Sig" SG_ 2566844689 WheelBasedVehicleSpeed_ISig_3 1;
BA_ "Platform_VMCU1_Sig" SG_ 2566844689 WheelBasedVehicleSpeed_ISig_3 1;
BA_ "SPN" SG_ 2566844689 WheelBasedVehicleSpeed_ISig_3 84;
BA_ "SeToolAncestorID_SIGNAL" SG_ 2566844689 WheelBasedVehicleSpeed_ISig_3 "x0000001D040FEBD2";
BA_ "SeToolItemID_SIGNAL" SG_ 2566844689 WheelBasedVehicleSpeed_ISig_3 "x0000001D040FEBD2";
BA_ "SeToolName_SIGNAL" SG_ 2566844689 WheelBasedVehicleSpeed_ISig_3 "Wheel-BasedVehicleSpeed";
BA_ "SeToolVersion_SIGNAL" SG_ 2566844689 WheelBasedVehicleSpeed_ISig_3 "1";
BA_ "GenSigCycleTime" SG_ 2566844689 ClutchSwitch_ISig_3 100;
BA_ "GenSigCycleTimeActive" SG_ 2566844689 ClutchSwitch_ISig_3 100;
BA_ "GenSigStartValue" SG_ 2566844689 ClutchSwitch_ISig_3 3;
BA_ "Platform_VMCU1_Sig" SG_ 2566844689 ClutchSwitch_ISig_3 1;
BA_ "SPN" SG_ 2566844689 ClutchSwitch_ISig_3 598;
BA_ "SeToolAncestorID_SIGNAL" SG_ 2566844689 ClutchSwitch_ISig_3 "x0000001D0410BACB";
BA_ "SeToolItemID_SIGNAL" SG_ 2566844689 ClutchSwitch_ISig_3 "x0000001D0410BACB";
BA_ "SeToolName_SIGNAL" SG_ 2566844689 ClutchSwitch_ISig_3 "ClutchSwitch";
BA_ "SeToolVersion_SIGNAL" SG_ 2566844689 ClutchSwitch_ISig_3 "1";
BA_ "GenSigCycleTime" SG_ 2499779302 BBAirDumpRequest_ISig_3 100;
BA_ "GenSigCycleTimeActive" SG_ 2499779302 BBAirDumpRequest_ISig_3 100;
BA_ "GenSigStartValue" SG_ 2499779302 BBAirDumpRequest_ISig_3 3;
BA_ "GenSigCycleTime" SG_ 2499779302 CtaBs_HSABbRequest_ISig_3 100;
BA_ "GenSigCycleTimeActive" SG_ 2499779302 CtaBs_HSABbRequest_ISig_3 100;
BA_ "GenSigStartValue" SG_ 2499779302 CtaBs_HSABbRequest_ISig_3 3;
BA_ "GenSigMaxLatency" SG_ 2499779302 CtaBs_HSABbRequest_ISig_3 100;
BA_ "Platform_VMCU1_Sig" SG_ 2499779302 CtaBs_HSABbRequest_ISig_3 1;
BA_ "GenSigCycleTime" SG_ 2566748928 DPFSootLevel 100;
BA_ "GenSigCycleTimeActive" SG_ 2566748928 DPFSootLevel 100;
BA_ "GenSigStartValue" SG_ 2566748928 DPFSootLevel 255;
BA_ "Platform_VMCU1_Sig" SG_ 2566748928 DPFSootLevel 1;
BA_ "SPN" SG_ 2566748928 DPFSootLevel 3719;
BA_ "GenSigCycleTime" SG_ 2565869312 Aftertreat1NOxConcOutlet 100;
BA_ "GenSigCycleTimeActive" SG_ 2565869312 Aftertreat1NOxConcOutlet 100;
BA_ "GenSigStartValue" SG_ 2565869312 Aftertreat1NOxConcOutlet 65535;
BA_ "SPN" SG_ 2565869312 Aftertreat1NOxConcOutlet 3226;
BA_ "GenSigCycleTime" SG_ 2566763008 DPFPressureDiff 100;
BA_ "GenSigCycleTimeActive" SG_ 2566763008 DPFPressureDiff 100;
BA_ "GenSigStartValue" SG_ 2566763008 DPFPressureDiff 65535;
BA_ "SPN" SG_ 2566763008 DPFPressureDiff 3251;
BA_ "GenSigCycleTime" SG_ 2566763520 Aftertreatment1ExhaustTemp1 100;
BA_ "GenSigCycleTimeActive" SG_ 2566763520 Aftertreatment1ExhaustTemp1 100;
BA_ "GenSigStartValue" SG_ 2566763520 Aftertreatment1ExhaustTemp1 65535;
BA_ "SPN" SG_ 2566763520 Aftertreatment1ExhaustTemp1 3241;
BA_ "GenSigCycleTime" SG_ 2565869056 EngineExhaust1NOx1 100;
BA_ "GenSigCycleTimeActive" SG_ 2565869056 EngineExhaust1NOx1 100;
BA_ "GenSigStartValue" SG_ 2565869056 EngineExhaust1NOx1 65535;
BA_ "SPN" SG_ 2565869056 EngineExhaust1NOx1 3216;
BA_ "GenSigCycleTime" SG_ 2566845713 AmbientAirTemperature_ISig_3 100;
BA_ "GenSigCycleTimeActive" SG_ 2566845713 AmbientAirTemperature_ISig_3 100;
BA_ "GenSigStartValue" SG_ 2566845713 AmbientAirTemperature_ISig_3 65535;
BA_ "Platform_FactoryIf_Sig" SG_ 2566845713 AmbientAirTemperature_ISig_3 1;
BA_ "Platform_VMCU1_Sig" SG_ 2566845713 AmbientAirTemperature_ISig_3 1;
BA_ "SPN" SG_ 2566845713 AmbientAirTemperature_ISig_3 171;
BA_ "SeToolAncestorID_SIGNAL" SG_ 2566845713 AmbientAirTemperature_ISig_3 "x0000001D040FEBC8";
BA_ "SeToolItemID_SIGNAL" SG_ 2566845713 AmbientAirTemperature_ISig_3 "x0000001D040FEBC8";
BA_ "SeToolName_SIGNAL" SG_ 2566845713 AmbientAirTemperature_ISig_3 "AmbientAirTemperature";
BA_ "SeToolVersion_SIGNAL" SG_ 2566845713 AmbientAirTemperature_ISig_3 "1";
BA_ "GenSigSendType" SG_ 2566827537 ParkingAndTrailerAirPressure_ISi 1;
BA_ "GenSigStartValue" SG_ 2566827537 ParkingAndTrailerAirPressure_ISi 255;
BA_ "Platform_VMCU1_Sig" SG_ 2566827537 ParkingAndTrailerAirPressure_ISi 1;
BA_ "SPN" SG_ 2566827537 ParkingAndTrailerAirPressure_ISi 1086;
BA_ "SeToolAncestorID_SIGNAL" SG_ 2566827537 ParkingAndTrailerAirPressure_ISi "x0000001D0410CEE7";
BA_ "SeToolItemID_SIGNAL" SG_ 2566827537 ParkingAndTrailerAirPressure_ISi "x0000001D0410CEE7";
BA_ "SeToolName_SIGNAL" SG_ 2566827537 ParkingAndTrailerAirPressure_ISi "Parking/TrailerAirPressure";
BA_ "SeToolVersion_SIGNAL" SG_ 2566827537 ParkingAndTrailerAirPressure_ISi "1";
BA_ "SystemSignalLongSymbol" SG_ 2566827537 ParkingAndTrailerAirPressure_ISi "ParkingAndTrailerAirPressure_ISig_3";
BA_ "GenSigSendType" SG_ 2566827537 ServiceBrakeAirPrsCircuit2_ISig_ 1;
BA_ "GenSigStartValue" SG_ 2566827537 ServiceBrakeAirPrsCircuit2_ISig_ 255;
BA_ "Platform_VMCU1_Sig" SG_ 2566827537 ServiceBrakeAirPrsCircuit2_ISig_ 1;
BA_ "SPN" SG_ 2566827537 ServiceBrakeAirPrsCircuit2_ISig_ 1088;
BA_ "SeToolAncestorID_SIGNAL" SG_ 2566827537 ServiceBrakeAirPrsCircuit2_ISig_ "x0000001D0410CEEB";
BA_ "SeToolItemID_SIGNAL" SG_ 2566827537 ServiceBrakeAirPrsCircuit2_ISig_ "x0000001D0410CEEB";
BA_ "SeToolName_SIGNAL" SG_ 2566827537 ServiceBrakeAirPrsCircuit2_ISig_ "ServiceBrakeAirPressureCircuit2";
BA_ "SeToolVersion_SIGNAL" SG_ 2566827537 ServiceBrakeAirPrsCircuit2_ISig_ "1";
BA_ "SystemSignalLongSymbol" SG_ 2566827537 ServiceBrakeAirPrsCircuit2_ISig_ "ServiceBrakeAirPrsCircuit2_ISig_3";
BA_ "GenSigSendType" SG_ 2566827537 ServiceBrakeAirPrsCircuit1_ISig_ 1;
BA_ "GenSigStartValue" SG_ 2566827537 ServiceBrakeAirPrsCircuit1_ISig_ 255;
BA_ "Platform_VMCU1_Sig" SG_ 2566827537 ServiceBrakeAirPrsCircuit1_ISig_ 1;
BA_ "SPN" SG_ 2566827537 ServiceBrakeAirPrsCircuit1_ISig_ 1087;
BA_ "SeToolAncestorID_SIGNAL" SG_ 2566827537 ServiceBrakeAirPrsCircuit1_ISig_ "x0000001D0410CEE9";
BA_ "SeToolItemID_SIGNAL" SG_ 2566827537 ServiceBrakeAirPrsCircuit1_ISig_ "x0000001D0410CEE9";
BA_ "SeToolName_SIGNAL" SG_ 2566827537 ServiceBrakeAirPrsCircuit1_ISig_ "ServiceBrakeAirPressureCircuit1";
BA_ "SeToolVersion_SIGNAL" SG_ 2566827537 ServiceBrakeAirPrsCircuit1_ISig_ "1";
BA_ "SystemSignalLongSymbol" SG_ 2566827537 ServiceBrakeAirPrsCircuit1_ISig_ "ServiceBrakeAirPrsCircuit1_ISig_3";
BA_ "GenSigCycleTime" SG_ 2566892605 LNGTimeToVent_ISig_3 100;
BA_ "GenSigCycleTimeActive" SG_ 2566892605 LNGTimeToVent_ISig_3 100;
BA_ "GenSigStartValue" SG_ 2566892605 LNGTimeToVent_ISig_3 65535;
BA_ "GenSigCycleTime" SG_ 2566892605 LNGRestrictionStatus_Spare1_ISig 100;
BA_ "GenSigCycleTimeActive" SG_ 2566892605 LNGRestrictionStatus_Spare1_ISig 100;
BA_ "Platform_VMCU1_Sig" SG_ 2566892605 LNGRestrictionStatus_Spare1_ISig 1;
BA_ "SystemSignalLongSymbol" SG_ 2566892605 LNGRestrictionStatus_Spare1_ISig "LNGRestrictionStatus_Spare1_ISig_3";
BA_ "GenSigCycleTime" SG_ 2566892605 LNGRestrictionStatus_Spare3_ISig 100;
BA_ "GenSigCycleTimeActive" SG_ 2566892605 LNGRestrictionStatus_Spare3_ISig 100;
BA_ "Platform_VMCU1_Sig" SG_ 2566892605 LNGRestrictionStatus_Spare3_ISig 1;
BA_ "SystemSignalLongSymbol" SG_ 2566892605 LNGRestrictionStatus_Spare3_ISig "LNGRestrictionStatus_Spare3_ISig_3";
BA_ "GenSigCycleTime" SG_ 2566892605 LNGRestrictionStatus_V2Closed_IS 100;
BA_ "GenSigCycleTimeActive" SG_ 2566892605 LNGRestrictionStatus_V2Closed_IS 100;
BA_ "Platform_VMCU1_Sig" SG_ 2566892605 LNGRestrictionStatus_V2Closed_IS 1;
BA_ "SystemSignalLongSymbol" SG_ 2566892605 LNGRestrictionStatus_V2Closed_IS "LNGRestrictionStatus_V2Closed_ISig_3";
BA_ "GenSigCycleTime" SG_ 2566892605 LNGRestrictionStatus_Spare4_ISig 100;
BA_ "GenSigCycleTimeActive" SG_ 2566892605 LNGRestrictionStatus_Spare4_ISig 100;
BA_ "Platform_VMCU1_Sig" SG_ 2566892605 LNGRestrictionStatus_Spare4_ISig 1;
BA_ "SystemSignalLongSymbol" SG_ 2566892605 LNGRestrictionStatus_Spare4_ISig "LNGRestrictionStatus_Spare4_ISig_3";
BA_ "GenSigCycleTime" SG_ 2566892605 LNGRestrictionStatus_V1Closed_IS 100;
BA_ "GenSigCycleTimeActive" SG_ 2566892605 LNGRestrictionStatus_V1Closed_IS 100;
BA_ "Platform_VMCU1_Sig" SG_ 2566892605 LNGRestrictionStatus_V1Closed_IS 1;
BA_ "SystemSignalLongSymbol" SG_ 2566892605 LNGRestrictionStatus_V1Closed_IS "LNGRestrictionStatus_V1Closed_ISig_3";
BA_ "GenSigCycleTime" SG_ 2566892605 ACM_Available_Log_ISig_3 100;
BA_ "GenSigCycleTimeActive" SG_ 2566892605 ACM_Available_Log_ISig_3 100;
BA_ "GenSigStartValue" SG_ 2566892605 ACM_Available_Log_ISig_3 255;
BA_ "GenSigCycleTime" SG_ 2566892605 LNGRestrictionStatus_Spare2_ISig 100;
BA_ "GenSigCycleTimeActive" SG_ 2566892605 LNGRestrictionStatus_Spare2_ISig 100;
BA_ "Platform_VMCU1_Sig" SG_ 2566892605 LNGRestrictionStatus_Spare2_ISig 1;
BA_ "SystemSignalLongSymbol" SG_ 2566892605 LNGRestrictionStatus_Spare2_ISig "LNGRestrictionStatus_Spare2_ISig_3";
BA_ "GenSigCycleTime" SG_ 2566892605 LNGRestrictionStatus_SInfo_ISig_ 100;
BA_ "GenSigCycleTimeActive" SG_ 2566892605 LNGRestrictionStatus_SInfo_ISig_ 100;
BA_ "GenSigStartValue" SG_ 2566892605 LNGRestrictionStatus_SInfo_ISig_ 3;
BA_ "Platform_VMCU1_Sig" SG_ 2566892605 LNGRestrictionStatus_SInfo_ISig_ 1;
BA_ "SystemSignalLongSymbol" SG_ 2566892605 LNGRestrictionStatus_SInfo_ISig_ "LNGRestrictionStatus_SInfo_ISig_3";
BA_ "GenSigCycleTime" SG_ 2566892093 AdBlueTankTemperature_ISig_3 100;
BA_ "GenSigCycleTimeActive" SG_ 2566892093 AdBlueTankTemperature_ISig_3 100;
BA_ "GenSigStartValue" SG_ 2566892093 AdBlueTankTemperature_ISig_3 50;
BA_ "Platform_VMCU1_Sig" SG_ 2566892093 AdBlueTankTemperature_ISig_3 1;
BA_ "GenSigCycleTime" SG_ 2566892093 LngTank2RemainingGasVolume_ISig_ 100;
BA_ "GenSigCycleTimeActive" SG_ 2566892093 LngTank2RemainingGasVolume_ISig_ 100;
BA_ "GenSigStartValue" SG_ 2566892093 LngTank2RemainingGasVolume_ISig_ 255;
BA_ "Platform_VMCU1_Sig" SG_ 2566892093 LngTank2RemainingGasVolume_ISig_ 1;
BA_ "SystemSignalLongSymbol" SG_ 2566892093 LngTank2RemainingGasVolume_ISig_ "LngTank2RemainingGasVolume_ISig_3";
BA_ "GenSigCycleTime" SG_ 2566892093 LngSystemReadinessStat_ISig_3 100;
BA_ "GenSigCycleTimeActive" SG_ 2566892093 LngSystemReadinessStat_ISig_3 100;
BA_ "GenSigStartValue" SG_ 2566892093 LngSystemReadinessStat_ISig_3 7;
BA_ "Platform_VMCU1_Sig" SG_ 2566892093 LngSystemReadinessStat_ISig_3 1;
BA_ "GenSigCycleTime" SG_ 2566892093 CatalystTankLevel_ISig_3 100;
BA_ "GenSigCycleTimeActive" SG_ 2566892093 CatalystTankLevel_ISig_3 100;
BA_ "GenSigStartValue" SG_ 2566892093 CatalystTankLevel_ISig_3 255;
BA_ "Platform_VMCU1_Sig" SG_ 2566892093 CatalystTankLevel_ISig_3 1;
BA_ "SeToolAncestorID_SIGNAL" SG_ 2566892093 CatalystTankLevel_ISig_3 "x0000001D04148A55";
BA_ "SeToolItemID_SIGNAL" SG_ 2566892093 CatalystTankLevel_ISig_3 "x0000001D04148A55";
BA_ "SeToolName_SIGNAL" SG_ 2566892093 CatalystTankLevel_ISig_3 "CatalystTankLevel";
BA_ "SeToolVersion_SIGNAL" SG_ 2566892093 CatalystTankLevel_ISig_3 "1";
BA_ "GenSigCycleTime" SG_ 2566892093 MIStatusExtACM 100;
BA_ "GenSigCycleTimeActive" SG_ 2566892093 MIStatusExtACM 100;
BA_ "GenSigStartValue" SG_ 2566892093 MIStatusExtACM 3;
BA_ "Platform_VMCU1_Sig" SG_ 2566892093 MIStatusExtACM 1;
BA_ "GenSigCycleTime" SG_ 2566892093 CatalystTankLevelLow_ISig_3 100;
BA_ "GenSigCycleTimeActive" SG_ 2566892093 CatalystTankLevelLow_ISig_3 100;
BA_ "GenSigStartValue" SG_ 2566892093 CatalystTankLevelLow_ISig_3 3;
BA_ "Platform_VMCU1_Sig" SG_ 2566892093 CatalystTankLevelLow_ISig_3 1;
BA_ "SeToolAncestorID_SIGNAL" SG_ 2566892093 CatalystTankLevelLow_ISig_3 "x0000001D04174CD1";
BA_ "SeToolItemID_SIGNAL" SG_ 2566892093 CatalystTankLevelLow_ISig_3 "x0000001D041D5D8F";
BA_ "SeToolName_SIGNAL" SG_ 2566892093 CatalystTankLevelLow_ISig_3 "CatalystTankLevelLow";
BA_ "SeToolVersion_SIGNAL" SG_ 2566892093 CatalystTankLevelLow_ISig_3 "2";
BA_ "GenSigCycleTime" SG_ 2566892093 LngGspWarnStat 100;
BA_ "GenSigCycleTimeActive" SG_ 2566892093 LngGspWarnStat 100;
BA_ "GenSigStartValue" SG_ 2566892093 LngGspWarnStat 3;
BA_ "Platform_VMCU1_Sig" SG_ 2566892093 LngGspWarnStat 1;
BA_ "GenSigCycleTime" SG_ 2566892093 LngTank2WarnStat 100;
BA_ "GenSigCycleTimeActive" SG_ 2566892093 LngTank2WarnStat 100;
BA_ "GenSigStartValue" SG_ 2566892093 LngTank2WarnStat 3;
BA_ "Platform_VMCU1_Sig" SG_ 2566892093 LngTank2WarnStat 1;
BA_ "GenSigCycleTime" SG_ 2566892093 MIDistinctWarningExtACM 100;
BA_ "GenSigCycleTimeActive" SG_ 2566892093 MIDistinctWarningExtACM 100;
BA_ "GenSigStartValue" SG_ 2566892093 MIDistinctWarningExtACM 15;
BA_ "Platform_VMCU1_Sig" SG_ 2566892093 MIDistinctWarningExtACM 1;
BA_ "GenSigCycleTime" SG_ 2566892093 LngTank1RemainingGasVolume_ISig_ 100;
BA_ "GenSigCycleTimeActive" SG_ 2566892093 LngTank1RemainingGasVolume_ISig_ 100;
BA_ "GenSigStartValue" SG_ 2566892093 LngTank1RemainingGasVolume_ISig_ 255;
BA_ "Platform_VMCU1_Sig" SG_ 2566892093 LngTank1RemainingGasVolume_ISig_ 1;
BA_ "SystemSignalLongSymbol" SG_ 2566892093 LngTank1RemainingGasVolume_ISig_ "LngTank1RemainingGasVolume_ISig_3";
BA_ "GenSigCycleTime" SG_ 2566892093 LngTank1WarnStat 100;
BA_ "GenSigCycleTimeActive" SG_ 2566892093 LngTank1WarnStat 100;
BA_ "GenSigStartValue" SG_ 2566892093 LngTank1WarnStat 3;
BA_ "Platform_VMCU1_Sig" SG_ 2566892093 LngTank1WarnStat 1;
BA_ "GenSigCycleTime" SG_ 2566892093 LNGLevel_ISig_3 100;
BA_ "GenSigCycleTimeActive" SG_ 2566892093 LNGLevel_ISig_3 100;
BA_ "GenSigStartValue" SG_ 2566892093 LNGLevel_ISig_3 255;
BA_ "Platform_VMCU1_Sig" SG_ 2566892093 LNGLevel_ISig_3 1;
BA_ "GenSigSendType" SG_ 2632515566 AckTACHOControlSig_LowPrio 1;
BA_ "Platform_VMCU1_Sig" SG_ 2632515566 AckTACHOControlSig_LowPrio 1;
BA_ "GenSigSendType" SG_ 2565406702 AckTACHOControlSig 1;
BA_ "Platform_VMCU1_Sig" SG_ 2565406702 AckTACHOControlSig 1;
BA_ "GenSigCycleTime" SG_ 2499624448 SCRInletTemp 100;
BA_ "GenSigCycleTimeActive" SG_ 2499624448 SCRInletTemp 100;
BA_ "GenSigStartValue" SG_ 2499624448 SCRInletTemp 65535;
BA_ "SPN" SG_ 2499624448 SCRInletTemp 4360;
BA_ "GenSigCycleTime" SG_ 2499624448 SCROutletTemp 100;
BA_ "GenSigCycleTimeActive" SG_ 2499624448 SCROutletTemp 100;
BA_ "GenSigStartValue" SG_ 2499624448 SCROutletTemp 65535;
BA_ "SPN" SG_ 2499624448 SCROutletTemp 4363;
BA_REL_ "GenSigFirstTimeoutTime" BU_SG_REL_ EMS SG_ 2565865739 ASRHillHolderSwitch_ISig_3 3000;
BA_REL_ "GenSigTimeoutTime" BU_SG_REL_ EMS SG_ 2565865739 ASRHillHolderSwitch_ISig_3 600;
BA_REL_ "GenSigFirstTimeoutTime" BU_SG_REL_ CIOM SG_ 2565865739 ASRHillHolderSwitch_ISig_3 3000;
BA_REL_ "GenSigTimeoutTime" BU_SG_REL_ CIOM SG_ 2565865739 ASRHillHolderSwitch_ISig_3 600;
BA_REL_ "GenSigFirstTimeoutTime" BU_SG_REL_ IC3 SG_ 2565865739 ASRHillHolderSwitch_ISig_3 3000;
BA_REL_ "GenSigTimeoutTime" BU_SG_REL_ IC3 SG_ 2565865739 ASRHillHolderSwitch_ISig_3 600;
BA_REL_ "GenSigFirstTimeoutTime" BU_SG_REL_ BBM SG_ 2565865739 ASRHillHolderSwitch_ISig_3 3000;
BA_REL_ "GenSigTimeoutTime" BU_SG_REL_ BBM SG_ 2565865739 ASRHillHolderSwitch_ISig_3 600;
BA_REL_ "GenSigFirstTimeoutTime" BU_SG_REL_ EMS SG_ 2565865739 ABSFullyOperational_ISig_3 3000;
BA_REL_ "GenSigTimeoutTime" BU_SG_REL_ EMS SG_ 2565865739 ABSFullyOperational_ISig_3 600;
BA_REL_ "GenSigFirstTimeoutTime" BU_SG_REL_ DACU SG_ 2565865739 ABSFullyOperational_ISig_3 3000;
BA_REL_ "GenSigTimeoutTime" BU_SG_REL_ DACU SG_ 2565865739 ABSFullyOperational_ISig_3 600;
BA_REL_ "GenSigFirstTimeoutTime" BU_SG_REL_ BBM SG_ 2565865739 ABSFullyOperational_ISig_3 3000;
BA_REL_ "GenSigTimeoutTime" BU_SG_REL_ BBM SG_ 2565865739 ABSFullyOperational_ISig_3 600;
BA_REL_ "GenSigFirstTimeoutTime" BU_SG_REL_ VMCU SG_ 2565865739 ABSFullyOperational_ISig_3 3000;
BA_REL_ "GenSigTimeoutTime" BU_SG_REL_ VMCU SG_ 2565865739 ABSFullyOperational_ISig_3 600;
BA_REL_ "GenSigFirstTimeoutTime" BU_SG_REL_ TECU SG_ 2565865739 ABSFullyOperational_ISig_3 3000;
BA_REL_ "GenSigTimeoutTime" BU_SG_REL_ TECU SG_ 2565865739 ABSFullyOperational_ISig_3 600;
BA_REL_ "GenSigFirstTimeoutTime" BU_SG_REL_ IC3 SG_ 2565865739 ABSFullyOperational_ISig_3 3000;
BA_REL_ "GenSigTimeoutTime" BU_SG_REL_ IC3 SG_ 2565865739 ABSFullyOperational_ISig_3 600;
BA_REL_ "GenSigFirstTimeoutTime" BU_SG_REL_ IC3 SG_ 2565865739 EBSRedWarningSignal_ISig_3 3000;
BA_REL_ "GenSigTimeoutTime" BU_SG_REL_ IC3 SG_ 2565865739 EBSRedWarningSignal_ISig_3 600;
BA_REL_ "GenSigFirstTimeoutTime" BU_SG_REL_ BBM SG_ 2565865739 EBSRedWarningSignal_ISig_3 3000;
BA_REL_ "GenSigTimeoutTime" BU_SG_REL_ BBM SG_ 2565865739 EBSRedWarningSignal_ISig_3 600;
BA_REL_ "GenSigFirstTimeoutTime" BU_SG_REL_ BBM SG_ 2565865739 ASREngineControlActive_ISig_3 3000;
BA_REL_ "GenSigTimeoutTime" BU_SG_REL_ BBM SG_ 2565865739 ASREngineControlActive_ISig_3 600;
BA_REL_ "GenSigFirstTimeoutTime" BU_SG_REL_ EMS SG_ 2565865739 ASREngineControlActive_ISig_3 3000;
BA_REL_ "GenSigTimeoutTime" BU_SG_REL_ EMS SG_ 2565865739 ASREngineControlActive_ISig_3 600;
BA_REL_ "GenSigFirstTimeoutTime" BU_SG_REL_ VMCU SG_ 2565865739 ASREngineControlActive_ISig_3 3000;
BA_REL_ "GenSigTimeoutTime" BU_SG_REL_ VMCU SG_ 2565865739 ASREngineControlActive_ISig_3 600;
BA_REL_ "GenSigFirstTimeoutTime" BU_SG_REL_ TECU SG_ 2565865739 ASREngineControlActive_ISig_3 3000;
BA_REL_ "GenSigTimeoutTime" BU_SG_REL_ TECU SG_ 2565865739 ASREngineControlActive_ISig_3 600;
BA_REL_ "GenSigFirstTimeoutTime" BU_SG_REL_ VMCU SG_ 2565865739 ASRBrakeControlActive_ISig_3 3000;
BA_REL_ "GenSigTimeoutTime" BU_SG_REL_ VMCU SG_ 2565865739 ASRBrakeControlActive_ISig_3 600;
BA_REL_ "GenSigFirstTimeoutTime" BU_SG_REL_ EMS SG_ 2565865739 ASRBrakeControlActive_ISig_3 3000;
BA_REL_ "GenSigTimeoutTime" BU_SG_REL_ EMS SG_ 2565865739 ASRBrakeControlActive_ISig_3 600;
BA_REL_ "GenSigFirstTimeoutTime" BU_SG_REL_ TECU SG_ 2565865739 ASRBrakeControlActive_ISig_3 3000;
BA_REL_ "GenSigTimeoutTime" BU_SG_REL_ TECU SG_ 2565865739 ASRBrakeControlActive_ISig_3 600;
BA_REL_ "GenSigFirstTimeoutTime" BU_SG_REL_ BBM SG_ 2565865739 ASRBrakeControlActive_ISig_3 3000;
BA_REL_ "GenSigTimeoutTime" BU_SG_REL_ BBM SG_ 2565865739 ASRBrakeControlActive_ISig_3 600;
BA_REL_ "GenSigFirstTimeoutTime" BU_SG_REL_ BBM SG_ 2565865739 ABSEBSAmberWarningSignal_ISig_3 3000;
BA_REL_ "GenSigTimeoutTime" BU_SG_REL_ BBM SG_ 2565865739 ABSEBSAmberWarningSignal_ISig_3 600;
BA_REL_ "GenSigFirstTimeoutTime" BU_SG_REL_ IC3 SG_ 2565865739 ABSEBSAmberWarningSignal_ISig_3 3000;
BA_REL_ "GenSigTimeoutTime" BU_SG_REL_ IC3 SG_ 2565865739 ABSEBSAmberWarningSignal_ISig_3 600;
BA_REL_ "GenSigFirstTimeoutTime" BU_SG_REL_ DACU SG_ 2565865739 AntiLockBrakingActive_ISig_3 3000;
BA_REL_ "GenSigTimeoutTime" BU_SG_REL_ DACU SG_ 2565865739 AntiLockBrakingActive_ISig_3 600;
BA_REL_ "GenSigFirstTimeoutTime" BU_SG_REL_ IC3 SG_ 2565865739 AntiLockBrakingActive_ISig_3 3000;
BA_REL_ "GenSigTimeoutTime" BU_SG_REL_ IC3 SG_ 2565865739 AntiLockBrakingActive_ISig_3 600;
BA_REL_ "GenSigFirstTimeoutTime" BU_SG_REL_ EMS SG_ 2565865739 AntiLockBrakingActive_ISig_3 3000;
BA_REL_ "GenSigTimeoutTime" BU_SG_REL_ EMS SG_ 2565865739 AntiLockBrakingActive_ISig_3 600;
BA_REL_ "GenSigFirstTimeoutTime" BU_SG_REL_ BBM SG_ 2565865739 AntiLockBrakingActive_ISig_3 3000;
BA_REL_ "GenSigTimeoutTime" BU_SG_REL_ BBM SG_ 2565865739 AntiLockBrakingActive_ISig_3 600;
BA_REL_ "GenSigFirstTimeoutTime" BU_SG_REL_ VMCU SG_ 2565865739 AntiLockBrakingActive_ISig_3 3000;
BA_REL_ "GenSigTimeoutTime" BU_SG_REL_ VMCU SG_ 2565865739 AntiLockBrakingActive_ISig_3 600;
BA_REL_ "GenSigFirstTimeoutTime" BU_SG_REL_ CIOM SG_ 2565865739 AntiLockBrakingActive_ISig_3 3000;
BA_REL_ "GenSigTimeoutTime" BU_SG_REL_ CIOM SG_ 2565865739 AntiLockBrakingActive_ISig_3 600;
BA_REL_ "GenSigFirstTimeoutTime" BU_SG_REL_ TECU SG_ 2565865739 AntiLockBrakingActive_ISig_3 3000;
BA_REL_ "GenSigTimeoutTime" BU_SG_REL_ TECU SG_ 2565865739 AntiLockBrakingActive_ISig_3 600;
BA_REL_ "GenSigFirstTimeoutTime" BU_SG_REL_ IC3 SG_ 2566907915 DiagFaultStat_Brake_FailTA_ISig_ 12000;
BA_REL_ "GenSigTimeoutTime" BU_SG_REL_ IC3 SG_ 2566907915 DiagFaultStat_Brake_FailTA_ISig_ 3000;
BA_REL_ "GenSigFirstTimeoutTime" BU_SG_REL_ IC3 SG_ 2566907915 DiagFaultStat_Brake_FailTB_ISig_ 12000;
BA_REL_ "GenSigTimeoutTime" BU_SG_REL_ IC3 SG_ 2566907915 DiagFaultStat_Brake_FailTB_ISig_ 3000;
BA_REL_ "GenSigFirstTimeoutTime" BU_SG_REL_ IC3 SG_ 2566907915 DiagFaultStat_Brake_DtcIdA_ISig_ 12000;
BA_REL_ "GenSigTimeoutTime" BU_SG_REL_ IC3 SG_ 2566907915 DiagFaultStat_Brake_DtcIdA_ISig_ 3000;
BA_REL_ "GenSigFirstTimeoutTime" BU_SG_REL_ IC3 SG_ 2566907915 DiagFaultStat_Brake_EcuAdr_ISig_ 12000;
BA_REL_ "GenSigTimeoutTime" BU_SG_REL_ IC3 SG_ 2566907915 DiagFaultStat_Brake_EcuAdr_ISig_ 3000;
BA_REL_ "GenSigFirstTimeoutTime" BU_SG_REL_ IC3 SG_ 2566907915 DiagFaultStat_Brake_DtcIdB_ISig_ 12000;
BA_REL_ "GenSigTimeoutTime" BU_SG_REL_ IC3 SG_ 2566907915 DiagFaultStat_Brake_DtcIdB_ISig_ 3000;
BA_REL_ "GenSigFirstTimeoutTime" BU_SG_REL_ IC3 SG_ 2566907965 DiagFaultStat_ACM_DtcIdB_ISig_3 24000;
BA_REL_ "GenSigTimeoutTime" BU_SG_REL_ IC3 SG_ 2566907965 DiagFaultStat_ACM_DtcIdB_ISig_3 6000;
BA_REL_ "GenSigFirstTimeoutTime" BU_SG_REL_ IC3 SG_ 2566907965 DiagFaultStat_ACM_FailTA_ISig_3 24000;
BA_REL_ "GenSigTimeoutTime" BU_SG_REL_ IC3 SG_ 2566907965 DiagFaultStat_ACM_FailTA_ISig_3 6000;
BA_REL_ "GenSigFirstTimeoutTime" BU_SG_REL_ IC3 SG_ 2566907965 DiagFaultStat_ACM_FailTB_ISig_3 24000;
BA_REL_ "GenSigTimeoutTime" BU_SG_REL_ IC3 SG_ 2566907965 DiagFaultStat_ACM_FailTB_ISig_3 6000;
BA_REL_ "GenSigFirstTimeoutTime" BU_SG_REL_ IC3 SG_ 2566907965 DiagFaultStat_ACM_EcuAdr_ISig_3 24000;
BA_REL_ "GenSigTimeoutTime" BU_SG_REL_ IC3 SG_ 2566907965 DiagFaultStat_ACM_EcuAdr_ISig_3 6000;
BA_REL_ "GenSigFirstTimeoutTime" BU_SG_REL_ IC3 SG_ 2566907965 DiagFaultStat_ACM_DtcIdA_ISig_3 24000;
BA_REL_ "GenSigTimeoutTime" BU_SG_REL_ IC3 SG_ 2566907965 DiagFaultStat_ACM_DtcIdA_ISig_3 6000;
BA_REL_ "GenSigFirstTimeoutTime" BU_SG_REL_ TECU SG_ 2566749184 DPFC1_ActiveRegeneratStatus_ISig 24000;
BA_REL_ "GenSigTimeoutTime" BU_SG_REL_ TECU SG_ 2566749184 DPFC1_ActiveRegeneratStatus_ISig 6000;
BA_REL_ "GenSigFirstTimeoutTime" BU_SG_REL_ IC3 SG_ 2566749184 DPFC1_ActiveRegeneratStatus_ISig 24000;
BA_REL_ "GenSigTimeoutTime" BU_SG_REL_ IC3 SG_ 2566749184 DPFC1_ActiveRegeneratStatus_ISig 6000;
BA_REL_ "GenSigFirstTimeoutTime" BU_SG_REL_ VMCU SG_ 2566749184 DPFC1_ActiveRegeneratStatus_ISig 24000;
BA_REL_ "GenSigTimeoutTime" BU_SG_REL_ VMCU SG_ 2566749184 DPFC1_ActiveRegeneratStatus_ISig 6000;
BA_REL_ "GenSigFirstTimeoutTime" BU_SG_REL_ BBM SG_ 2566749184 DPFC1_ActiveRegeneratStatus_ISig 24000;
BA_REL_ "GenSigTimeoutTime" BU_SG_REL_ BBM SG_ 2566749184 DPFC1_ActiveRegeneratStatus_ISig 6000;
BA_REL_ "GenSigFirstTimeoutTime" BU_SG_REL_ TECU SG_ 2566749184 DPFC1_LampCommand_ISig_3 24000;
BA_REL_ "GenSigTimeoutTime" BU_SG_REL_ TECU SG_ 2566749184 DPFC1_LampCommand_ISig_3 6000;
BA_REL_ "GenSigFirstTimeoutTime" BU_SG_REL_ IC3 SG_ 2566749184 DPFC1_LampCommand_ISig_3 24000;
BA_REL_ "GenSigTimeoutTime" BU_SG_REL_ IC3 SG_ 2566749184 DPFC1_LampCommand_ISig_3 6000;
BA_REL_ "GenSigFirstTimeoutTime" BU_SG_REL_ VMCU SG_ 2566749184 DPFC1_LampCommand_ISig_3 24000;
BA_REL_ "GenSigTimeoutTime" BU_SG_REL_ VMCU SG_ 2566749184 DPFC1_LampCommand_ISig_3 6000;
BA_REL_ "GenSigFirstTimeoutTime" BU_SG_REL_ BBM SG_ 2566749184 DPFC1_LampCommand_ISig_3 24000;
BA_REL_ "GenSigTimeoutTime" BU_SG_REL_ BBM SG_ 2566749184 DPFC1_LampCommand_ISig_3 6000;
BA_REL_ "GenSigFirstTimeoutTime" BU_SG_REL_ TECU SG_ 2566749184 DPFC1_InhibTempSystemLock_ISig_3 24000;
BA_REL_ "GenSigTimeoutTime" BU_SG_REL_ TECU SG_ 2566749184 DPFC1_InhibTempSystemLock_ISig_3 6000;
BA_REL_ "GenSigFirstTimeoutTime" BU_SG_REL_ IC3 SG_ 2566749184 DPFC1_InhibTempSystemLock_ISig_3 24000;
BA_REL_ "GenSigTimeoutTime" BU_SG_REL_ IC3 SG_ 2566749184 DPFC1_InhibTempSystemLock_ISig_3 6000;
BA_REL_ "GenSigFirstTimeoutTime" BU_SG_REL_ BBM SG_ 2566749184 DPFC1_InhibTempSystemLock_ISig_3 24000;
BA_REL_ "GenSigTimeoutTime" BU_SG_REL_ BBM SG_ 2566749184 DPFC1_InhibTempSystemLock_ISig_3 6000;
BA_REL_ "GenSigFirstTimeoutTime" BU_SG_REL_ VMCU SG_ 2566749184 DPFC1_InhibTempSystemLock_ISig_3 24000;
BA_REL_ "GenSigTimeoutTime" BU_SG_REL_ VMCU SG_ 2566749184 DPFC1_InhibTempSystemLock_ISig_3 6000;
BA_REL_ "GenSigFirstTimeoutTime" BU_SG_REL_ IC3 SG_ 2566749184 DPFC1_InhibOutOfNeutral_ISig_3 24000;
BA_REL_ "GenSigTimeoutTime" BU_SG_REL_ IC3 SG_ 2566749184 DPFC1_InhibOutOfNeutral_ISig_3 6000;
BA_REL_ "GenSigFirstTimeoutTime" BU_SG_REL_ TECU SG_ 2566749184 DPFC1_InhibOutOfNeutral_ISig_3 24000;
BA_REL_ "GenSigTimeoutTime" BU_SG_REL_ TECU SG_ 2566749184 DPFC1_InhibOutOfNeutral_ISig_3 6000;
BA_REL_ "GenSigFirstTimeoutTime" BU_SG_REL_ BBM SG_ 2566749184 DPFC1_InhibOutOfNeutral_ISig_3 24000;
BA_REL_ "GenSigTimeoutTime" BU_SG_REL_ BBM SG_ 2566749184 DPFC1_InhibOutOfNeutral_ISig_3 6000;
BA_REL_ "GenSigFirstTimeoutTime" BU_SG_REL_ VMCU SG_ 2566749184 DPFC1_InhibOutOfNeutral_ISig_3 24000;
BA_REL_ "GenSigTimeoutTime" BU_SG_REL_ VMCU SG_ 2566749184 DPFC1_InhibOutOfNeutral_ISig_3 6000;
BA_REL_ "GenSigFirstTimeoutTime" BU_SG_REL_ VMCU SG_ 2566749184 DPFC1_InhibEnginNotWarmUp_ISig_3 24000;
BA_REL_ "GenSigTimeoutTime" BU_SG_REL_ VMCU SG_ 2566749184 DPFC1_InhibEnginNotWarmUp_ISig_3 6000;
BA_REL_ "GenSigFirstTimeoutTime" BU_SG_REL_ IC3 SG_ 2566749184 DPFC1_InhibEnginNotWarmUp_ISig_3 24000;
BA_REL_ "GenSigTimeoutTime" BU_SG_REL_ IC3 SG_ 2566749184 DPFC1_InhibEnginNotWarmUp_ISig_3 6000;
BA_REL_ "GenSigFirstTimeoutTime" BU_SG_REL_ BBM SG_ 2566749184 DPFC1_InhibEnginNotWarmUp_ISig_3 24000;
BA_REL_ "GenSigTimeoutTime" BU_SG_REL_ BBM SG_ 2566749184 DPFC1_InhibEnginNotWarmUp_ISig_3 6000;
BA_REL_ "GenSigFirstTimeoutTime" BU_SG_REL_ TECU SG_ 2566749184 DPFC1_InhibEnginNotWarmUp_ISig_3 24000;
BA_REL_ "GenSigTimeoutTime" BU_SG_REL_ TECU SG_ 2566749184 DPFC1_InhibEnginNotWarmUp_ISig_3 6000;
BA_REL_ "GenSigFirstTimeoutTime" BU_SG_REL_ TECU SG_ 2566749184 DPFC1_InhibDueInhibSwitch_ISig_3 24000;
BA_REL_ "GenSigTimeoutTime" BU_SG_REL_ TECU SG_ 2566749184 DPFC1_InhibDueInhibSwitch_ISig_3 6000;
BA_REL_ "GenSigFirstTimeoutTime" BU_SG_REL_ VMCU SG_ 2566749184 DPFC1_InhibDueInhibSwitch_ISig_3 24000;
BA_REL_ "GenSigTimeoutTime" BU_SG_REL_ VMCU SG_ 2566749184 DPFC1_InhibDueInhibSwitch_ISig_3 6000;
BA_REL_ "GenSigFirstTimeoutTime" BU_SG_REL_ IC3 SG_ 2566749184 DPFC1_InhibDueInhibSwitch_ISig_3 24000;
BA_REL_ "GenSigTimeoutTime" BU_SG_REL_ IC3 SG_ 2566749184 DPFC1_InhibDueInhibSwitch_ISig_3 6000;
BA_REL_ "GenSigFirstTimeoutTime" BU_SG_REL_ BBM SG_ 2566749184 DPFC1_InhibDueInhibSwitch_ISig_3 24000;
BA_REL_ "GenSigTimeoutTime" BU_SG_REL_ BBM SG_ 2566749184 DPFC1_InhibDueInhibSwitch_ISig_3 6000;
BA_REL_ "GenSigFirstTimeoutTime" BU_SG_REL_ TECU SG_ 2566749184 DPFC1_InhibClutchDisengage_ISig_ 24000;
BA_REL_ "GenSigTimeoutTime" BU_SG_REL_ TECU SG_ 2566749184 DPFC1_InhibClutchDisengage_ISig_ 6000;
BA_REL_ "GenSigFirstTimeoutTime" BU_SG_REL_ VMCU SG_ 2566749184 DPFC1_InhibClutchDisengage_ISig_ 24000;
BA_REL_ "GenSigTimeoutTime" BU_SG_REL_ VMCU SG_ 2566749184 DPFC1_InhibClutchDisengage_ISig_ 6000;
BA_REL_ "GenSigFirstTimeoutTime" BU_SG_REL_ BBM SG_ 2566749184 DPFC1_InhibClutchDisengage_ISig_ 24000;
BA_REL_ "GenSigTimeoutTime" BU_SG_REL_ BBM SG_ 2566749184 DPFC1_InhibClutchDisengage_ISig_ 6000;
BA_REL_ "GenSigFirstTimeoutTime" BU_SG_REL_ IC3 SG_ 2566749184 DPFC1_InhibClutchDisengage_ISig_ 24000;
BA_REL_ "GenSigTimeoutTime" BU_SG_REL_ IC3 SG_ 2566749184 DPFC1_InhibClutchDisengage_ISig_ 6000;
BA_REL_ "GenSigFirstTimeoutTime" BU_SG_REL_ TECU SG_ 2566749184 DPFC1_InhibVehSpdAboveAllwdSpd_I 24000;
BA_REL_ "GenSigTimeoutTime" BU_SG_REL_ TECU SG_ 2566749184 DPFC1_InhibVehSpdAboveAllwdSpd_I 6000;
BA_REL_ "GenSigFirstTimeoutTime" BU_SG_REL_ IC3 SG_ 2566749184 DPFC1_InhibVehSpdAboveAllwdSpd_I 24000;
BA_REL_ "GenSigTimeoutTime" BU_SG_REL_ IC3 SG_ 2566749184 DPFC1_InhibVehSpdAboveAllwdSpd_I 6000;
BA_REL_ "GenSigFirstTimeoutTime" BU_SG_REL_ BBM SG_ 2566749184 DPFC1_InhibVehSpdAboveAllwdSpd_I 24000;
BA_REL_ "GenSigTimeoutTime" BU_SG_REL_ BBM SG_ 2566749184 DPFC1_InhibVehSpdAboveAllwdSpd_I 6000;
BA_REL_ "GenSigFirstTimeoutTime" BU_SG_REL_ VMCU SG_ 2566749184 DPFC1_InhibVehSpdAboveAllwdSpd_I 24000;
BA_REL_ "GenSigTimeoutTime" BU_SG_REL_ VMCU SG_ 2566749184 DPFC1_InhibVehSpdAboveAllwdSpd_I 6000;
BA_REL_ "GenSigFirstTimeoutTime" BU_SG_REL_ IC3 SG_ 2566749184 DPFC1_ForcedStatus_ISig_3 24000;
BA_REL_ "GenSigTimeoutTime" BU_SG_REL_ IC3 SG_ 2566749184 DPFC1_ForcedStatus_ISig_3 6000;
BA_REL_ "GenSigFirstTimeoutTime" BU_SG_REL_ BBM SG_ 2566749184 DPFC1_ForcedStatus_ISig_3 24000;
BA_REL_ "GenSigTimeoutTime" BU_SG_REL_ BBM SG_ 2566749184 DPFC1_ForcedStatus_ISig_3 6000;
BA_REL_ "GenSigFirstTimeoutTime" BU_SG_REL_ TECU SG_ 2566749184 DPFC1_ForcedStatus_ISig_3 24000;
BA_REL_ "GenSigTimeoutTime" BU_SG_REL_ TECU SG_ 2566749184 DPFC1_ForcedStatus_ISig_3 6000;
BA_REL_ "GenSigFirstTimeoutTime" BU_SG_REL_ VMCU SG_ 2566749184 DPFC1_ForcedStatus_ISig_3 24000;
BA_REL_ "GenSigTimeoutTime" BU_SG_REL_ VMCU SG_ 2566749184 DPFC1_ForcedStatus_ISig_3 6000;
BA_REL_ "GenSigFirstTimeoutTime" BU_SG_REL_ BBM SG_ 2566749184 DPFC1_InhibPTOActive_ISig_3 24000;
BA_REL_ "GenSigTimeoutTime" BU_SG_REL_ BBM SG_ 2566749184 DPFC1_InhibPTOActive_ISig_3 6000;
BA_REL_ "GenSigFirstTimeoutTime" BU_SG_REL_ TECU SG_ 2566749184 DPFC1_InhibPTOActive_ISig_3 24000;
BA_REL_ "GenSigTimeoutTime" BU_SG_REL_ TECU SG_ 2566749184 DPFC1_InhibPTOActive_ISig_3 6000;
BA_REL_ "GenSigFirstTimeoutTime" BU_SG_REL_ IC3 SG_ 2566749184 DPFC1_InhibPTOActive_ISig_3 24000;
BA_REL_ "GenSigTimeoutTime" BU_SG_REL_ IC3 SG_ 2566749184 DPFC1_InhibPTOActive_ISig_3 6000;
BA_REL_ "GenSigFirstTimeoutTime" BU_SG_REL_ VMCU SG_ 2566749184 DPFC1_InhibPTOActive_ISig_3 24000;
BA_REL_ "GenSigTimeoutTime" BU_SG_REL_ VMCU SG_ 2566749184 DPFC1_InhibPTOActive_ISig_3 6000;
BA_REL_ "GenSigFirstTimeoutTime" BU_SG_REL_ VMCU SG_ 2566749184 DPFC1_InhibVehSpdBelowAllwdSpd_I 24000;
BA_REL_ "GenSigTimeoutTime" BU_SG_REL_ VMCU SG_ 2566749184 DPFC1_InhibVehSpdBelowAllwdSpd_I 6000;
BA_REL_ "GenSigFirstTimeoutTime" BU_SG_REL_ IC3 SG_ 2566749184 DPFC1_InhibVehSpdBelowAllwdSpd_I 24000;
BA_REL_ "GenSigTimeoutTime" BU_SG_REL_ IC3 SG_ 2566749184 DPFC1_InhibVehSpdBelowAllwdSpd_I 6000;
BA_REL_ "GenSigFirstTimeoutTime" BU_SG_REL_ TECU SG_ 2566749184 DPFC1_InhibVehSpdBelowAllwdSpd_I 24000;
BA_REL_ "GenSigTimeoutTime" BU_SG_REL_ TECU SG_ 2566749184 DPFC1_InhibVehSpdBelowAllwdSpd_I 6000;
BA_REL_ "GenSigFirstTimeoutTime" BU_SG_REL_ BBM SG_ 2566749184 DPFC1_InhibVehSpdBelowAllwdSpd_I 24000;
BA_REL_ "GenSigTimeoutTime" BU_SG_REL_ BBM SG_ 2566749184 DPFC1_InhibVehSpdBelowAllwdSpd_I 6000;
BA_REL_ "GenSigFirstTimeoutTime" BU_SG_REL_ BBM SG_ 2566749184 DPFC1_InhibSystemFaultAct_ISig_3 24000;
BA_REL_ "GenSigTimeoutTime" BU_SG_REL_ BBM SG_ 2566749184 DPFC1_InhibSystemFaultAct_ISig_3 6000;
BA_REL_ "GenSigFirstTimeoutTime" BU_SG_REL_ TECU SG_ 2566749184 DPFC1_InhibSystemFaultAct_ISig_3 24000;
BA_REL_ "GenSigTimeoutTime" BU_SG_REL_ TECU SG_ 2566749184 DPFC1_InhibSystemFaultAct_ISig_3 6000;
BA_REL_ "GenSigFirstTimeoutTime" BU_SG_REL_ IC3 SG_ 2566749184 DPFC1_InhibSystemFaultAct_ISig_3 24000;
BA_REL_ "GenSigTimeoutTime" BU_SG_REL_ IC3 SG_ 2566749184 DPFC1_InhibSystemFaultAct_ISig_3 6000;
BA_REL_ "GenSigFirstTimeoutTime" BU_SG_REL_ VMCU SG_ 2566749184 DPFC1_InhibSystemFaultAct_ISig_3 24000;
BA_REL_ "GenSigTimeoutTime" BU_SG_REL_ VMCU SG_ 2566749184 DPFC1_InhibSystemFaultAct_ISig_3 6000;
BA_REL_ "GenSigFirstTimeoutTime" BU_SG_REL_ BBM SG_ 2566749184 DPFC1_PassiveRegenStatus_ISig_3 24000;
BA_REL_ "GenSigTimeoutTime" BU_SG_REL_ BBM SG_ 2566749184 DPFC1_PassiveRegenStatus_ISig_3 6000;
BA_REL_ "GenSigFirstTimeoutTime" BU_SG_REL_ IC3 SG_ 2566749184 DPFC1_PassiveRegenStatus_ISig_3 24000;
BA_REL_ "GenSigTimeoutTime" BU_SG_REL_ IC3 SG_ 2566749184 DPFC1_PassiveRegenStatus_ISig_3 6000;
BA_REL_ "GenSigFirstTimeoutTime" BU_SG_REL_ TECU SG_ 2566749184 DPFC1_PassiveRegenStatus_ISig_3 24000;
BA_REL_ "GenSigTimeoutTime" BU_SG_REL_ TECU SG_ 2566749184 DPFC1_PassiveRegenStatus_ISig_3 6000;
BA_REL_ "GenSigFirstTimeoutTime" BU_SG_REL_ VMCU SG_ 2566749184 DPFC1_PassiveRegenStatus_ISig_3 24000;
BA_REL_ "GenSigTimeoutTime" BU_SG_REL_ VMCU SG_ 2566749184 DPFC1_PassiveRegenStatus_ISig_3 6000;
BA_REL_ "GenSigFirstTimeoutTime" BU_SG_REL_ BBM SG_ 2566749184 DPFC1_InhibPermSystemLock_ISig_3 24000;
BA_REL_ "GenSigTimeoutTime" BU_SG_REL_ BBM SG_ 2566749184 DPFC1_InhibPermSystemLock_ISig_3 6000;
BA_REL_ "GenSigFirstTimeoutTime" BU_SG_REL_ IC3 SG_ 2566749184 DPFC1_InhibPermSystemLock_ISig_3 24000;
BA_REL_ "GenSigTimeoutTime" BU_SG_REL_ IC3 SG_ 2566749184 DPFC1_InhibPermSystemLock_ISig_3 6000;
BA_REL_ "GenSigFirstTimeoutTime" BU_SG_REL_ VMCU SG_ 2566749184 DPFC1_InhibPermSystemLock_ISig_3 24000;
BA_REL_ "GenSigTimeoutTime" BU_SG_REL_ VMCU SG_ 2566749184 DPFC1_InhibPermSystemLock_ISig_3 6000;
BA_REL_ "GenSigFirstTimeoutTime" BU_SG_REL_ TECU SG_ 2566749184 DPFC1_InhibPermSystemLock_ISig_3 24000;
BA_REL_ "GenSigTimeoutTime" BU_SG_REL_ TECU SG_ 2566749184 DPFC1_InhibPermSystemLock_ISig_3 6000;
BA_REL_ "GenSigFirstTimeoutTime" BU_SG_REL_ BBM SG_ 2566749184 DPFC1_AutoARInitConfig_ISig_3 24000;
BA_REL_ "GenSigTimeoutTime" BU_SG_REL_ BBM SG_ 2566749184 DPFC1_AutoARInitConfig_ISig_3 6000;
BA_REL_ "GenSigFirstTimeoutTime" BU_SG_REL_ TECU SG_ 2566749184 DPFC1_AutoARInitConfig_ISig_3 24000;
BA_REL_ "GenSigTimeoutTime" BU_SG_REL_ TECU SG_ 2566749184 DPFC1_AutoARInitConfig_ISig_3 6000;
BA_REL_ "GenSigFirstTimeoutTime" BU_SG_REL_ VMCU SG_ 2566749184 DPFC1_AutoARInitConfig_ISig_3 24000;
BA_REL_ "GenSigTimeoutTime" BU_SG_REL_ VMCU SG_ 2566749184 DPFC1_AutoARInitConfig_ISig_3 6000;
BA_REL_ "GenSigFirstTimeoutTime" BU_SG_REL_ IC3 SG_ 2566749184 DPFC1_AutoARInitConfig_ISig_3 24000;
BA_REL_ "GenSigTimeoutTime" BU_SG_REL_ IC3 SG_ 2566749184 DPFC1_AutoARInitConfig_ISig_3 6000;
BA_REL_ "GenSigFirstTimeoutTime" BU_SG_REL_ TECU SG_ 2566749184 DPFC1_InhibDueLowExhGasTemp_ISig 24000;
BA_REL_ "GenSigTimeoutTime" BU_SG_REL_ TECU SG_ 2566749184 DPFC1_InhibDueLowExhGasTemp_ISig 6000;
BA_REL_ "GenSigFirstTimeoutTime" BU_SG_REL_ BBM SG_ 2566749184 DPFC1_InhibDueLowExhGasTemp_ISig 24000;
BA_REL_ "GenSigTimeoutTime" BU_SG_REL_ BBM SG_ 2566749184 DPFC1_InhibDueLowExhGasTemp_ISig 6000;
BA_REL_ "GenSigFirstTimeoutTime" BU_SG_REL_ VMCU SG_ 2566749184 DPFC1_InhibDueLowExhGasTemp_ISig 24000;
BA_REL_ "GenSigTimeoutTime" BU_SG_REL_ VMCU SG_ 2566749184 DPFC1_InhibDueLowExhGasTemp_ISig 6000;
BA_REL_ "GenSigFirstTimeoutTime" BU_SG_REL_ IC3 SG_ 2566749184 DPFC1_InhibDueLowExhGasTemp_ISig 24000;
BA_REL_ "GenSigTimeoutTime" BU_SG_REL_ IC3 SG_ 2566749184 DPFC1_InhibDueLowExhGasTemp_ISig 6000;
BA_REL_ "GenSigFirstTimeoutTime" BU_SG_REL_ BBM SG_ 2566749184 DPFC1_ExhaustSystHighTempLampCmd 24000;
BA_REL_ "GenSigTimeoutTime" BU_SG_REL_ BBM SG_ 2566749184 DPFC1_ExhaustSystHighTempLampCmd 6000;
BA_REL_ "GenSigFirstTimeoutTime" BU_SG_REL_ IC3 SG_ 2566749184 DPFC1_ExhaustSystHighTempLampCmd 24000;
BA_REL_ "GenSigTimeoutTime" BU_SG_REL_ IC3 SG_ 2566749184 DPFC1_ExhaustSystHighTempLampCmd 6000;
BA_REL_ "GenSigFirstTimeoutTime" BU_SG_REL_ TECU SG_ 2566749184 DPFC1_ExhaustSystHighTempLampCmd 24000;
BA_REL_ "GenSigTimeoutTime" BU_SG_REL_ TECU SG_ 2566749184 DPFC1_ExhaustSystHighTempLampCmd 6000;
BA_REL_ "GenSigFirstTimeoutTime" BU_SG_REL_ VMCU SG_ 2566749184 DPFC1_ExhaustSystHighTempLampCmd 24000;
BA_REL_ "GenSigTimeoutTime" BU_SG_REL_ VMCU SG_ 2566749184 DPFC1_ExhaustSystHighTempLampCmd 6000;
BA_REL_ "GenSigFirstTimeoutTime" BU_SG_REL_ TECU SG_ 2566749184 DPFC1_InhibitStatus_ISig_3 24000;
BA_REL_ "GenSigTimeoutTime" BU_SG_REL_ TECU SG_ 2566749184 DPFC1_InhibitStatus_ISig_3 6000;
BA_REL_ "GenSigFirstTimeoutTime" BU_SG_REL_ BBM SG_ 2566749184 DPFC1_InhibitStatus_ISig_3 24000;
BA_REL_ "GenSigTimeoutTime" BU_SG_REL_ BBM SG_ 2566749184 DPFC1_InhibitStatus_ISig_3 6000;
BA_REL_ "GenSigFirstTimeoutTime" BU_SG_REL_ IC3 SG_ 2566749184 DPFC1_InhibitStatus_ISig_3 24000;
BA_REL_ "GenSigTimeoutTime" BU_SG_REL_ IC3 SG_ 2566749184 DPFC1_InhibitStatus_ISig_3 6000;
BA_REL_ "GenSigFirstTimeoutTime" BU_SG_REL_ VMCU SG_ 2566749184 DPFC1_InhibitStatus_ISig_3 24000;
BA_REL_ "GenSigTimeoutTime" BU_SG_REL_ VMCU SG_ 2566749184 DPFC1_InhibitStatus_ISig_3 6000;
BA_REL_ "GenSigFirstTimeoutTime" BU_SG_REL_ TECU SG_ 2566749184 DPFC1_DPFStatus_ISig_3 24000;
BA_REL_ "GenSigTimeoutTime" BU_SG_REL_ TECU SG_ 2566749184 DPFC1_DPFStatus_ISig_3 6000;
BA_REL_ "GenSigFirstTimeoutTime" BU_SG_REL_ IC3 SG_ 2566749184 DPFC1_DPFStatus_ISig_3 24000;
BA_REL_ "GenSigTimeoutTime" BU_SG_REL_ IC3 SG_ 2566749184 DPFC1_DPFStatus_ISig_3 6000;
BA_REL_ "GenSigFirstTimeoutTime" BU_SG_REL_ VMCU SG_ 2566749184 DPFC1_DPFStatus_ISig_3 24000;
BA_REL_ "GenSigTimeoutTime" BU_SG_REL_ VMCU SG_ 2566749184 DPFC1_DPFStatus_ISig_3 6000;
BA_REL_ "GenSigFirstTimeoutTime" BU_SG_REL_ BBM SG_ 2566749184 DPFC1_DPFStatus_ISig_3 24000;
BA_REL_ "GenSigTimeoutTime" BU_SG_REL_ BBM SG_ 2566749184 DPFC1_DPFStatus_ISig_3 6000;
BA_REL_ "GenSigFirstTimeoutTime" BU_SG_REL_ BBM SG_ 2566749184 DPFC1_InhibParkBrakeNotSet_ISig_ 24000;
BA_REL_ "GenSigTimeoutTime" BU_SG_REL_ BBM SG_ 2566749184 DPFC1_InhibParkBrakeNotSet_ISig_ 6000;
BA_REL_ "GenSigFirstTimeoutTime" BU_SG_REL_ TECU SG_ 2566749184 DPFC1_InhibParkBrakeNotSet_ISig_ 24000;
BA_REL_ "GenSigTimeoutTime" BU_SG_REL_ TECU SG_ 2566749184 DPFC1_InhibParkBrakeNotSet_ISig_ 6000;
BA_REL_ "GenSigFirstTimeoutTime" BU_SG_REL_ IC3 SG_ 2566749184 DPFC1_InhibParkBrakeNotSet_ISig_ 24000;
BA_REL_ "GenSigTimeoutTime" BU_SG_REL_ IC3 SG_ 2566749184 DPFC1_InhibParkBrakeNotSet_ISig_ 6000;
BA_REL_ "GenSigFirstTimeoutTime" BU_SG_REL_ VMCU SG_ 2566749184 DPFC1_InhibParkBrakeNotSet_ISig_ 24000;
BA_REL_ "GenSigTimeoutTime" BU_SG_REL_ VMCU SG_ 2566749184 DPFC1_InhibParkBrakeNotSet_ISig_ 6000;
BA_REL_ "GenSigFirstTimeoutTime" BU_SG_REL_ BBM SG_ 2566749184 DPFC1_InhibDueServiceBrake_ISig_ 24000;
BA_REL_ "GenSigTimeoutTime" BU_SG_REL_ BBM SG_ 2566749184 DPFC1_InhibDueServiceBrake_ISig_ 6000;
BA_REL_ "GenSigFirstTimeoutTime" BU_SG_REL_ VMCU SG_ 2566749184 DPFC1_InhibDueServiceBrake_ISig_ 24000;
BA_REL_ "GenSigTimeoutTime" BU_SG_REL_ VMCU SG_ 2566749184 DPFC1_InhibDueServiceBrake_ISig_ 6000;
BA_REL_ "GenSigFirstTimeoutTime" BU_SG_REL_ TECU SG_ 2566749184 DPFC1_InhibDueServiceBrake_ISig_ 24000;
BA_REL_ "GenSigTimeoutTime" BU_SG_REL_ TECU SG_ 2566749184 DPFC1_InhibDueServiceBrake_ISig_ 6000;
BA_REL_ "GenSigFirstTimeoutTime" BU_SG_REL_ IC3 SG_ 2566749184 DPFC1_InhibDueServiceBrake_ISig_ 24000;
BA_REL_ "GenSigTimeoutTime" BU_SG_REL_ IC3 SG_ 2566749184 DPFC1_InhibDueServiceBrake_ISig_ 6000;
BA_REL_ "GenSigFirstTimeoutTime" BU_SG_REL_ TECU SG_ 2566749184 DPFC1_InhibDueSystemTimeout_ISig 24000;
BA_REL_ "GenSigTimeoutTime" BU_SG_REL_ TECU SG_ 2566749184 DPFC1_InhibDueSystemTimeout_ISig 6000;
BA_REL_ "GenSigFirstTimeoutTime" BU_SG_REL_ BBM SG_ 2566749184 DPFC1_InhibDueSystemTimeout_ISig 24000;
BA_REL_ "GenSigTimeoutTime" BU_SG_REL_ BBM SG_ 2566749184 DPFC1_InhibDueSystemTimeout_ISig 6000;
BA_REL_ "GenSigFirstTimeoutTime" BU_SG_REL_ IC3 SG_ 2566749184 DPFC1_InhibDueSystemTimeout_ISig 24000;
BA_REL_ "GenSigTimeoutTime" BU_SG_REL_ IC3 SG_ 2566749184 DPFC1_InhibDueSystemTimeout_ISig 6000;
BA_REL_ "GenSigFirstTimeoutTime" BU_SG_REL_ VMCU SG_ 2566749184 DPFC1_InhibDueSystemTimeout_ISig 24000;
BA_REL_ "GenSigTimeoutTime" BU_SG_REL_ VMCU SG_ 2566749184 DPFC1_InhibDueSystemTimeout_ISig 6000;
BA_REL_ "GenSigFirstTimeoutTime" BU_SG_REL_ VMCU SG_ 2566749184 DPFC1_InhibAccPedalOffIdle_ISig_ 24000;
BA_REL_ "GenSigTimeoutTime" BU_SG_REL_ VMCU SG_ 2566749184 DPFC1_InhibAccPedalOffIdle_ISig_ 6000;
BA_REL_ "GenSigFirstTimeoutTime" BU_SG_REL_ IC3 SG_ 2566749184 DPFC1_InhibAccPedalOffIdle_ISig_ 24000;
BA_REL_ "GenSigTimeoutTime" BU_SG_REL_ IC3 SG_ 2566749184 DPFC1_InhibAccPedalOffIdle_ISig_ 6000;
BA_REL_ "GenSigFirstTimeoutTime" BU_SG_REL_ TECU SG_ 2566749184 DPFC1_InhibAccPedalOffIdle_ISig_ 24000;
BA_REL_ "GenSigTimeoutTime" BU_SG_REL_ TECU SG_ 2566749184 DPFC1_InhibAccPedalOffIdle_ISig_ 6000;
BA_REL_ "GenSigFirstTimeoutTime" BU_SG_REL_ BBM SG_ 2566749184 DPFC1_InhibAccPedalOffIdle_ISig_ 24000;
BA_REL_ "GenSigTimeoutTime" BU_SG_REL_ BBM SG_ 2566749184 DPFC1_InhibAccPedalOffIdle_ISig_ 6000;
BA_REL_ "GenSigFirstTimeoutTime" BU_SG_REL_ IC3 SG_ 2566834691 DiagnosticsFaultStat_DM1_TECU 24000;
BA_REL_ "GenSigTimeoutTime" BU_SG_REL_ IC3 SG_ 2566834691 DiagnosticsFaultStat_DM1_TECU 6000;
BA_REL_ "GenSigFirstTimeoutTime" BU_SG_REL_ IC3 SG_ 2566834926 DiagnosticsFaultStat_DM1_TACHO 24000;
BA_REL_ "GenSigTimeoutTime" BU_SG_REL_ IC3 SG_ 2566834926 DiagnosticsFaultStat_DM1_TACHO 6000;
BA_REL_ "GenSigFirstTimeoutTime" BU_SG_REL_ IC3 SG_ 2566834688 DiagnosticsFaultStat_DM1_EMS 24000;
BA_REL_ "GenSigTimeoutTime" BU_SG_REL_ IC3 SG_ 2566834688 DiagnosticsFaultStat_DM1_EMS 6000;
BA_REL_ "GenSigFirstTimeoutTime" BU_SG_REL_ IC3 SG_ 2566834749 DiagnosticsFaultStat_DM1_ACM 24000;
BA_REL_ "GenSigTimeoutTime" BU_SG_REL_ IC3 SG_ 2566834749 DiagnosticsFaultStat_DM1_ACM 6000;
BA_REL_ "GenSigFirstTimeoutTime" BU_SG_REL_ CIOM SG_ 2566810606 DriversIdentifications 65535;
BA_REL_ "GenSigTimeoutTime" BU_SG_REL_ CIOM SG_ 2566810606 DriversIdentifications 65535;
BA_REL_ "GenSigFirstTimeoutTime" BU_SG_REL_ DACU SG_ 2566723046 DriverDoorOpen_stat_ISig_3 3000;
BA_REL_ "GenSigTimeoutTime" BU_SG_REL_ DACU SG_ 2566723046 DriverDoorOpen_stat_ISig_3 600;
BA_REL_ "GenSigFirstTimeoutTime" BU_SG_REL_ DACU SG_ 2566723046 PassengerDoorOpen_stat_ISig_3 3000;
BA_REL_ "GenSigTimeoutTime" BU_SG_REL_ DACU SG_ 2566723046 PassengerDoorOpen_stat_ISig_3 600;
BA_REL_ "GenSigFirstTimeoutTime" BU_SG_REL_ VMCU SG_ 2499790765 ACC_SGO_Status_ISig_3 3000;
BA_REL_ "GenSigTimeoutTime" BU_SG_REL_ VMCU SG_ 2499790765 ACC_SGO_Status_ISig_3 600;
BA_REL_ "GenSigFirstTimeoutTime" BU_SG_REL_ EBS SG_ 2499790765 ACC_SGO_Status_ISig_3 3000;
BA_REL_ "GenSigTimeoutTime" BU_SG_REL_ EBS SG_ 2499790765 ACC_SGO_Status_ISig_3 600;
BA_REL_ "GenSigFirstTimeoutTime" BU_SG_REL_ IC3 SG_ 2499790765 ACC_SGO_Status_ISig_3 3000;
BA_REL_ "GenSigTimeoutTime" BU_SG_REL_ IC3 SG_ 2499790765 ACC_SGO_Status_ISig_3 600;
BA_REL_ "GenSigFirstTimeoutTime" BU_SG_REL_ TECU SG_ 2499790765 ACC_SGO_Status_ISig_3 3000;
BA_REL_ "GenSigTimeoutTime" BU_SG_REL_ TECU SG_ 2499790765 ACC_SGO_Status_ISig_3 600;
BA_REL_ "GenSigFirstTimeoutTime" BU_SG_REL_ EBS SG_ 2499790765 ACCHSARequest 3000;
BA_REL_ "GenSigTimeoutTime" BU_SG_REL_ EBS SG_ 2499790765 ACCHSARequest 600;
BA_REL_ "GenSigFirstTimeoutTime" BU_SG_REL_ DACU SG_ 2566811659 PoweredVehicleWeight_ISig_3 48000;
BA_REL_ "GenSigTimeoutTime" BU_SG_REL_ DACU SG_ 2566811659 PoweredVehicleWeight_ISig_3 12000;
BA_REL_ "GenSigFirstTimeoutTime" BU_SG_REL_ VMCU SG_ 2566811659 PoweredVehicleWeight_ISig_3 48000;
BA_REL_ "GenSigTimeoutTime" BU_SG_REL_ VMCU SG_ 2566811659 PoweredVehicleWeight_ISig_3 12000;
BA_REL_ "GenSigFirstTimeoutTime" BU_SG_REL_ IC3 SG_ 2566811659 GrossCombinationVehicleWeight_IS 48000;
BA_REL_ "GenSigTimeoutTime" BU_SG_REL_ IC3 SG_ 2566811659 GrossCombinationVehicleWeight_IS 12000;
BA_REL_ "GenSigFirstTimeoutTime" BU_SG_REL_ EMS SG_ 2566811659 GrossCombinationVehicleWeight_IS 48000;
BA_REL_ "GenSigTimeoutTime" BU_SG_REL_ EMS SG_ 2566811659 GrossCombinationVehicleWeight_IS 12000;
BA_REL_ "GenSigFirstTimeoutTime" BU_SG_REL_ VMCU SG_ 2566811659 GrossCombinationVehicleWeight_IS 48000;
BA_REL_ "GenSigTimeoutTime" BU_SG_REL_ VMCU SG_ 2566811659 GrossCombinationVehicleWeight_IS 12000;
BA_REL_ "GenSigFirstTimeoutTime" BU_SG_REL_ CIOM SG_ 2566811659 GrossCombinationVehicleWeight_IS 48000;
BA_REL_ "GenSigTimeoutTime" BU_SG_REL_ CIOM SG_ 2566811659 GrossCombinationVehicleWeight_IS 12000;
BA_REL_ "GenSigFirstTimeoutTime" BU_SG_REL_ TECU SG_ 2566811659 GrossCombinationVehicleWeight_IS 65000;
BA_REL_ "GenSigTimeoutTime" BU_SG_REL_ TECU SG_ 2566811659 GrossCombinationVehicleWeight_IS 12000;
BA_REL_ "GenSigFirstTimeoutTime" BU_SG_REL_ DACU SG_ 2566811659 GrossCombinationVehicleWeight_IS 48000;
BA_REL_ "GenSigTimeoutTime" BU_SG_REL_ DACU SG_ 2566811659 GrossCombinationVehicleWeight_IS 12000;
BA_REL_ "GenSigFirstTimeoutTime" BU_SG_REL_ VMCU SG_ 2563833623 BacklightLevelHighRes_ISig_3 24000;
BA_REL_ "GenSigTimeoutTime" BU_SG_REL_ VMCU SG_ 2563833623 BacklightLevelHighRes_ISig_3 6000;
BA_REL_ "GenSigFirstTimeoutTime" BU_SG_REL_ TACHO SG_ 2563833623 BacklightLevelHighRes_ISig_3 24000;
BA_REL_ "GenSigTimeoutTime" BU_SG_REL_ TACHO SG_ 2563833623 BacklightLevelHighRes_ISig_3 6000;
BA_REL_ "GenSigFirstTimeoutTime" BU_SG_REL_ BBM SG_ 2563833623 BacklightLevelHighRes_ISig_3 24000;
BA_REL_ "GenSigTimeoutTime" BU_SG_REL_ BBM SG_ 2563833623 BacklightLevelHighRes_ISig_3 6000;
BA_REL_ "GenSigFirstTimeoutTime" BU_SG_REL_ EBS SG_ 2499757105 ESCDriverReq 3000;
BA_REL_ "GenSigTimeoutTime" BU_SG_REL_ EBS SG_ 2499757105 ESCDriverReq 300;
BA_REL_ "GenSigFirstTimeoutTime" BU_SG_REL_ IC3 SG_ 2499757105 ESCDriverReq 3000;
BA_REL_ "GenSigTimeoutTime" BU_SG_REL_ IC3 SG_ 2499757105 ESCDriverReq 300;
BA_REL_ "GenSigFirstTimeoutTime" BU_SG_REL_ EBS SG_ 2499757105 RrItrWhl1DiffLockActvnDrvrReq_IS 3000;
BA_REL_ "GenSigTimeoutTime" BU_SG_REL_ EBS SG_ 2499757105 RrItrWhl1DiffLockActvnDrvrReq_IS 500;
BA_REL_ "GenSigFirstTimeoutTime" BU_SG_REL_ VMCU SG_ 2499757105 RrItrWhl1DiffLockActvnDrvrReq_IS 3000;
BA_REL_ "GenSigTimeoutTime" BU_SG_REL_ VMCU SG_ 2499757105 RrItrWhl1DiffLockActvnDrvrReq_IS 500;
BA_REL_ "GenSigFirstTimeoutTime" BU_SG_REL_ EBS SG_ 2499757105 RearAxleSteeringFunctionDsbl_ISi 3000;
BA_REL_ "GenSigTimeoutTime" BU_SG_REL_ EBS SG_ 2499757105 RearAxleSteeringFunctionDsbl_ISi 300;
BA_REL_ "GenSigFirstTimeoutTime" BU_SG_REL_ VMCU SG_ 2499757105 RearAxleSteeringFunctionDsbl_ISi 3000;
BA_REL_ "GenSigTimeoutTime" BU_SG_REL_ VMCU SG_ 2499757105 RearAxleSteeringFunctionDsbl_ISi 300;
BA_REL_ "GenSigFirstTimeoutTime" BU_SG_REL_ VMCU SG_ 2499757105 RearAxleDiffLockActvnDrvrReq_ISi 3000;
BA_REL_ "GenSigTimeoutTime" BU_SG_REL_ VMCU SG_ 2499757105 RearAxleDiffLockActvnDrvrReq_ISi 500;
BA_REL_ "GenSigFirstTimeoutTime" BU_SG_REL_ IC3 SG_ 2499757105 RearAxleDiffLockActvnDrvrReq_ISi 3000;
BA_REL_ "GenSigTimeoutTime" BU_SG_REL_ IC3 SG_ 2499757105 RearAxleDiffLockActvnDrvrReq_ISi 500;
BA_REL_ "GenSigFirstTimeoutTime" BU_SG_REL_ EBS SG_ 2499757105 RearAxleDiffLockActvnDrvrReq_ISi 3000;
BA_REL_ "GenSigTimeoutTime" BU_SG_REL_ EBS SG_ 2499757105 RearAxleDiffLockActvnDrvrReq_ISi 500;
BA_REL_ "GenSigFirstTimeoutTime" BU_SG_REL_ EBS SG_ 2499757105 RollerBenchModeRequest 3000;
BA_REL_ "GenSigTimeoutTime" BU_SG_REL_ EBS SG_ 2499757105 RollerBenchModeRequest 300;
BA_REL_ "GenSigFirstTimeoutTime" BU_SG_REL_ EBS SG_ 2499757105 ABSModeRequest 3000;
BA_REL_ "GenSigTimeoutTime" BU_SG_REL_ EBS SG_ 2499757105 ABSModeRequest 300;
BA_REL_ "GenSigFirstTimeoutTime" BU_SG_REL_ EBS SG_ 2499757105 RrInterAxlDiffLockActvnDrvrReq_I 3000;
BA_REL_ "GenSigTimeoutTime" BU_SG_REL_ EBS SG_ 2499757105 RrInterAxlDiffLockActvnDrvrReq_I 500;
BA_REL_ "GenSigFirstTimeoutTime" BU_SG_REL_ VMCU SG_ 2499757105 RrInterAxlDiffLockActvnDrvrReq_I 3000;
BA_REL_ "GenSigTimeoutTime" BU_SG_REL_ VMCU SG_ 2499757105 RrInterAxlDiffLockActvnDrvrReq_I 500;
BA_REL_ "GenSigFirstTimeoutTime" BU_SG_REL_ IC3 SG_ 2499757105 RrInterAxlDiffLockActvnDrvrReq_I 3000;
BA_REL_ "GenSigTimeoutTime" BU_SG_REL_ IC3 SG_ 2499757105 RrInterAxlDiffLockActvnDrvrReq_I 500;
BA_REL_ "GenSigFirstTimeoutTime" BU_SG_REL_ EBS SG_ 2499757105 HSADriverRequest 3000;
BA_REL_ "GenSigTimeoutTime" BU_SG_REL_ EBS SG_ 2499757105 HSADriverRequest 300;
BA_REL_ "GenSigFirstTimeoutTime" BU_SG_REL_ EBS SG_ 2499757105 AutRrAxleDiffLockActvnDrvrReq 3000;
BA_REL_ "GenSigTimeoutTime" BU_SG_REL_ EBS SG_ 2499757105 AutRrAxleDiffLockActvnDrvrReq 300;
BA_REL_ "GenSigFirstTimeoutTime" BU_SG_REL_ IC3 SG_ 2499757105 AutRrAxleDiffLockActvnDrvrReq 3000;
BA_REL_ "GenSigTimeoutTime" BU_SG_REL_ IC3 SG_ 2499757105 AutRrAxleDiffLockActvnDrvrReq 300;
BA_REL_ "GenSigFirstTimeoutTime" BU_SG_REL_ VMCU SG_ 2499757105 RrItrWhl2DiffLockActvnDrvrReq_IS 3000;
BA_REL_ "GenSigTimeoutTime" BU_SG_REL_ VMCU SG_ 2499757105 RrItrWhl2DiffLockActvnDrvrReq_IS 500;
BA_REL_ "GenSigFirstTimeoutTime" BU_SG_REL_ EBS SG_ 2499757105 RrItrWhl2DiffLockActvnDrvrReq_IS 3000;
BA_REL_ "GenSigTimeoutTime" BU_SG_REL_ EBS SG_ 2499757105 RrItrWhl2DiffLockActvnDrvrReq_IS 500;
BA_REL_ "GenSigFirstTimeoutTime" BU_SG_REL_ EBS SG_ 2499757105 ABSInhibitionRequest 3000;
BA_REL_ "GenSigTimeoutTime" BU_SG_REL_ EBS SG_ 2499757105 ABSInhibitionRequest 300;
BA_REL_ "GenSigFirstTimeoutTime" BU_SG_REL_ EBS SG_ 2499757105 TractionControlDriverRqst_ISig_3 3000;
BA_REL_ "GenSigTimeoutTime" BU_SG_REL_ EBS SG_ 2499757105 TractionControlDriverRqst_ISig_3 300;
BA_REL_ "GenSigFirstTimeoutTime" BU_SG_REL_ IC3 SG_ 2499757105 TractionControlDriverRqst_ISig_3 3000;
BA_REL_ "GenSigTimeoutTime" BU_SG_REL_ IC3 SG_ 2499757105 TractionControlDriverRqst_ISig_3 300;
BA_REL_ "GenSigFirstTimeoutTime" BU_SG_REL_ IC3 SG_ 2566844689 CCActive_ISig_3 3000;
BA_REL_ "GenSigTimeoutTime" BU_SG_REL_ IC3 SG_ 2566844689 CCActive_ISig_3 600;
BA_REL_ "GenSigFirstTimeoutTime" BU_SG_REL_ TECU SG_ 2566844689 CCActive_ISig_3 3000;
BA_REL_ "GenSigTimeoutTime" BU_SG_REL_ TECU SG_ 2566844689 CCActive_ISig_3 600;
BA_REL_ "GenSigFirstTimeoutTime" BU_SG_REL_ BBM SG_ 2566844689 CCActive_ISig_3 3000;
BA_REL_ "GenSigTimeoutTime" BU_SG_REL_ BBM SG_ 2566844689 CCActive_ISig_3 600;
BA_REL_ "GenSigFirstTimeoutTime" BU_SG_REL_ CIOM SG_ 2566844689 CCActive_ISig_3 3000;
BA_REL_ "GenSigTimeoutTime" BU_SG_REL_ CIOM SG_ 2566844689 CCActive_ISig_3 600;
BA_REL_ "GenSigFirstTimeoutTime" BU_SG_REL_ DACU SG_ 2566844689 CCActive_ISig_3 3000;
BA_REL_ "GenSigTimeoutTime" BU_SG_REL_ DACU SG_ 2566844689 CCActive_ISig_3 600;
BA_REL_ "GenSigFirstTimeoutTime" BU_SG_REL_ EMS SG_ 2566844689 BrakeSwitch_ISig_3 3000;
BA_REL_ "GenSigTimeoutTime" BU_SG_REL_ EMS SG_ 2566844689 BrakeSwitch_ISig_3 600;
BA_REL_ "GenSigFirstTimeoutTime" BU_SG_REL_ CIOM SG_ 2566844689 BrakeSwitch_ISig_3 3000;
BA_REL_ "GenSigTimeoutTime" BU_SG_REL_ CIOM SG_ 2566844689 BrakeSwitch_ISig_3 600;
BA_REL_ "GenSigFirstTimeoutTime" BU_SG_REL_ BBM SG_ 2566844689 BrakeSwitch_ISig_3 3000;
BA_REL_ "GenSigTimeoutTime" BU_SG_REL_ BBM SG_ 2566844689 BrakeSwitch_ISig_3 600;
BA_REL_ "GenSigFirstTimeoutTime" BU_SG_REL_ IC3 SG_ 2566844689 BrakeSwitch_ISig_3 3000;
BA_REL_ "GenSigTimeoutTime" BU_SG_REL_ IC3 SG_ 2566844689 BrakeSwitch_ISig_3 600;
BA_REL_ "GenSigFirstTimeoutTime" BU_SG_REL_ DACU SG_ 2566844689 BrakeSwitch_ISig_3 3000;
BA_REL_ "GenSigTimeoutTime" BU_SG_REL_ DACU SG_ 2566844689 BrakeSwitch_ISig_3 600;
BA_REL_ "GenSigFirstTimeoutTime" BU_SG_REL_ TECU SG_ 2566844689 BrakeSwitch_ISig_3 3000;
BA_REL_ "GenSigTimeoutTime" BU_SG_REL_ TECU SG_ 2566844689 BrakeSwitch_ISig_3 600;
BA_REL_ "GenSigFirstTimeoutTime" BU_SG_REL_ TECU SG_ 2566844689 CruiseControlStates 3000;
BA_REL_ "GenSigTimeoutTime" BU_SG_REL_ TECU SG_ 2566844689 CruiseControlStates 600;
BA_REL_ "GenSigFirstTimeoutTime" BU_SG_REL_ EMS SG_ 2566844689 WheelBasedVehicleSpeed_ISig_3 3000;
BA_REL_ "GenSigTimeoutTime" BU_SG_REL_ EMS SG_ 2566844689 WheelBasedVehicleSpeed_ISig_3 600;
BA_REL_ "GenSigFirstTimeoutTime" BU_SG_REL_ BBM SG_ 2566844689 WheelBasedVehicleSpeed_ISig_3 3000;
BA_REL_ "GenSigTimeoutTime" BU_SG_REL_ BBM SG_ 2566844689 WheelBasedVehicleSpeed_ISig_3 600;
BA_REL_ "GenSigFirstTimeoutTime" BU_SG_REL_ TECU SG_ 2566844689 WheelBasedVehicleSpeed_ISig_3 3000;
BA_REL_ "GenSigTimeoutTime" BU_SG_REL_ TECU SG_ 2566844689 WheelBasedVehicleSpeed_ISig_3 600;
BA_REL_ "GenSigFirstTimeoutTime" BU_SG_REL_ IC3 SG_ 2566844689 WheelBasedVehicleSpeed_ISig_3 3000;
BA_REL_ "GenSigTimeoutTime" BU_SG_REL_ IC3 SG_ 2566844689 WheelBasedVehicleSpeed_ISig_3 600;
BA_REL_ "GenSigFirstTimeoutTime" BU_SG_REL_ DACU SG_ 2566844689 WheelBasedVehicleSpeed_ISig_3 3000;
BA_REL_ "GenSigTimeoutTime" BU_SG_REL_ DACU SG_ 2566844689 WheelBasedVehicleSpeed_ISig_3 600;
BA_REL_ "GenSigFirstTimeoutTime" BU_SG_REL_ EBS SG_ 2566844689 WheelBasedVehicleSpeed_ISig_3 3000;
BA_REL_ "GenSigTimeoutTime" BU_SG_REL_ EBS SG_ 2566844689 WheelBasedVehicleSpeed_ISig_3 600;
BA_REL_ "GenSigFirstTimeoutTime" BU_SG_REL_ ACM SG_ 2566844689 WheelBasedVehicleSpeed_ISig_3 3000;
BA_REL_ "GenSigTimeoutTime" BU_SG_REL_ ACM SG_ 2566844689 WheelBasedVehicleSpeed_ISig_3 600;
BA_REL_ "GenSigFirstTimeoutTime" BU_SG_REL_ CIOM SG_ 2566844689 WheelBasedVehicleSpeed_ISig_3 3000;
BA_REL_ "GenSigTimeoutTime" BU_SG_REL_ CIOM SG_ 2566844689 WheelBasedVehicleSpeed_ISig_3 600;
BA_REL_ "GenSigFirstTimeoutTime" BU_SG_REL_ EMS SG_ 2566844689 ClutchSwitch_ISig_3 3000;
BA_REL_ "GenSigTimeoutTime" BU_SG_REL_ EMS SG_ 2566844689 ClutchSwitch_ISig_3 600;
BA_REL_ "GenSigFirstTimeoutTime" BU_SG_REL_ CIOM SG_ 2566844689 ClutchSwitch_ISig_3 3000;
BA_REL_ "GenSigTimeoutTime" BU_SG_REL_ CIOM SG_ 2566844689 ClutchSwitch_ISig_3 600;
BA_REL_ "GenSigFirstTimeoutTime" BU_SG_REL_ BBM SG_ 2566844689 ClutchSwitch_ISig_3 3000;
BA_REL_ "GenSigTimeoutTime" BU_SG_REL_ BBM SG_ 2566844689 ClutchSwitch_ISig_3 600;
BA_REL_ "GenSigFirstTimeoutTime" BU_SG_REL_ EBS SG_ 2566844689 ClutchSwitch_ISig_3 3000;
BA_REL_ "GenSigTimeoutTime" BU_SG_REL_ EBS SG_ 2566844689 ClutchSwitch_ISig_3 600;
BA_REL_ "GenSigFirstTimeoutTime" BU_SG_REL_ IC3 SG_ 2566844689 ClutchSwitch_ISig_3 3000;
BA_REL_ "GenSigTimeoutTime" BU_SG_REL_ IC3 SG_ 2566844689 ClutchSwitch_ISig_3 600;
BA_REL_ "GenSigFirstTimeoutTime" BU_SG_REL_ VMCU SG_ 2499779302 BBAirDumpRequest_ISig_3 3000;
BA_REL_ "GenSigTimeoutTime" BU_SG_REL_ VMCU SG_ 2499779302 BBAirDumpRequest_ISig_3 600;
BA_REL_ "GenSigFirstTimeoutTime" BU_SG_REL_ EBS SG_ 2499779302 CtaBs_HSABbRequest_ISig_3 3000;
BA_REL_ "GenSigTimeoutTime" BU_SG_REL_ EBS SG_ 2499779302 CtaBs_HSABbRequest_ISig_3 600;
BA_REL_ "GenSigFirstTimeoutTime" BU_SG_REL_ IC3 SG_ 2566748928 DPFSootLevel 24000;
BA_REL_ "GenSigTimeoutTime" BU_SG_REL_ IC3 SG_ 2566748928 DPFSootLevel 6000;
BA_REL_ "GenSigFirstTimeoutTime" BU_SG_REL_ CIOM SG_ 2565869312 Aftertreat1NOxConcOutlet 12000;
BA_REL_ "GenSigTimeoutTime" BU_SG_REL_ CIOM SG_ 2565869312 Aftertreat1NOxConcOutlet 3000;
BA_REL_ "GenSigFirstTimeoutTime" BU_SG_REL_ CIOM SG_ 2566763008 DPFPressureDiff 12000;
BA_REL_ "GenSigTimeoutTime" BU_SG_REL_ CIOM SG_ 2566763008 DPFPressureDiff 3000;
BA_REL_ "GenSigFirstTimeoutTime" BU_SG_REL_ CIOM SG_ 2566763520 Aftertreatment1ExhaustTemp1 12000;
BA_REL_ "GenSigTimeoutTime" BU_SG_REL_ CIOM SG_ 2566763520 Aftertreatment1ExhaustTemp1 3000;
BA_REL_ "GenSigFirstTimeoutTime" BU_SG_REL_ CIOM SG_ 2565869056 EngineExhaust1NOx1 12000;
BA_REL_ "GenSigTimeoutTime" BU_SG_REL_ CIOM SG_ 2565869056 EngineExhaust1NOx1 3000;
BA_REL_ "GenSigFirstTimeoutTime" BU_SG_REL_ CIOM SG_ 2566845713 AmbientAirTemperature_ISig_3 24000;
BA_REL_ "GenSigTimeoutTime" BU_SG_REL_ CIOM SG_ 2566845713 AmbientAirTemperature_ISig_3 6000;
BA_REL_ "GenSigFirstTimeoutTime" BU_SG_REL_ IC3 SG_ 2566845713 AmbientAirTemperature_ISig_3 24000;
BA_REL_ "GenSigTimeoutTime" BU_SG_REL_ IC3 SG_ 2566845713 AmbientAirTemperature_ISig_3 6000;
BA_REL_ "GenSigFirstTimeoutTime" BU_SG_REL_ BBM SG_ 2566845713 AmbientAirTemperature_ISig_3 24000;
BA_REL_ "GenSigTimeoutTime" BU_SG_REL_ BBM SG_ 2566845713 AmbientAirTemperature_ISig_3 6000;
BA_REL_ "GenSigFirstTimeoutTime" BU_SG_REL_ EBS SG_ 2566845713 AmbientAirTemperature_ISig_3 24000;
BA_REL_ "GenSigTimeoutTime" BU_SG_REL_ EBS SG_ 2566845713 AmbientAirTemperature_ISig_3 6000;
BA_REL_ "GenSigFirstTimeoutTime" BU_SG_REL_ TECU SG_ 2566845713 AmbientAirTemperature_ISig_3 24000;
BA_REL_ "GenSigTimeoutTime" BU_SG_REL_ TECU SG_ 2566845713 AmbientAirTemperature_ISig_3 6000;
BA_REL_ "GenSigFirstTimeoutTime" BU_SG_REL_ DACU SG_ 2566845713 AmbientAirTemperature_ISig_3 24000;
BA_REL_ "GenSigTimeoutTime" BU_SG_REL_ DACU SG_ 2566845713 AmbientAirTemperature_ISig_3 6000;
BA_REL_ "GenSigFirstTimeoutTime" BU_SG_REL_ EMS SG_ 2566845713 AmbientAirTemperature_ISig_3 24000;
BA_REL_ "GenSigTimeoutTime" BU_SG_REL_ EMS SG_ 2566845713 AmbientAirTemperature_ISig_3 6000;
BA_REL_ "GenSigFirstTimeoutTime" BU_SG_REL_ ACM SG_ 2566845713 AmbientAirTemperature_ISig_3 24000;
BA_REL_ "GenSigTimeoutTime" BU_SG_REL_ ACM SG_ 2566845713 AmbientAirTemperature_ISig_3 6000;
BA_REL_ "GenSigFirstTimeoutTime" BU_SG_REL_ EBS SG_ 2566827537 ParkingAndTrailerAirPressure_ISi 24000;
BA_REL_ "GenSigTimeoutTime" BU_SG_REL_ EBS SG_ 2566827537 ParkingAndTrailerAirPressure_ISi 6000;
BA_REL_ "GenSigFirstTimeoutTime" BU_SG_REL_ BBM SG_ 2566827537 ParkingAndTrailerAirPressure_ISi 24000;
BA_REL_ "GenSigTimeoutTime" BU_SG_REL_ BBM SG_ 2566827537 ParkingAndTrailerAirPressure_ISi 6000;
BA_REL_ "GenSigFirstTimeoutTime" BU_SG_REL_ ACM SG_ 2566827537 ServiceBrakeAirPrsCircuit2_ISig_ 24000;
BA_REL_ "GenSigTimeoutTime" BU_SG_REL_ ACM SG_ 2566827537 ServiceBrakeAirPrsCircuit2_ISig_ 6000;
BA_REL_ "GenSigFirstTimeoutTime" BU_SG_REL_ TECU SG_ 2566827537 ServiceBrakeAirPrsCircuit2_ISig_ 24000;
BA_REL_ "GenSigTimeoutTime" BU_SG_REL_ TECU SG_ 2566827537 ServiceBrakeAirPrsCircuit2_ISig_ 6000;
BA_REL_ "GenSigFirstTimeoutTime" BU_SG_REL_ EMS SG_ 2566827537 ServiceBrakeAirPrsCircuit2_ISig_ 24000;
BA_REL_ "GenSigTimeoutTime" BU_SG_REL_ EMS SG_ 2566827537 ServiceBrakeAirPrsCircuit2_ISig_ 6000;
BA_REL_ "GenSigFirstTimeoutTime" BU_SG_REL_ IC3 SG_ 2566827537 ServiceBrakeAirPrsCircuit2_ISig_ 24000;
BA_REL_ "GenSigTimeoutTime" BU_SG_REL_ IC3 SG_ 2566827537 ServiceBrakeAirPrsCircuit2_ISig_ 6000;
BA_REL_ "GenSigFirstTimeoutTime" BU_SG_REL_ EBS SG_ 2566827537 ServiceBrakeAirPrsCircuit2_ISig_ 24000;
BA_REL_ "GenSigTimeoutTime" BU_SG_REL_ EBS SG_ 2566827537 ServiceBrakeAirPrsCircuit2_ISig_ 6000;
BA_REL_ "GenSigFirstTimeoutTime" BU_SG_REL_ BBM SG_ 2566827537 ServiceBrakeAirPrsCircuit2_ISig_ 24000;
BA_REL_ "GenSigTimeoutTime" BU_SG_REL_ BBM SG_ 2566827537 ServiceBrakeAirPrsCircuit2_ISig_ 6000;
BA_REL_ "GenSigFirstTimeoutTime" BU_SG_REL_ CIOM SG_ 2566827537 ServiceBrakeAirPrsCircuit2_ISig_ 24000;
BA_REL_ "GenSigTimeoutTime" BU_SG_REL_ CIOM SG_ 2566827537 ServiceBrakeAirPrsCircuit2_ISig_ 6000;
BA_REL_ "GenSigFirstTimeoutTime" BU_SG_REL_ IC3 SG_ 2566827537 ServiceBrakeAirPrsCircuit1_ISig_ 24000;
BA_REL_ "GenSigTimeoutTime" BU_SG_REL_ IC3 SG_ 2566827537 ServiceBrakeAirPrsCircuit1_ISig_ 6000;
BA_REL_ "GenSigFirstTimeoutTime" BU_SG_REL_ ACM SG_ 2566827537 ServiceBrakeAirPrsCircuit1_ISig_ 24000;
BA_REL_ "GenSigTimeoutTime" BU_SG_REL_ ACM SG_ 2566827537 ServiceBrakeAirPrsCircuit1_ISig_ 6000;
BA_REL_ "GenSigFirstTimeoutTime" BU_SG_REL_ BBM SG_ 2566827537 ServiceBrakeAirPrsCircuit1_ISig_ 24000;
BA_REL_ "GenSigTimeoutTime" BU_SG_REL_ BBM SG_ 2566827537 ServiceBrakeAirPrsCircuit1_ISig_ 6000;
BA_REL_ "GenSigFirstTimeoutTime" BU_SG_REL_ TECU SG_ 2566827537 ServiceBrakeAirPrsCircuit1_ISig_ 24000;
BA_REL_ "GenSigTimeoutTime" BU_SG_REL_ TECU SG_ 2566827537 ServiceBrakeAirPrsCircuit1_ISig_ 6000;
BA_REL_ "GenSigFirstTimeoutTime" BU_SG_REL_ EBS SG_ 2566827537 ServiceBrakeAirPrsCircuit1_ISig_ 24000;
BA_REL_ "GenSigTimeoutTime" BU_SG_REL_ EBS SG_ 2566827537 ServiceBrakeAirPrsCircuit1_ISig_ 6000;
BA_REL_ "GenSigFirstTimeoutTime" BU_SG_REL_ CIOM SG_ 2566827537 ServiceBrakeAirPrsCircuit1_ISig_ 24000;
BA_REL_ "GenSigTimeoutTime" BU_SG_REL_ CIOM SG_ 2566827537 ServiceBrakeAirPrsCircuit1_ISig_ 6000;
BA_REL_ "GenSigFirstTimeoutTime" BU_SG_REL_ EMS SG_ 2566827537 ServiceBrakeAirPrsCircuit1_ISig_ 24000;
BA_REL_ "GenSigTimeoutTime" BU_SG_REL_ EMS SG_ 2566827537 ServiceBrakeAirPrsCircuit1_ISig_ 6000;
BA_REL_ "GenSigFirstTimeoutTime" BU_SG_REL_ IC3 SG_ 2566892605 LNGTimeToVent_ISig_3 24000;
BA_REL_ "GenSigTimeoutTime" BU_SG_REL_ IC3 SG_ 2566892605 LNGTimeToVent_ISig_3 6000;
BA_REL_ "GenSigFirstTimeoutTime" BU_SG_REL_ IC3 SG_ 2566892605 LNGRestrictionStatus_Spare1_ISig 24000;
BA_REL_ "GenSigTimeoutTime" BU_SG_REL_ IC3 SG_ 2566892605 LNGRestrictionStatus_Spare1_ISig 6000;
BA_REL_ "GenSigFirstTimeoutTime" BU_SG_REL_ IC3 SG_ 2566892605 LNGRestrictionStatus_Spare3_ISig 24000;
BA_REL_ "GenSigTimeoutTime" BU_SG_REL_ IC3 SG_ 2566892605 LNGRestrictionStatus_Spare3_ISig 6000;
BA_REL_ "GenSigFirstTimeoutTime" BU_SG_REL_ IC3 SG_ 2566892605 LNGRestrictionStatus_V2Closed_IS 24000;
BA_REL_ "GenSigTimeoutTime" BU_SG_REL_ IC3 SG_ 2566892605 LNGRestrictionStatus_V2Closed_IS 6000;
BA_REL_ "GenSigFirstTimeoutTime" BU_SG_REL_ IC3 SG_ 2566892605 LNGRestrictionStatus_Spare4_ISig 24000;
BA_REL_ "GenSigTimeoutTime" BU_SG_REL_ IC3 SG_ 2566892605 LNGRestrictionStatus_Spare4_ISig 6000;
BA_REL_ "GenSigFirstTimeoutTime" BU_SG_REL_ IC3 SG_ 2566892605 LNGRestrictionStatus_V1Closed_IS 24000;
BA_REL_ "GenSigTimeoutTime" BU_SG_REL_ IC3 SG_ 2566892605 LNGRestrictionStatus_V1Closed_IS 6000;
BA_REL_ "GenSigFirstTimeoutTime" BU_SG_REL_ IC3 SG_ 2566892605 ACM_Available_Log_ISig_3 24000;
BA_REL_ "GenSigTimeoutTime" BU_SG_REL_ IC3 SG_ 2566892605 ACM_Available_Log_ISig_3 6000;
BA_REL_ "GenSigFirstTimeoutTime" BU_SG_REL_ IC3 SG_ 2566892605 LNGRestrictionStatus_Spare2_ISig 24000;
BA_REL_ "GenSigTimeoutTime" BU_SG_REL_ IC3 SG_ 2566892605 LNGRestrictionStatus_Spare2_ISig 6000;
BA_REL_ "GenSigFirstTimeoutTime" BU_SG_REL_ IC3 SG_ 2566892605 LNGRestrictionStatus_SInfo_ISig_ 24000;
BA_REL_ "GenSigTimeoutTime" BU_SG_REL_ IC3 SG_ 2566892605 LNGRestrictionStatus_SInfo_ISig_ 6000;
BA_REL_ "GenSigFirstTimeoutTime" BU_SG_REL_ VMCU SG_ 2566892093 AdBlueTankTemperature_ISig_3 24000;
BA_REL_ "GenSigTimeoutTime" BU_SG_REL_ VMCU SG_ 2566892093 AdBlueTankTemperature_ISig_3 6000;
BA_REL_ "GenSigFirstTimeoutTime" BU_SG_REL_ IC3 SG_ 2566892093 AdBlueTankTemperature_ISig_3 24000;
BA_REL_ "GenSigTimeoutTime" BU_SG_REL_ IC3 SG_ 2566892093 AdBlueTankTemperature_ISig_3 6000;
BA_REL_ "GenSigFirstTimeoutTime" BU_SG_REL_ BBM SG_ 2566892093 AdBlueTankTemperature_ISig_3 24000;
BA_REL_ "GenSigTimeoutTime" BU_SG_REL_ BBM SG_ 2566892093 AdBlueTankTemperature_ISig_3 6000;
BA_REL_ "GenSigFirstTimeoutTime" BU_SG_REL_ IC3 SG_ 2566892093 LngTank2RemainingGasVolume_ISig_ 24000;
BA_REL_ "GenSigTimeoutTime" BU_SG_REL_ IC3 SG_ 2566892093 LngTank2RemainingGasVolume_ISig_ 6000;
BA_REL_ "GenSigFirstTimeoutTime" BU_SG_REL_ VMCU SG_ 2566892093 LngTank2RemainingGasVolume_ISig_ 24000;
BA_REL_ "GenSigTimeoutTime" BU_SG_REL_ VMCU SG_ 2566892093 LngTank2RemainingGasVolume_ISig_ 6000;
BA_REL_ "GenSigFirstTimeoutTime" BU_SG_REL_ CIOM SG_ 2566892093 LngTank2RemainingGasVolume_ISig_ 24000;
BA_REL_ "GenSigTimeoutTime" BU_SG_REL_ CIOM SG_ 2566892093 LngTank2RemainingGasVolume_ISig_ 6000;
BA_REL_ "GenSigFirstTimeoutTime" BU_SG_REL_ IC3 SG_ 2566892093 LngSystemReadinessStat_ISig_3 24000;
BA_REL_ "GenSigTimeoutTime" BU_SG_REL_ IC3 SG_ 2566892093 LngSystemReadinessStat_ISig_3 6000;
BA_REL_ "GenSigFirstTimeoutTime" BU_SG_REL_ BBM SG_ 2566892093 CatalystTankLevel_ISig_3 24000;
BA_REL_ "GenSigTimeoutTime" BU_SG_REL_ BBM SG_ 2566892093 CatalystTankLevel_ISig_3 6000;
BA_REL_ "GenSigFirstTimeoutTime" BU_SG_REL_ EMS SG_ 2566892093 CatalystTankLevel_ISig_3 24000;
BA_REL_ "GenSigTimeoutTime" BU_SG_REL_ EMS SG_ 2566892093 CatalystTankLevel_ISig_3 6000;
BA_REL_ "GenSigFirstTimeoutTime" BU_SG_REL_ CIOM SG_ 2566892093 CatalystTankLevel_ISig_3 24000;
BA_REL_ "GenSigTimeoutTime" BU_SG_REL_ CIOM SG_ 2566892093 CatalystTankLevel_ISig_3 6000;
BA_REL_ "GenSigFirstTimeoutTime" BU_SG_REL_ IC3 SG_ 2566892093 CatalystTankLevel_ISig_3 24000;
BA_REL_ "GenSigTimeoutTime" BU_SG_REL_ IC3 SG_ 2566892093 CatalystTankLevel_ISig_3 6000;
BA_REL_ "GenSigFirstTimeoutTime" BU_SG_REL_ EMS SG_ 2566892093 MIStatusExtACM 24000;
BA_REL_ "GenSigTimeoutTime" BU_SG_REL_ EMS SG_ 2566892093 MIStatusExtACM 6000;
BA_REL_ "GenSigFirstTimeoutTime" BU_SG_REL_ VMCU SG_ 2566892093 CatalystTankLevelLow_ISig_3 24000;
BA_REL_ "GenSigTimeoutTime" BU_SG_REL_ VMCU SG_ 2566892093 CatalystTankLevelLow_ISig_3 6000;
BA_REL_ "GenSigFirstTimeoutTime" BU_SG_REL_ IC3 SG_ 2566892093 CatalystTankLevelLow_ISig_3 24000;
BA_REL_ "GenSigTimeoutTime" BU_SG_REL_ IC3 SG_ 2566892093 CatalystTankLevelLow_ISig_3 6000;
BA_REL_ "GenSigFirstTimeoutTime" BU_SG_REL_ EMS SG_ 2566892093 CatalystTankLevelLow_ISig_3 24000;
BA_REL_ "GenSigTimeoutTime" BU_SG_REL_ EMS SG_ 2566892093 CatalystTankLevelLow_ISig_3 6000;
BA_REL_ "GenSigFirstTimeoutTime" BU_SG_REL_ IC3 SG_ 2566892093 LngGspWarnStat 24000;
BA_REL_ "GenSigTimeoutTime" BU_SG_REL_ IC3 SG_ 2566892093 LngGspWarnStat 6000;
BA_REL_ "GenSigFirstTimeoutTime" BU_SG_REL_ IC3 SG_ 2566892093 LngTank2WarnStat 24000;
BA_REL_ "GenSigTimeoutTime" BU_SG_REL_ IC3 SG_ 2566892093 LngTank2WarnStat 6000;
BA_REL_ "GenSigFirstTimeoutTime" BU_SG_REL_ EMS SG_ 2566892093 MIDistinctWarningExtACM 24000;
BA_REL_ "GenSigTimeoutTime" BU_SG_REL_ EMS SG_ 2566892093 MIDistinctWarningExtACM 6000;
BA_REL_ "GenSigFirstTimeoutTime" BU_SG_REL_ IC3 SG_ 2566892093 LngTank1RemainingGasVolume_ISig_ 24000;
BA_REL_ "GenSigTimeoutTime" BU_SG_REL_ IC3 SG_ 2566892093 LngTank1RemainingGasVolume_ISig_ 6000;
BA_REL_ "GenSigFirstTimeoutTime" BU_SG_REL_ VMCU SG_ 2566892093 LngTank1RemainingGasVolume_ISig_ 24000;
BA_REL_ "GenSigTimeoutTime" BU_SG_REL_ VMCU SG_ 2566892093 LngTank1RemainingGasVolume_ISig_ 6000;
BA_REL_ "GenSigFirstTimeoutTime" BU_SG_REL_ CIOM SG_ 2566892093 LngTank1RemainingGasVolume_ISig_ 24000;
BA_REL_ "GenSigTimeoutTime" BU_SG_REL_ CIOM SG_ 2566892093 LngTank1RemainingGasVolume_ISig_ 6000;
BA_REL_ "GenSigFirstTimeoutTime" BU_SG_REL_ IC3 SG_ 2566892093 LngTank1WarnStat 24000;
BA_REL_ "GenSigTimeoutTime" BU_SG_REL_ IC3 SG_ 2566892093 LngTank1WarnStat 6000;
BA_REL_ "GenSigFirstTimeoutTime" BU_SG_REL_ IC3 SG_ 2566892093 LNGLevel_ISig_3 24000;
BA_REL_ "GenSigTimeoutTime" BU_SG_REL_ IC3 SG_ 2566892093 LNGLevel_ISig_3 6000;
BA_REL_ "GenSigFirstTimeoutTime" BU_SG_REL_ CIOM SG_ 2499624448 SCRInletTemp 12000;
BA_REL_ "GenSigTimeoutTime" BU_SG_REL_ CIOM SG_ 2499624448 SCRInletTemp 3000;
BA_REL_ "GenSigFirstTimeoutTime" BU_SG_REL_ CIOM SG_ 2499624448 SCROutletTemp 12000;
BA_REL_ "GenSigTimeoutTime" BU_SG_REL_ CIOM SG_ 2499624448 SCROutletTemp 3000;
VAL_ 2565865739 ASRHillHolderSwitch_ISig_3 3 "PassiveActive_NotAvailable" 2 "PassiveActive_Error" 1 "PassiveActive_Active" 0 "PassiveActive_Passive" ;
VAL_ 2565865739 ABSFullyOperational_ISig_3 3 "FullyOperational_NotAvailable" 2 "FullyOperational_Reserved" 1 "FullyOperational_FullyOperational" 0 "FullyOperational_NotFullyOperational" ;
VAL_ 2565865739 EBSRedWarningSignal_ISig_3 3 "OffOn_NotAvailable" 2 "OffOn_Error" 1 "OffOn_On" 0 "OffOn_Off" ;
VAL_ 2565865739 ASREngineControlActive_ISig_3 3 "PassiveActive2_DontCareTakeNoAction" 2 "PassiveActive2_Reserved" 1 "PassiveActive2_Active" 0 "PassiveActive2_PassiveButInstalled" ;
VAL_ 2565865739 ASRBrakeControlActive_ISig_3 3 "PassiveActive2_DontCareTakeNoAction" 2 "PassiveActive2_Reserved" 1 "PassiveActive2_Active" 0 "PassiveActive2_PassiveButInstalled" ;
VAL_ 2565865739 ABSEBSAmberWarningSignal_ISig_3 3 "OffOn_NotAvailable" 2 "OffOn_Error" 1 "OffOn_On" 0 "OffOn_Off" ;
VAL_ 2565865739 AntiLockBrakingActive_ISig_3 3 "AntiLockBrakingActive_NotAvailable" 2 "AntiLockBrakingActive_Reserved" 1 "AntiLockBrakingActive_ABSActive" 0 "AntiLockBrakingActive_ABSPassiveButInstalled" ;
VAL_ 2566749184 DPFC1_ActiveRegeneratStatus_ISig 3 "ActiveRegeneratStatus_NotAvailable" 2 "ActiveRegeneratStatus_RegenNeededAutoInitiatedActReg" 1 "ActiveRegeneratStatus_Active" 0 "ActiveRegeneratStatus_NotActive" ;
VAL_ 2566749184 DPFC1_LampCommand_ISig_3 7 "LampCommand_NotAvailable" 6 "LampCommand_Reserved_03" 5 "LampCommand_Reserved_02" 4 "LampCommand_OnFastBlink1Hz" 3 "LampCommand_Reserved_01" 2 "LampCommand_Reserved" 1 "LampCommand_OnSolid" 0 "LampCommand_Off" ;
VAL_ 2566749184 DPFC1_InhibTempSystemLock_ISig_3 3 "InhibitStatus_NotAvailable" 2 "InhibitStatus_Reserved" 1 "InhibitStatus_Inhibited" 0 "InhibitStatus_NotInhibited" ;
VAL_ 2566749184 DPFC1_InhibOutOfNeutral_ISig_3 3 "InhibitStatus_NotAvailable" 2 "InhibitStatus_Reserved" 1 "InhibitStatus_Inhibited" 0 "InhibitStatus_NotInhibited" ;
VAL_ 2566749184 DPFC1_InhibEnginNotWarmUp_ISig_3 3 "InhibitStatus_NotAvailable" 2 "InhibitStatus_Reserved" 1 "InhibitStatus_Inhibited" 0 "InhibitStatus_NotInhibited" ;
VAL_ 2566749184 DPFC1_InhibDueInhibSwitch_ISig_3 3 "InhibitStatus_NotAvailable" 2 "InhibitStatus_Reserved" 1 "InhibitStatus_Inhibited" 0 "InhibitStatus_NotInhibited" ;
VAL_ 2566749184 DPFC1_InhibClutchDisengage_ISig_ 3 "InhibitStatus_NotAvailable" 2 "InhibitStatus_Reserved" 1 "InhibitStatus_Inhibited" 0 "InhibitStatus_NotInhibited" ;
VAL_ 2566749184 DPFC1_InhibVehSpdAboveAllwdSpd_I 3 "InhibitStatus_NotAvailable" 2 "InhibitStatus_Reserved" 1 "InhibitStatus_Inhibited" 0 "InhibitStatus_NotInhibited" ;
VAL_ 2566749184 DPFC1_ForcedStatus_ISig_3 7 "ForcedStatus_NotAvailable" 6 "ForcedStatus_Reserved_03" 5 "ForcedStatus_Reserved_02" 4 "ForcedStatus_Reserved_01" 3 "ForcedStatus_Reserved" 2 "ForcedStatus_ActiveForcedByServiceTool" 1 "ForcedStatus_ActiveForcedBySwitch" 0 "ForcedStatus_NotActive" ;
VAL_ 2566749184 DPFC1_InhibPTOActive_ISig_3 3 "InhibitStatus_NotAvailable" 2 "InhibitStatus_Reserved" 1 "InhibitStatus_Inhibited" 0 "InhibitStatus_NotInhibited" ;
VAL_ 2566749184 DPFC1_InhibVehSpdBelowAllwdSpd_I 3 "InhibitStatus_NotAvailable" 2 "InhibitStatus_Reserved" 1 "InhibitStatus_Inhibited" 0 "InhibitStatus_NotInhibited" ;
VAL_ 2566749184 DPFC1_InhibSystemFaultAct_ISig_3 3 "InhibitStatus_NotAvailable" 2 "InhibitStatus_Reserved" 1 "InhibitStatus_Inhibited" 0 "InhibitStatus_NotInhibited" ;
VAL_ 2566749184 DPFC1_PassiveRegenStatus_ISig_3 3 "InactiveActive_NotAvailable" 2 "InactiveActive_Error" 1 "InactiveActive_Active" 0 "InactiveActive_Inactive" ;
VAL_ 2566749184 DPFC1_InhibPermSystemLock_ISig_3 3 "InhibitStatus_NotAvailable" 2 "InhibitStatus_Reserved" 1 "InhibitStatus_Inhibited" 0 "InhibitStatus_NotInhibited" ;
VAL_ 2566749184 DPFC1_AutoARInitConfig_ISig_3 3 "AutoARInitConfig_NotAvailable" 2 "AutoARInitConfig_Reserved" 1 "AutoARInitConfig_Enabled" 0 "AutoARInitConfig_NotEnabled" ;
VAL_ 2566749184 DPFC1_InhibDueLowExhGasTemp_ISig 3 "InhibitStatus_NotAvailable" 2 "InhibitStatus_Reserved" 1 "InhibitStatus_Inhibited" 0 "InhibitStatus_NotInhibited" ;
VAL_ 2566749184 DPFC1_ExhaustSystHighTempLampCmd 7 "ExhaustSystHighTempLampCmd_NotAvailable" 6 "ExhaustSystHighTempLampCmd_Reserved_04" 5 "ExhaustSystHighTempLampCmd_Reserved_03" 4 "ExhaustSystHighTempLampCmd_Reserved_02" 3 "ExhaustSystHighTempLampCmd_Reserved_01" 2 "ExhaustSystHighTempLampCmd_Reserved" 1 "ExhaustSystHighTempLampCmd_On" 0 "ExhaustSystHighTempLampCmd_Off" ;
VAL_ 2566749184 DPFC1_InhibitStatus_ISig_3 3 "InhibitStatus_NotAvailable" 2 "InhibitStatus_Reserved" 1 "InhibitStatus_Inhibited" 0 "InhibitStatus_NotInhibited" ;
VAL_ 2566749184 DPFC1_DPFStatus_ISig_3 7 "DPFStatus_NotAvailable" 6 "DPFStatus_Reserved_02" 5 "DPFStatus_Reserved_01" 4 "DPFStatus_Reserved" 3 "DPFStatus_RegenerationNeededHighestLevel" 2 "DPFStatus_RegenerationNeededModerateLevel" 1 "DPFStatus_RegenerationNeededLowestLevel" 0 "DPFStatus_RegenerationNotNeeded" ;
VAL_ 2566749184 DPFC1_InhibParkBrakeNotSet_ISig_ 3 "InhibitStatus_NotAvailable" 2 "InhibitStatus_Reserved" 1 "InhibitStatus_Inhibited" 0 "InhibitStatus_NotInhibited" ;
VAL_ 2566749184 DPFC1_InhibDueServiceBrake_ISig_ 3 "InhibitStatus_NotAvailable" 2 "InhibitStatus_Reserved" 1 "InhibitStatus_Inhibited" 0 "InhibitStatus_NotInhibited" ;
VAL_ 2566749184 DPFC1_InhibDueSystemTimeout_ISig 3 "InhibitStatus_NotAvailable" 2 "InhibitStatus_Reserved" 1 "InhibitStatus_Inhibited" 0 "InhibitStatus_NotInhibited" ;
VAL_ 2566749184 DPFC1_InhibAccPedalOffIdle_ISig_ 3 "InhibitStatus_NotAvailable" 2 "InhibitStatus_Reserved" 1 "InhibitStatus_Inhibited" 0 "InhibitStatus_NotInhibited" ;
VAL_ 2566723046 DriverDoorOpen_stat_ISig_3 3 "DriverDoorOpen_stat_NotAvailable" 2 "DriverDoorOpen_stat_Error" 1 "DriverDoorOpen_stat_DriverDoorIsOpened" 0 "DriverDoorOpen_stat_DriverDoorIsClosed" ;
VAL_ 2566723046 PassengerDoorOpen_stat_ISig_3 3 "PassengerDoorOpen_stat_NotAvailable" 2 "PassengerDoorOpen_stat_Error" 1 "PassengerDoorOpen_stat_PassengerDoorIsOpened" 0 "PassengerDoorOpen_stat_PassengerDoorIsClosed" ;
VAL_ 2499790765 ACC_SGO_Status_ISig_3 15 "ACC_SGO_Status_NotAvailable" 14 "ACC_SGO_Status_Error" 13 "ACC_SGO_Status_Spare7" 12 "ACC_SGO_Status_Spare6" 11 "ACC_SGO_Status_Spare5" 10 "ACC_SGO_Status_Spare4" 9 "ACC_SGO_Status_Spare3" 8 "ACC_SGO_Status_Spare2" 7 "ACC_SGO_Status_Spare1" 6 "ACC_SGO_Status_ACC_SGO_Active_TakeOffRequest" 5 "ACC_SGO_Status_ACC_SGO_Active_Hold" 4 "ACC_SGO_Status_ACC_SGO_Active_Stationary" 3 "ACC_SGO_Status_ACC_SGO_Stopping" 2 "ACC_SGO_Status_ACC_SGO_Active_Driving" 1 "ACC_SGO_Status_ACC_SGO_Inactive" 0 "ACC_SGO_Status_ACC_SGO_OFF" ;
VAL_ 2499790765 ACCHSARequest 7 "ACCHSARequest_NotAvailable" 6 "ACCHSARequest_Error" 5 "ACCHSARequest_Spare3" 4 "ACCHSARequest_Spare2" 3 "ACCHSARequest_Spare1" 2 "ACCHSARequest_BrakingRequested_ACCInFollowingOrHoldControlMode" 1 "ACCHSARequest_NoBrakingRequested_ReleaseBrakesWhenSuitable" 0 "ACCHSARequest_NoBrakingRequested_ReleaseBrakesImmediately" ;
VAL_ 2499757105 ESCDriverReq 7 "ESCDriverReq_NotAvailable" 6 "ESCDriverReq_Error" 5 "ESCDriverReq_Spare02" 4 "ESCDriverReq_Spare01" 3 "ESCDriverReq_ESCOn" 2 "ESCDriverReq_ESCReduced" 1 "ESCDriverReq_ESCOff" 0 "ESCDriverReq_NoRequest" ;
VAL_ 2499757105 RrItrWhl1DiffLockActvnDrvrReq_IS 3 "DisengagedEngaged_NotAvailable" 2 "DisengagedEngaged_Error" 1 "DisengagedEngaged_Engaged" 0 "DisengagedEngaged_Disengaged" ;
VAL_ 2499757105 RearAxleSteeringFunctionDsbl_ISi 3 "RearAxleSteeringFunctionDsbl_NotAvailable" 2 "RearAxleSteeringFunctionDsbl_Error" 1 "RearAxleSteeringFunctionDsbl_DisableRequest" 0 "RearAxleSteeringFunctionDsbl_NoDisableRequest" ;
VAL_ 2499757105 RearAxleDiffLockActvnDrvrReq_ISi 3 "DisengageEngage_NotAvailable" 2 "DisengageEngage_Error" 1 "DisengageEngage_Engage" 0 "DisengageEngage_Disengage" ;
VAL_ 2499757105 RollerBenchModeRequest 3 "OffOn_NotAvailable" 2 "OffOn_Error" 1 "OffOn_On" 0 "OffOn_Off" ;
VAL_ 2499757105 ABSModeRequest 7 "ABSModeRequest_NotAvailable" 6 "ABSModeRequest_Error" 5 "ABSModeRequest_Spare3" 4 "ABSModeRequest_ABS_Inhibited" 3 "ABSModeRequest_Spare2" 2 "ABSModeRequest_ABS_OffRoad" 1 "ABSModeRequest_Spare1" 0 "ABSModeRequest_ABS_NormalMode" ;
VAL_ 2499757105 RrInterAxlDiffLockActvnDrvrReq_I 3 "DisengageEngage_NotAvailable" 2 "DisengageEngage_Error" 1 "DisengageEngage_Engage" 0 "DisengageEngage_Disengage" ;
VAL_ 2499757105 HSADriverRequest 3 "InactiveActive_NotAvailable" 2 "InactiveActive_Error" 1 "InactiveActive_Active" 0 "InactiveActive_Inactive" ;
VAL_ 2499757105 AutRrAxleDiffLockActvnDrvrReq 3 "DisengageEngage_NotAvailable" 2 "DisengageEngage_Error" 1 "DisengageEngage_Engage" 0 "DisengageEngage_Disengage" ;
VAL_ 2499757105 RrItrWhl2DiffLockActvnDrvrReq_IS 3 "DisengagedEngaged_NotAvailable" 2 "DisengagedEngaged_Error" 1 "DisengagedEngaged_Engaged" 0 "DisengagedEngaged_Disengaged" ;
VAL_ 2499757105 ABSInhibitionRequest 3 "OffOn_NotAvailable" 2 "OffOn_Error" 1 "OffOn_On" 0 "OffOn_Off" ;
VAL_ 2499757105 TractionControlDriverRqst_ISig_3 7 "TractionControlDriverRqst_NotAvailable" 6 "TractionControlDriverRqst_Error" 5 "TractionControlDriverRqst_Spare_01" 4 "TractionControlDriverRqst_Spare" 3 "TractionControlDriverRqst_TractionOFFROAD" 2 "TractionControlDriverRqst_TractionOFF" 1 "TractionControlDriverRqst_TractionON" 0 "TractionControlDriverRqst_NoAction" ;
VAL_ 2566844689 CCActive_ISig_3 3 "OffOn_NotAvailable" 2 "OffOn_Error" 1 "OffOn_On" 0 "OffOn_Off" ;
VAL_ 2566844689 BrakeSwitch_ISig_3 3 "BrakeSwitch_NotAvailable" 2 "BrakeSwitch_Error" 1 "BrakeSwitch_BrakePedalDepressed" 0 "BrakeSwitch_BrakePedalReleased" ;
VAL_ 2566844689 CruiseControlStates 7 "CruiseControlStates_NotAvailable" 6 "CruiseControlStates_AcceleratorOverride" 5 "CruiseControlStates_Set" 4 "CruiseControlStates_Resume" 3 "CruiseControlStates_Decelerate" 2 "CruiseControlStates_Accelerate" 1 "CruiseControlStates_Hold" 0 "CruiseControlStates_OffDisabled" ;
VAL_ 2566844689 ClutchSwitch_ISig_3 3 "ClutchSwitch_NotAvailable" 2 "ClutchSwitch_Error" 1 "ClutchSwitch_ClutchPedalDepressed" 0 "ClutchSwitch_ClutchPedalReleased" ;
VAL_ 2499779302 BBAirDumpRequest_ISig_3 3 "InactiveActive_NotAvailable" 2 "InactiveActive_Error" 1 "InactiveActive_Active" 0 "InactiveActive_Inactive" ;
VAL_ 2499779302 CtaBs_HSABbRequest_ISig_3 3 "Request_NotAvailable" 2 "Request_Error" 1 "Request_RequestActive" 0 "Request_NotRequested" ;
VAL_ 2566892605 LNGRestrictionStatus_Spare1_ISig 1 "InactiveActive1b_Active" 0 "InactiveActive1b_Inactive" ;
VAL_ 2566892605 LNGRestrictionStatus_Spare3_ISig 1 "InactiveActive1b_Active" 0 "InactiveActive1b_Inactive" ;
VAL_ 2566892605 LNGRestrictionStatus_V2Closed_IS 1 "InactiveActive1b_Active" 0 "InactiveActive1b_Inactive" ;
VAL_ 2566892605 LNGRestrictionStatus_Spare4_ISig 1 "InactiveActive1b_Active" 0 "InactiveActive1b_Inactive" ;
VAL_ 2566892605 LNGRestrictionStatus_V1Closed_IS 1 "InactiveActive1b_Active" 0 "InactiveActive1b_Inactive" ;
VAL_ 2566892605 LNGRestrictionStatus_Spare2_ISig 1 "InactiveActive1b_Active" 0 "InactiveActive1b_Inactive" ;
VAL_ 2566892605 LNGRestrictionStatus_SInfo_ISig_ 3 "SignalInfo2bitType_NotAvailable" 2 "SignalInfo2bitType_ErrorIndication" 1 "SignalInfo2bitType_Spare" 0 "SignalInfo2bitType_Valid" ;
VAL_ 2566892093 LngSystemReadinessStat_ISig_3 7 "LngSystemReadinessStat_NotAvailable" 6 "LngSystemReadinessStat_Error" 5 "LngSystemReadinessStat_Spare2" 4 "LngSystemReadinessStat_Spare1" 3 "LngSystemReadinessStat_LNGSystemReady" 2 "LngSystemReadinessStat_LNGInLimpingMode" 1 "LngSystemReadinessStat_LNGSystemWarmingUpPleaseWait" 0 "LngSystemReadinessStat_LNGSystemOff" ;
VAL_ 2566892093 MIStatusExtACM 3 "MIStatusExt_NotAvailable" 2 "MIStatusExt_Error" 1 "MIStatusExt_Ready" 0 "MIStatusExt_NotReady5Flash" ;
VAL_ 2566892093 CatalystTankLevelLow_ISig_3 3 "Warning_NotAvailable" 2 "Warning_Error" 1 "Warning_Warning" 0 "Warning_NoWarning" ;
VAL_ 2566892093 LngGspWarnStat 3 "OkPrepareToDerate_NotAvailable" 2 "OkPrepareToDerate_Error" 1 "OkPrepareToDerate_PrepareToDerate" 0 "OkPrepareToDerate_Ok" ;
VAL_ 2566892093 LngTank2WarnStat 3 "OkEmpty_NotAvailable" 2 "OkEmpty_Error" 1 "OkEmpty_Empty" 0 "OkEmpty_OK" ;
VAL_ 2566892093 MIDistinctWarningExtACM 15 "MIDistinctWarningExt_NotAvailable" 14 "MIDistinctWarningExt_Error" 3 "MIDistinctWarningExt_ContinuousMISteady" 2 "MIDistinctWarningExt_ShortMI3Flash" 1 "MIDistinctWarningExt_OnDemandMI2Flash" 0 "MIDistinctWarningExt_Off1Flash" ;
VAL_ 2566892093 LngTank1WarnStat 3 "OkEmpty_NotAvailable" 2 "OkEmpty_Error" 1 "OkEmpty_Empty" 0 "OkEmpty_OK" ;
SIG_GROUP_ 2566907915 DiagFaultStat_Brake_sg_ISig_3 1 : DiagFaultStat_Brake_FailTA_ISig_ DiagFaultStat_Brake_FailTB_ISig_ DiagFaultStat_Brake_DtcIdA_ISig_ DiagFaultStat_Brake_EcuAdr_ISig_ DiagFaultStat_Brake_DtcIdB_ISig_;
SIG_GROUP_ 2566907965 DiagFaultStat_ACM_sg_ISig_3 1 : DiagFaultStat_ACM_DtcIdB_ISig_3 DiagFaultStat_ACM_FailTA_ISig_3 DiagFaultStat_ACM_FailTB_ISig_3 DiagFaultStat_ACM_EcuAdr_ISig_3 DiagFaultStat_ACM_DtcIdA_ISig_3;
SIG_GROUP_ 2566749184 DPFC1_sg_ISig_3 1 : DPFC1_ActiveRegeneratStatus_ISig DPFC1_LampCommand_ISig_3 DPFC1_InhibTempSystemLock_ISig_3 DPFC1_InhibOutOfNeutral_ISig_3 DPFC1_InhibEnginNotWarmUp_ISig_3 DPFC1_InhibDueInhibSwitch_ISig_3 DPFC1_InhibClutchDisengage_ISig_ DPFC1_InhibVehSpdAboveAllwdSpd_I DPFC1_ForcedStatus_ISig_3 DPFC1_InhibPTOActive_ISig_3 DPFC1_InhibVehSpdBelowAllwdSpd_I DPFC1_InhibSystemFaultAct_ISig_3 DPFC1_PassiveRegenStatus_ISig_3 DPFC1_InhibPermSystemLock_ISig_3 DPFC1_AutoARInitConfig_ISig_3 DPFC1_InhibDueLowExhGasTemp_ISig DPFC1_ExhaustSystHighTempLampCmd DPFC1_InhibitStatus_ISig_3 DPFC1_DPFStatus_ISig_3 DPFC1_InhibParkBrakeNotSet_ISig_ DPFC1_InhibDueServiceBrake_ISig_ DPFC1_InhibDueSystemTimeout_ISig DPFC1_InhibAccPedalOffIdle_ISig_;
SIG_GROUP_ 2566892605 LNGRestrictionStatus_sg_ISig_3 1 : LNGRestrictionStatus_Spare1_ISig LNGRestrictionStatus_Spare3_ISig LNGRestrictionStatus_V2Closed_IS LNGRestrictionStatus_Spare4_ISig LNGRestrictionStatus_V1Closed_IS LNGRestrictionStatus_Spare2_ISig LNGRestrictionStatus_SInfo_ISig_;
